VERSION "HNNBNNNYNNNNNNNNNNNNNNNNNNNNNNNNNNNNNNNNNN/4/%%%/4/'%**4NNN///"

NS_ :

BS_:

BU_: AEM BAP_Tester E_Sound FLA Gateway Gateway_PAG ISE MRR_HL MRR_HR NightVision RDK SAK SAK2 SCR STH_MLBevo TopView

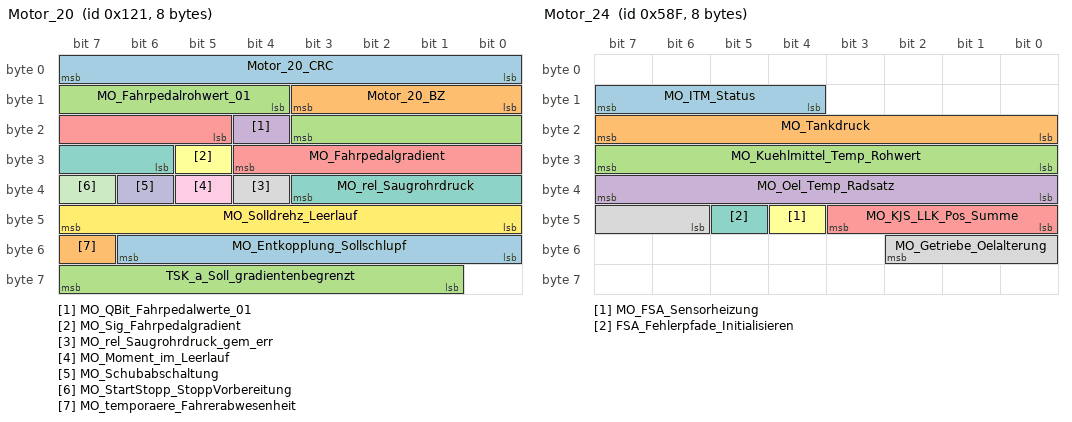
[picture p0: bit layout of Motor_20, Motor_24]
BO_ 289 Motor_20: 8 Gateway
 SG_ Motor_20_CRC : 0|8@1+ (1,0) [0|255] ""  Vector__XXX
 SG_ Motor_20_BZ : 8|4@1+ (1,0) [0|15] ""  Vector__XXX
 SG_ MO_Fahrpedalrohwert_01 : 12|8@1+ (0.4,0) [0.0|101.6] "Unit_PerCent"  E_Sound,ISE,SAK,SAK2
 SG_ MO_QBit_Fahrpedalwerte_01 : 20|1@1+ (1.0,0.0) [0.0|1] ""  Vector__XXX
 SG_ MO_Fahrpedalgradient : 21|8@1+ (25,0) [0|6350] "Unit_PerCentPerSecon"  Vector__XXX
 SG_ MO_Sig_Fahrpedalgradient : 29|1@1+ (1.0,0.0) [0.0|1] ""  Vector__XXX
 SG_ MO_rel_Saugrohrdruck : 30|6@1+ (18,0) [0|1116] "Unit_MilliBar"  Vector__XXX
 SG_ MO_rel_Saugrohrdruck_gem_err : 36|1@1+ (1.0,0.0) [0.0|1] ""  Vector__XXX
 SG_ MO_Moment_im_Leerlauf : 37|1@1+ (1.0,0.0) [0.0|1] ""  Vector__XXX
 SG_ MO_Schubabschaltung : 38|1@1+ (1.0,0.0) [0.0|1] ""  Vector__XXX
 SG_ MO_StartStopp_StoppVorbereitung : 39|1@1+ (1.0,0.0) [0.0|1] ""  Vector__XXX
 SG_ MO_Solldrehz_Leerlauf : 40|8@1+ (10,0) [0|2540] "Unit_MinutInver"  Vector__XXX
 SG_ MO_Entkopplung_Sollschlupf : 48|7@1+ (20,0) [0|2480] "Unit_MinutInver"  Vector__XXX
 SG_ MO_temporaere_Fahrerabwesenheit : 55|1@1+ (1.0,0.0) [0.0|1] ""  Vector__XXX
 SG_ TSK_a_Soll_gradientenbegrenzt : 57|7@1+ (0.1,-7.2) [-7.2|5.4] "Unit_MeterPerSeconSquar"  Vector__XXX

BO_ 1423 Motor_24: 8 Gateway
 SG_ MO_ITM_Status : 12|4@1+ (1.0,0.0) [0.0|15] ""  Vector__XXX
 SG_ MO_Tankdruck : 16|8@1+ (2,-250) [-250|256] "Unit_MilliBar"  STH_MLBevo
 SG_ MO_Kuehlmittel_Temp_Rohwert : 24|8@1+ (0.75,-48) [-48.00|141.75] "Unit_DegreCelsi"  Vector__XXX
 SG_ MO_Oel_Temp_Radsatz : 32|8@1+ (1,-60) [-60|193] "Unit_DegreCelsi"  Vector__XXX
 SG_ MO_KJS_LLK_Pos_Summe : 40|4@1+ (10,0) [0|100] "Unit_PerCent"  Vector__XXX
 SG_ MO_FSA_Sensorheizung : 44|1@1+ (1.0,0.0) [0.0|1] ""  Vector__XXX
 SG_ FSA_Fehlerpfade_Initialisieren : 45|1@1+ (1.0,0.0) [0.0|1] ""  Vector__XXX
 SG_ MO_Getriebe_Oelalterung : 46|5@1+ (5,0) [0|100] "Unit_PerCent"  Vector__XXX

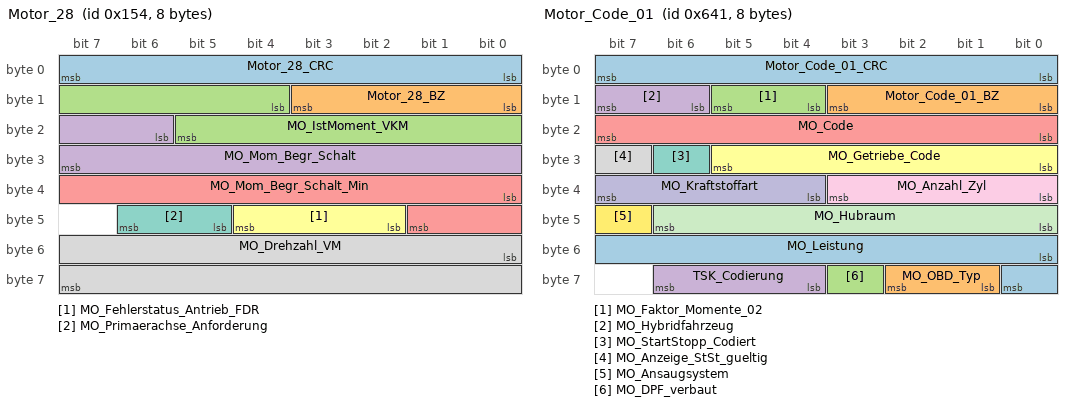
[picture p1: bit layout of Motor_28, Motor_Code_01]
BO_ 340 Motor_28: 8 Gateway
 SG_ Motor_28_CRC : 0|8@1+ (1,0) [0|255] ""  Vector__XXX
 SG_ Motor_28_BZ : 8|4@1+ (1,0) [0|15] ""  Vector__XXX
 SG_ MO_IstMoment_VKM : 12|10@1+ (1,-509) [-509|509] ""  Vector__XXX
 SG_ MO_Mom_Begr_Schalt : 22|10@1+ (1,-509) [-509|509] ""  Vector__XXX
 SG_ MO_Mom_Begr_Schalt_Min : 32|10@1+ (1,-509) [-509|509] ""  Vector__XXX
 SG_ MO_Fehlerstatus_Antrieb_FDR : 42|3@1+ (1.0,0.0) [0.0|7] ""  Vector__XXX
 SG_ MO_Primaerachse_Anforderung : 45|2@1+ (1.0,0.0) [0.0|3] ""  Vector__XXX
 SG_ MO_Drehzahl_VM : 48|16@1+ (0.25,0) [0.00|16383.00] "Unit_MinutInver"  AEM

BO_ 1601 Motor_Code_01: 8 Gateway
 SG_ Motor_Code_01_CRC : 0|8@1+ (1,0) [0|255] ""  Vector__XXX
 SG_ Motor_Code_01_BZ : 8|4@1+ (1,0) [0|15] ""  Vector__XXX
 SG_ MO_Faktor_Momente_02 : 12|2@1+ (1,0) [1|3] "Unit_NewtoMeter"  AEM
 SG_ MO_Hybridfahrzeug : 14|2@1+ (1.0,0.0) [0.0|3] ""  Vector__XXX
 SG_ MO_Code : 16|8@1+ (1,0) [0|255] ""  E_Sound,ISE,SAK,SAK2
 SG_ MO_Getriebe_Code : 24|6@1+ (1.0,0.0) [0.0|63] ""  Vector__XXX
 SG_ MO_StartStopp_Codiert : 30|1@1+ (1.0,0.0) [0.0|1] ""  Vector__XXX
 SG_ MO_Anzeige_StSt_gueltig : 31|1@1+ (1.0,0.0) [0.0|1] ""  Vector__XXX
 SG_ MO_Anzahl_Zyl : 32|4@1+ (1.0,0.0) [0.0|15] ""  Vector__XXX
 SG_ MO_Kraftstoffart : 36|4@1+ (1.0,0.0) [0.0|15] ""  STH_MLBevo
 SG_ MO_Hubraum : 40|7@1+ (0.1,0) [0.0|12.7] "Unit_Liter"  Vector__XXX
 SG_ MO_Ansaugsystem : 47|1@1+ (1.0,0.0) [0.0|1] ""  Vector__XXX
 SG_ MO_Leistung : 48|9@1+ (1,0) [0|511] "Unit_KiloWatt"  SAK,SAK2
 SG_ MO_OBD_Typ : 57|2@1+ (1.0,0.0) [0.0|3] ""  SCR
 SG_ MO_DPF_verbaut : 59|1@1+ (1.0,0.0) [0.0|1] ""  Vector__XXX
 SG_ TSK_Codierung : 60|3@1+ (1.0,0.0) [0.0|7] ""  Vector__XXX

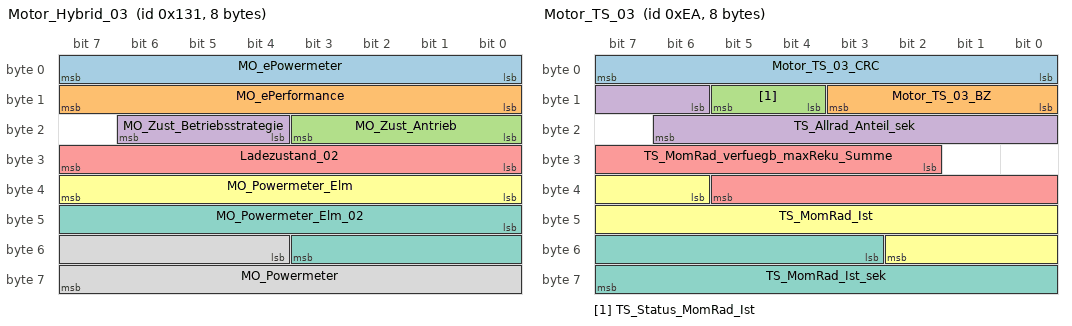
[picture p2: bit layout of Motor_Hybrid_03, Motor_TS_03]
BO_ 305 Motor_Hybrid_03: 8 Gateway
 SG_ MO_ePowermeter : 0|8@1+ (0.4,-0.4) [0.0|100.8] "Unit_PerCent"  Vector__XXX
 SG_ MO_ePerformance : 8|8@1+ (0.4,-0.4) [0.0|100.8] "Unit_PerCent"  Vector__XXX
 SG_ MO_Zust_Antrieb : 16|4@1+ (1.0,0.0) [0.0|15] ""  Vector__XXX
 SG_ MO_Zust_Betriebsstrategie : 20|3@1+ (1.0,0.0) [0.0|7] ""  Vector__XXX
 SG_ Ladezustand_02 : 24|8@1+ (0.5,0) [0.0|100.0] "Unit_PerCent"  Vector__XXX
 SG_ MO_Powermeter_Elm : 32|8@1+ (1,-128) [-100|100] "Unit_PerCent"  Vector__XXX
 SG_ MO_Powermeter_Elm_02 : 40|12@1+ (0.05,-102.4) [-100.00|100.00] "Unit_PerCent"  Vector__XXX
 SG_ MO_Powermeter : 52|12@1+ (1,0) [0|4092] ""  SAK,SAK2

BO_ 394 Motor_Hybrid_11: 8 Gateway
 SG_ MO_Ablaufstatus : 12|4@1+ (1.0,0.0) [0.0|15] ""  Vector__XXX
 SG_ MO_Ablaufstrg_Betriebszustand : 16|3@1+ (1.0,0.0) [0.0|7] ""  Vector__XXX
 SG_ MO_Ablaufstrg_Zustand_VKM_Ist : 19|1@1+ (1.0,0.0) [0.0|1] ""  Vector__XXX
 SG_ MO_Ablaufstrg_Kraftschluss_Ist : 20|1@1+ (1.0,0.0) [0.0|1] ""  Vector__XXX
 SG_ MO_Ablaufstrg_Zustand_K0_Ist : 21|1@1+ (1.0,0.0) [0.0|1] ""  Vector__XXX
 SG_ MO_Ablaufstrg_Kraftschluss2_Ist : 22|1@1+ (1.0,0.0) [0.0|1] ""  Vector__XXX
 SG_ MO_HYB_LowSpeedModus : 23|1@1+ (1.0,0.0) [0.0|1] ""  Vector__XXX
 SG_ MO_Ablaufstrg_Zustand_VKM_Ziel : 24|1@1+ (1.0,0.0) [0.0|1] ""  Vector__XXX
 SG_ MO_Ablaufstrg_Kraftschluss_Ziel : 25|1@1+ (1.0,0.0) [0.0|1] ""  Vector__XXX
 SG_ MO_Ablaufstrg_Zustand_K0_Ziel : 26|1@1+ (1.0,0.0) [0.0|1] ""  Vector__XXX
 SG_ MO_Ablaufstrg_Kraftschluss2_Ziel : 27|1@1+ (1.0,0.0) [0.0|1] ""  Vector__XXX
 SG_ MO_HYB_Stoppmodus : 28|1@1+ (1.0,0.0) [0.0|1] ""  Vector__XXX
 SG_ MO_Auth_Aufforderung_WFS : 29|1@1+ (1.0,0.0) [0.0|1] ""  Vector__XXX
 SG_ MO_Start_Dynamik : 30|3@1+ (1.0,0.0) [0.0|7] ""  Vector__XXX
 SG_ MO_Start_Art : 33|3@1+ (1.0,0.0) [0.0|7] ""  SCR
 SG_ MO_Abstellposition_02 : 36|8@1+ (2,0) [0|508] "Unit_DegreOfArc"  Vector__XXX
 SG_ MO_Mom_Freiheit_Sekundaerachse : 44|1@1+ (1.0,0.0) [0.0|1] ""  Vector__XXX
 SG_ MO_Nachlaufzeit_Kuehlerluefter : 45|6@1+ (15,0) [0|945] "Unit_Secon"  Vector__XXX
 SG_ MO_Tankklappensteuerung : 51|2@1+ (1.0,0.0) [0.0|3] ""  Vector__XXX
 SG_ MO_HYB_E_Faktor : 53|4@1+ (1.0,0.0) [0.0|15] ""  Vector__XXX
 SG_ MO_HYB_EMode_Info : 57|2@1+ (1.0,0.0) [0.0|3] ""  Vector__XXX
 SG_ MO_HYB_Adaption_aktiv : 59|1@1+ (1.0,0.0) [0.0|1] ""  Vector__XXX

BO_ 234 Motor_TS_03: 8 Gateway
 SG_ Motor_TS_03_CRC : 0|8@1+ (1,0) [0|255] ""  Vector__XXX
 SG_ Motor_TS_03_BZ : 8|4@1+ (1,0) [0|15] ""  Vector__XXX
 SG_ TS_Status_MomRad_Ist : 12|2@1+ (1.0,0.0) [0.0|3] ""  Vector__XXX
 SG_ TS_Allrad_Anteil_sek : 14|9@1+ (0.2,0) [0.0|100.0] "Unit_PerCent"  Vector__XXX
 SG_ TS_MomRad_verfuegb_maxReku_Summe : 26|12@1+ (3,-12279) [-12279|0] ""  Vector__XXX
 SG_ TS_MomRad_Ist : 38|13@1+ (3,-12279) [-12279|12279] "Unit_None"  Vector__XXX
 SG_ TS_MomRad_Ist_sek : 51|13@1+ (3,-12279) [-12279|12279] "Unit_None"  E_Sound,ISE

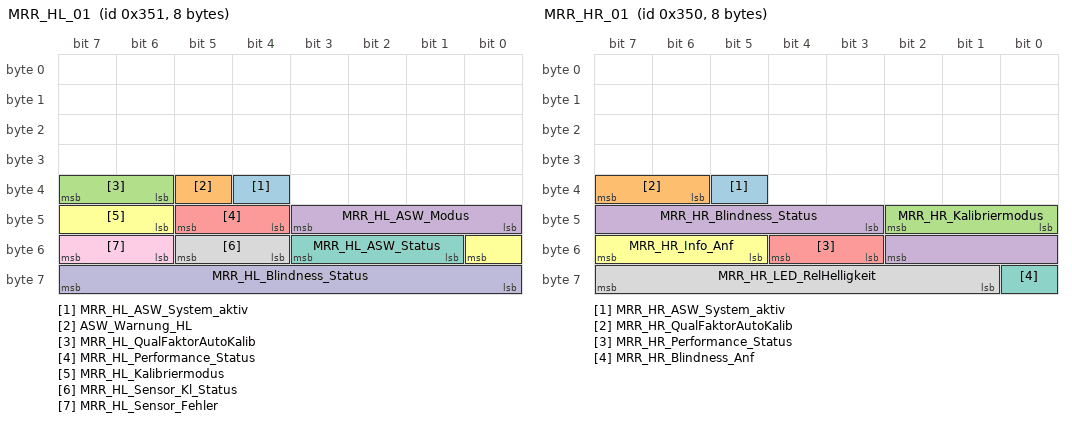
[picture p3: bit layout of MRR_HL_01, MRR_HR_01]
BO_ 849 MRR_HL_01: 8 MRR_HL
 SG_ MRR_HL_ASW_System_aktiv : 36|1@1+ (1.0,0.0) [0.0|1] ""  Gateway,Gateway_PAG,MRR_HR
 SG_ ASW_Warnung_HL : 37|1@1+ (1.0,0.0) [0.0|1] ""  Gateway,Gateway_PAG,MRR_HR
 SG_ MRR_HL_QualFaktorAutoKalib : 38|2@1+ (1.0,0.0) [0.0|3] ""  Gateway,Gateway_PAG,MRR_HR
 SG_ MRR_HL_ASW_Modus : 40|4@1+ (1.0,0.0) [0.0|15] ""  Gateway,Gateway_PAG,MRR_HR
 SG_ MRR_HL_Performance_Status : 44|2@1+ (1.0,0.0) [0.0|3] ""  Gateway,Gateway_PAG,MRR_HR
 SG_ MRR_HL_Kalibriermodus : 46|3@1+ (1.0,0.0) [0.0|7] ""  Gateway,Gateway_PAG,MRR_HR
 SG_ MRR_HL_ASW_Status : 49|3@1+ (1.0,0.0) [0.0|7] ""  Gateway,Gateway_PAG,MRR_HR
 SG_ MRR_HL_Sensor_Kl_Status : 52|2@1+ (1.0,0.0) [0.0|3] ""  Gateway,Gateway_PAG,MRR_HR
 SG_ MRR_HL_Sensor_Fehler : 54|2@1+ (1.0,0.0) [0.0|3] ""  Gateway,Gateway_PAG,MRR_HR
 SG_ MRR_HL_Blindness_Status : 56|8@1+ (1,0) [0|255] "Unit_None"  Gateway,Gateway_PAG,MRR_HR

BO_ 2463978596 MRR_HL_Info: 8 MRR_HL
 SG_ MRR_HL_Info1 : 0|32@1+ (1,0) [1|4294967295] "Unit_None"  MRR_HR

BO_ 848 MRR_HR_01: 8 MRR_HR
 SG_ MRR_HR_ASW_System_aktiv : 37|1@1+ (1.0,0.0) [0.0|1] ""  MRR_HL
 SG_ MRR_HR_QualFaktorAutoKalib : 38|2@1+ (1.0,0.0) [0.0|3] ""  MRR_HL
 SG_ MRR_HR_Kalibriermodus : 40|3@1+ (1.0,0.0) [0.0|7] ""  MRR_HL
 SG_ MRR_HR_Blindness_Status : 43|8@1+ (1,0) [0|255] "Unit_None"  MRR_HL
 SG_ MRR_HR_Performance_Status : 51|2@1+ (1.0,0.0) [0.0|3] ""  MRR_HL
 SG_ MRR_HR_Info_Anf : 53|3@1+ (1.0,0.0) [0.0|7] ""  MRR_HL
 SG_ MRR_HR_Blindness_Anf : 56|1@1+ (1.0,0.0) [0.0|1] ""  MRR_HL
 SG_ MRR_HR_LED_RelHelligkeit : 57|7@1+ (1,0) [0|127] "Unit_None"  MRR_HL

BO_ 1696 NightVision_01: 8 NightVision
 SG_ NV_aktiv : 12|1@1+ (1.0,0.0) [0.0|1] ""  Gateway,Gateway_PAG
 SG_ NV_Texte : 13|3@1+ (1.0,0.0) [0.0|7] ""  Gateway,Gateway_PAG
 SG_ NV_Gong : 16|2@1+ (1.0,0.0) [0.0|3] ""  Gateway,Gateway_PAG
 SG_ NV_Symbol : 18|1@1+ (1.0,0.0) [0.0|1] ""  Gateway,Gateway_PAG
 SG_ NV_Hinweise : 19|2@1+ (1.0,0.0) [0.0|3] ""  Gateway,Gateway_PAG
 SG_ NV_Piktogramm_aktiv : 21|1@1+ (1.0,0.0) [0.0|1] ""  Gateway,Gateway_PAG
 SG_ NV_Akustik_deaktiviert_Icon : 22|1@1+ (1.0,0.0) [0.0|1] ""  Gateway,Gateway_PAG
 SG_ NV_FGM_deaktiviert_Icon : 23|1@1+ (1.0,0.0) [0.0|1] ""  Gateway,Gateway_PAG
 SG_ NV_Markierungslicht_links : 24|1@1+ (1.0,0.0) [0.0|1] ""  Gateway,Gateway_PAG
 SG_ NV_Markierungslicht_rechts : 25|1@1+ (1.0,0.0) [0.0|1] ""  Gateway,Gateway_PAG
 SG_ NV_Symbol_Tierwarnung : 26|1@1+ (1.0,0.0) [0.0|1] ""  Gateway,Gateway_PAG
 SG_ NV_Anf_Prefill : 27|1@1+ (1.0,0.0) [0.0|1] ""  Gateway,Gateway_PAG
 SG_ NV_HBA_Parameter : 28|2@1+ (1.0,0.0) [0.0|3] ""  Gateway,Gateway_PAG
 SG_ NV_LED_Leiste : 30|2@1+ (1.0,0.0) [0.0|3] ""  Gateway,Gateway_PAG
 SG_ NV_PreSense_Status : 32|2@1+ (1.0,0.0) [0.0|3] ""  Gateway,Gateway_PAG
 SG_ NV_PreSense_Modus_System : 34|1@1+ (1.0,0.0) [0.0|1] ""  Gateway,Gateway_PAG
 SG_ NV_PreSense_Modus_Warnung : 35|3@1+ (1.0,0.0) [0.0|7] ""  Gateway,Gateway_PAG
 SG_ NV_FAS_Fkt_Status : 38|2@1+ (1.0,0.0) [0.0|3] ""  Gateway,Gateway_PAG
 SG_ NV_Akt_Status_MMI : 40|2@1+ (1.0,0.0) [0.0|3] ""  Gateway,Gateway_PAG
 SG_ NV_AnforderungBildaufschaltung : 42|1@1+ (1.0,0.0) [0.0|1] ""  Gateway,Gateway_PAG

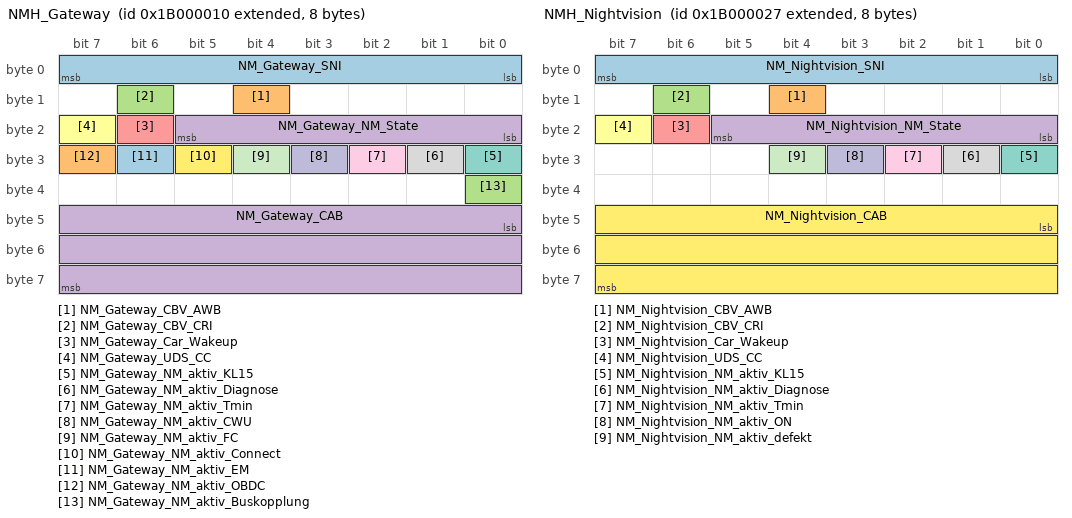
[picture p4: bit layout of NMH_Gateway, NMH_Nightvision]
BO_ 2600468496 NMH_Gateway: 8 Gateway
 SG_ NM_Gateway_SNI : 0|8@1+ (1.0,0.0) [0.0|255] ""  MRR_HL,MRR_HR,NightVision,RDK,SCR,STH_MLBevo,TopView
 SG_ NM_Gateway_CBV_AWB : 12|1@1+ (1.0,0.0) [0.0|1] ""  Vector__XXX
 SG_ NM_Gateway_CBV_CRI : 14|1@1+ (1.0,0.0) [0.0|1] ""  MRR_HL,MRR_HR,NightVision,RDK,SCR,STH_MLBevo,TopView
 SG_ NM_Gateway_NM_State : 16|6@1+ (1.0,0.0) [0.0|63] ""  Vector__XXX
 SG_ NM_Gateway_Car_Wakeup : 22|1@1+ (1.0,0.0) [0.0|1] ""  Vector__XXX
 SG_ NM_Gateway_UDS_CC : 23|1@1+ (1.0,0.0) [0.0|1] ""  Vector__XXX
 SG_ NM_Gateway_NM_aktiv_KL15 : 24|1@1+ (1.0,0.0) [0.0|1] ""  Vector__XXX
 SG_ NM_Gateway_NM_aktiv_Diagnose : 25|1@1+ (1.0,0.0) [0.0|1] ""  Vector__XXX
 SG_ NM_Gateway_NM_aktiv_Tmin : 26|1@1+ (1.0,0.0) [0.0|1] ""  Vector__XXX
 SG_ NM_Gateway_NM_aktiv_CWU : 27|1@1+ (1.0,0.0) [0.0|1] ""  Vector__XXX
 SG_ NM_Gateway_NM_aktiv_FC : 28|1@1+ (1.0,0.0) [0.0|1] ""  Vector__XXX
 SG_ NM_Gateway_NM_aktiv_Connect : 29|1@1+ (1.0,0.0) [0.0|1] ""  Vector__XXX
 SG_ NM_Gateway_NM_aktiv_EM : 30|1@1+ (1.0,0.0) [0.0|1] ""  Vector__XXX
 SG_ NM_Gateway_NM_aktiv_OBDC : 31|1@1+ (1.0,0.0) [0.0|1] ""  Vector__XXX
 SG_ NM_Gateway_NM_aktiv_Buskopplung : 32|1@1+ (1.0,0.0) [0.0|1] ""  Vector__XXX
 SG_ NM_Gateway_CAB : 40|24@1+ (1.0,0.0) [0.0|16777215] ""  MRR_HL,MRR_HR,NightVision,RDK,SCR,STH_MLBevo,TopView

BO_ 2600468519 NMH_Nightvision: 8 NightVision
 SG_ NM_Nightvision_SNI : 0|8@1+ (1.0,0.0) [0.0|255] ""  Gateway,Gateway_PAG,MRR_HL,MRR_HR,RDK,SCR,STH_MLBevo,TopView
 SG_ NM_Nightvision_CBV_AWB : 12|1@1+ (1.0,0.0) [0.0|1] ""  Gateway,Gateway_PAG
 SG_ NM_Nightvision_CBV_CRI : 14|1@1+ (1.0,0.0) [0.0|1] ""  Gateway,Gateway_PAG,MRR_HL,MRR_HR,RDK,SCR,STH_MLBevo,TopView
 SG_ NM_Nightvision_NM_State : 16|6@1+ (1.0,0.0) [0.0|63] ""  Vector__XXX
 SG_ NM_Nightvision_Car_Wakeup : 22|1@1+ (1.0,0.0) [0.0|1] ""  Gateway
 SG_ NM_Nightvision_UDS_CC : 23|1@1+ (1.0,0.0) [0.0|1] ""  Vector__XXX
 SG_ NM_Nightvision_NM_aktiv_KL15 : 24|1@1+ (1.0,0.0) [0.0|1] ""  Vector__XXX
 SG_ NM_Nightvision_NM_aktiv_Diagnose : 25|1@1+ (1.0,0.0) [0.0|1] ""  Vector__XXX
 SG_ NM_Nightvision_NM_aktiv_Tmin : 26|1@1+ (1.0,0.0) [0.0|1] ""  Vector__XXX
 SG_ NM_Nightvision_NM_aktiv_ON : 27|1@1+ (1.0,0.0) [0.0|1] ""  Vector__XXX
 SG_ NM_Nightvision_NM_aktiv_defekt : 28|1@1+ (1.0,0.0) [0.0|1] ""  Vector__XXX
 SG_ NM_Nightvision_CAB : 40|24@1+ (1.0,0.0) [0.0|16777215] ""  Gateway,Gateway_PAG,MRR_HL,MRR_HR,RDK,SCR,STH_MLBevo,TopView

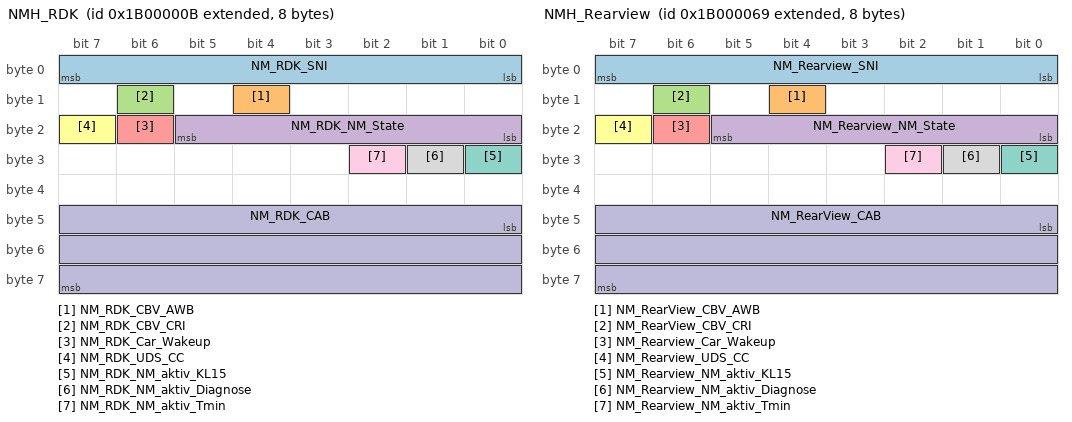
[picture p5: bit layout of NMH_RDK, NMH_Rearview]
BO_ 2600468491 NMH_RDK: 8 RDK
 SG_ NM_RDK_SNI : 0|8@1+ (1.0,0.0) [0.0|255] ""  Gateway,Gateway_PAG,MRR_HL,MRR_HR,NightVision,SCR,STH_MLBevo,TopView
 SG_ NM_RDK_CBV_AWB : 12|1@1+ (1.0,0.0) [0.0|1] ""  Gateway,Gateway_PAG
 SG_ NM_RDK_CBV_CRI : 14|1@1+ (1.0,0.0) [0.0|1] ""  Gateway,Gateway_PAG,MRR_HL,MRR_HR,NightVision,SCR,STH_MLBevo,TopView
 SG_ NM_RDK_NM_State : 16|6@1+ (1.0,0.0) [0.0|63] ""  Vector__XXX
 SG_ NM_RDK_Car_Wakeup : 22|1@1+ (1.0,0.0) [0.0|1] ""  Gateway,Gateway_PAG
 SG_ NM_RDK_UDS_CC : 23|1@1+ (1.0,0.0) [0.0|1] ""  Vector__XXX
 SG_ NM_RDK_NM_aktiv_KL15 : 24|1@1+ (1.0,0.0) [0.0|1] ""  Vector__XXX
 SG_ NM_RDK_NM_aktiv_Diagnose : 25|1@1+ (1.0,0.0) [0.0|1] ""  Vector__XXX
 SG_ NM_RDK_NM_aktiv_Tmin : 26|1@1+ (1.0,0.0) [0.0|1] ""  Vector__XXX
 SG_ NM_RDK_CAB : 40|24@1+ (1.0,0.0) [0.0|16777215] ""  Gateway,Gateway_PAG,MRR_HL,MRR_HR,NightVision,SCR,STH_MLBevo,TopView

BO_ 2600468585 NMH_Rearview: 8 TopView
 SG_ NM_Rearview_SNI : 0|8@1+ (1.0,0.0) [0.0|255] ""  Gateway,Gateway_PAG,MRR_HL,MRR_HR,NightVision,RDK,SCR,STH_MLBevo
 SG_ NM_RearView_CBV_AWB : 12|1@1+ (1.0,0.0) [0.0|1] ""  Gateway,Gateway_PAG
 SG_ NM_RearView_CBV_CRI : 14|1@1+ (1.0,0.0) [0.0|1] ""  Gateway,Gateway_PAG,MRR_HL,MRR_HR,NightVision,RDK,SCR,STH_MLBevo
 SG_ NM_Rearview_NM_State : 16|6@1+ (1.0,0.0) [0.0|63] ""  Vector__XXX
 SG_ NM_Rearview_Car_Wakeup : 22|1@1+ (1.0,0.0) [0.0|1] ""  Gateway
 SG_ NM_Rearview_UDS_CC : 23|1@1+ (1.0,0.0) [0.0|1] ""  Vector__XXX
 SG_ NM_Rearview_NM_aktiv_KL15 : 24|1@1+ (1.0,0.0) [0.0|1] ""  Vector__XXX
 SG_ NM_Rearview_NM_aktiv_Diagnose : 25|1@1+ (1.0,0.0) [0.0|1] ""  Vector__XXX
 SG_ NM_Rearview_NM_aktiv_Tmin : 26|1@1+ (1.0,0.0) [0.0|1] ""  Vector__XXX
 SG_ NM_RearView_CAB : 40|24@1+ (1.0,0.0) [0.0|16777215] ""  Gateway,Gateway_PAG,MRR_HL,MRR_HR,NightVision,RDK,SCR,STH_MLBevo

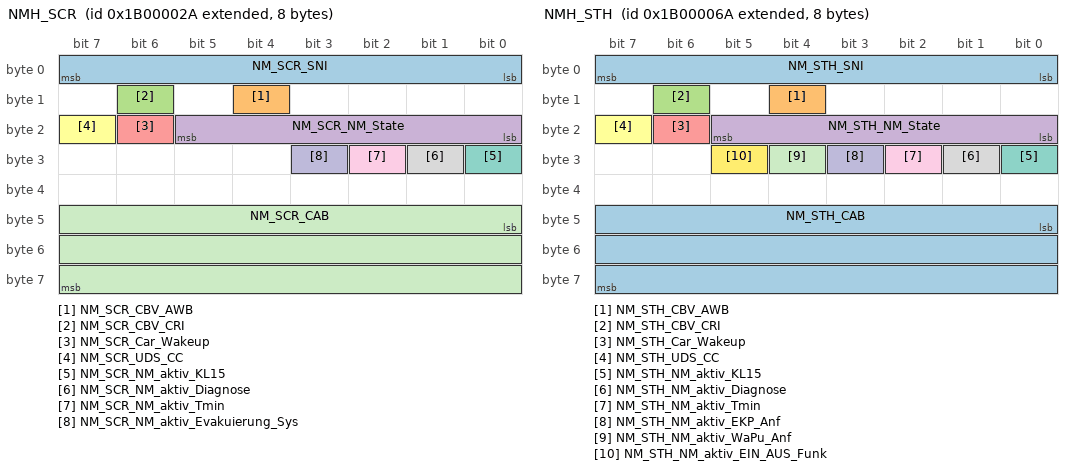
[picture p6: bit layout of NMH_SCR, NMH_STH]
BO_ 2600468522 NMH_SCR: 8 SCR
 SG_ NM_SCR_SNI : 0|8@1+ (1.0,0.0) [0.0|255] ""  Gateway,Gateway_PAG,MRR_HL,MRR_HR,NightVision,RDK,STH_MLBevo,TopView
 SG_ NM_SCR_CBV_AWB : 12|1@1+ (1.0,0.0) [0.0|1] ""  Gateway,Gateway_PAG
 SG_ NM_SCR_CBV_CRI : 14|1@1+ (1.0,0.0) [0.0|1] ""  Gateway,Gateway_PAG,MRR_HL,MRR_HR,NightVision,RDK,STH_MLBevo,TopView
 SG_ NM_SCR_NM_State : 16|6@1+ (1.0,0.0) [0.0|63] ""  Vector__XXX
 SG_ NM_SCR_Car_Wakeup : 22|1@1+ (1.0,0.0) [0.0|1] ""  Gateway,Gateway_PAG
 SG_ NM_SCR_UDS_CC : 23|1@1+ (1.0,0.0) [0.0|1] ""  Vector__XXX
 SG_ NM_SCR_NM_aktiv_KL15 : 24|1@1+ (1.0,0.0) [0.0|1] ""  Vector__XXX
 SG_ NM_SCR_NM_aktiv_Diagnose : 25|1@1+ (1.0,0.0) [0.0|1] ""  Vector__XXX
 SG_ NM_SCR_NM_aktiv_Tmin : 26|1@1+ (1.0,0.0) [0.0|1] ""  Vector__XXX
 SG_ NM_SCR_NM_aktiv_Evakuierung_Sys : 27|1@1+ (1.0,0.0) [0.0|1] ""  Vector__XXX
 SG_ NM_SCR_CAB : 40|24@1+ (1.0,0.0) [0.0|16777215] ""  Gateway,Gateway_PAG,MRR_HL,MRR_HR,NightVision,RDK,STH_MLBevo,TopView

BO_ 2600468586 NMH_STH: 8 STH_MLBevo
 SG_ NM_STH_SNI : 0|8@1+ (1.0,0.0) [0.0|255] ""  Gateway,Gateway_PAG,MRR_HL,MRR_HR,NightVision,RDK,SCR,TopView
 SG_ NM_STH_CBV_AWB : 12|1@1+ (1.0,0.0) [0.0|1] ""  Gateway,Gateway_PAG
 SG_ NM_STH_CBV_CRI : 14|1@1+ (1.0,0.0) [0.0|1] ""  Gateway,Gateway_PAG,MRR_HL,MRR_HR,NightVision,RDK,SCR,TopView
 SG_ NM_STH_NM_State : 16|6@1+ (1.0,0.0) [0.0|63] ""  Vector__XXX
 SG_ NM_STH_Car_Wakeup : 22|1@1+ (1.0,0.0) [0.0|1] ""  Gateway,Gateway_PAG
 SG_ NM_STH_UDS_CC : 23|1@1+ (1.0,0.0) [0.0|1] ""  Vector__XXX
 SG_ NM_STH_NM_aktiv_KL15 : 24|1@1+ (1.0,0.0) [0.0|1] ""  Vector__XXX
 SG_ NM_STH_NM_aktiv_Diagnose : 25|1@1+ (1.0,0.0) [0.0|1] ""  Vector__XXX
 SG_ NM_STH_NM_aktiv_Tmin : 26|1@1+ (1.0,0.0) [0.0|1] ""  Vector__XXX
 SG_ NM_STH_NM_aktiv_EKP_Anf : 27|1@1+ (1.0,0.0) [0.0|1] ""  Vector__XXX
 SG_ NM_STH_NM_aktiv_WaPu_Anf : 28|1@1+ (1.0,0.0) [0.0|1] ""  Vector__XXX
 SG_ NM_STH_NM_aktiv_EIN_AUS_Funk : 29|1@1+ (1.0,0.0) [0.0|1] ""  Vector__XXX
 SG_ NM_STH_CAB : 40|24@1+ (1.0,0.0) [0.0|16777215] ""  Gateway,Gateway_PAG,MRR_HL,MRR_HR,NightVision,RDK,SCR,TopView

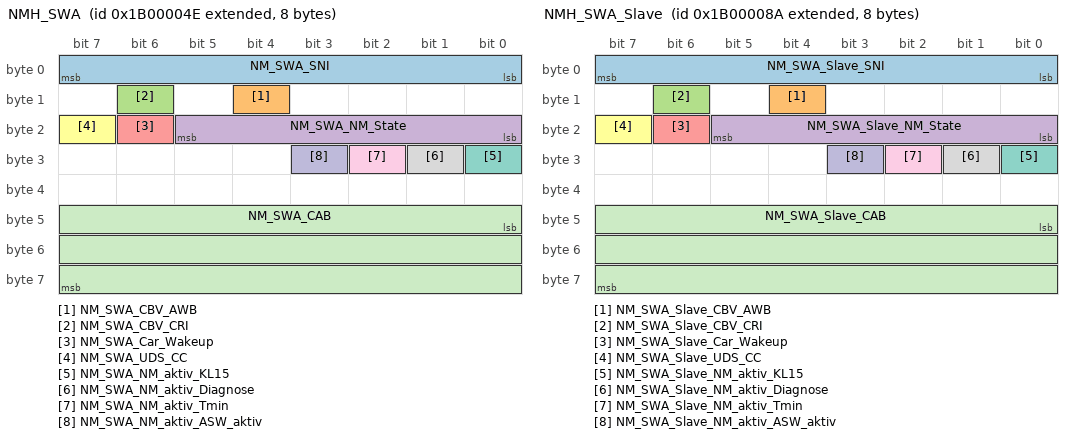
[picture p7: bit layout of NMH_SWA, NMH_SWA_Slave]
BO_ 2600468558 NMH_SWA: 8 MRR_HR
 SG_ NM_SWA_SNI : 0|8@1+ (1.0,0.0) [0.0|255] ""  Gateway,Gateway_PAG,MRR_HL,NightVision,RDK,SCR,STH_MLBevo,TopView
 SG_ NM_SWA_CBV_AWB : 12|1@1+ (1.0,0.0) [0.0|1] ""  Gateway,Gateway_PAG
 SG_ NM_SWA_CBV_CRI : 14|1@1+ (1.0,0.0) [0.0|1] ""  Gateway,Gateway_PAG,MRR_HL,NightVision,RDK,SCR,STH_MLBevo,TopView
 SG_ NM_SWA_NM_State : 16|6@1+ (1.0,0.0) [0.0|63] ""  Vector__XXX
 SG_ NM_SWA_Car_Wakeup : 22|1@1+ (1.0,0.0) [0.0|1] ""  Gateway,Gateway_PAG
 SG_ NM_SWA_UDS_CC : 23|1@1+ (1.0,0.0) [0.0|1] ""  Vector__XXX
 SG_ NM_SWA_NM_aktiv_KL15 : 24|1@1+ (1.0,0.0) [0.0|1] ""  Vector__XXX
 SG_ NM_SWA_NM_aktiv_Diagnose : 25|1@1+ (1.0,0.0) [0.0|1] ""  Vector__XXX
 SG_ NM_SWA_NM_aktiv_Tmin : 26|1@1+ (1.0,0.0) [0.0|1] ""  Vector__XXX
 SG_ NM_SWA_NM_aktiv_ASW_aktiv : 27|1@1+ (1.0,0.0) [0.0|1] ""  Vector__XXX
 SG_ NM_SWA_CAB : 40|24@1+ (1.0,0.0) [0.0|16777215] ""  Gateway,Gateway_PAG,MRR_HL,NightVision,RDK,SCR,STH_MLBevo,TopView

BO_ 2600468618 NMH_SWA_Slave: 8 MRR_HL
 SG_ NM_SWA_Slave_SNI : 0|8@1+ (1.0,0.0) [0.0|255] ""  Gateway,Gateway_PAG,MRR_HR,NightVision,RDK,SCR,STH_MLBevo,TopView
 SG_ NM_SWA_Slave_CBV_AWB : 12|1@1+ (1.0,0.0) [0.0|1] ""  Gateway,Gateway_PAG
 SG_ NM_SWA_Slave_CBV_CRI : 14|1@1+ (1.0,0.0) [0.0|1] ""  Gateway,Gateway_PAG,MRR_HR,NightVision,RDK,SCR,STH_MLBevo,TopView
 SG_ NM_SWA_Slave_NM_State : 16|6@1+ (1.0,0.0) [0.0|63] ""  Vector__XXX
 SG_ NM_SWA_Slave_Car_Wakeup : 22|1@1+ (1.0,0.0) [0.0|1] ""  Gateway
 SG_ NM_SWA_Slave_UDS_CC : 23|1@1+ (1.0,0.0) [0.0|1] ""  Vector__XXX
 SG_ NM_SWA_Slave_NM_aktiv_KL15 : 24|1@1+ (1.0,0.0) [0.0|1] ""  Vector__XXX
 SG_ NM_SWA_Slave_NM_aktiv_Diagnose : 25|1@1+ (1.0,0.0) [0.0|1] ""  Vector__XXX
 SG_ NM_SWA_Slave_NM_aktiv_Tmin : 26|1@1+ (1.0,0.0) [0.0|1] ""  Vector__XXX
 SG_ NM_SWA_Slave_NM_aktiv_ASW_aktiv : 27|1@1+ (1.0,0.0) [0.0|1] ""  Vector__XXX
 SG_ NM_SWA_Slave_CAB : 40|24@1+ (1.0,0.0) [0.0|16777215] ""  Gateway,Gateway_PAG,MRR_HR,NightVision,RDK,SCR,STH_MLBevo,TopView

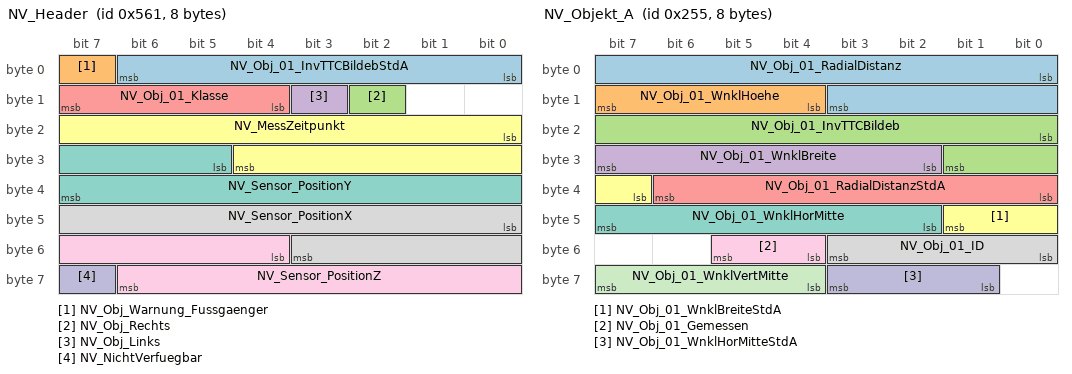
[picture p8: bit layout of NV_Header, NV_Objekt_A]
BO_ 1377 NV_Header: 8 NightVision
 SG_ NV_Obj_01_InvTTCBildebStdA : 0|7@1+ (0.0625,0) [0.0000|7.8750] "Unit_Hertz"  Gateway,Gateway_PAG
 SG_ NV_Obj_Warnung_Fussgaenger : 7|1@1+ (1.0,0.0) [0.0|1] ""  Gateway,Gateway_PAG
 SG_ NV_Obj_Rechts : 10|1@1+ (1.0,0.0) [0.0|1] ""  Gateway,Gateway_PAG
 SG_ NV_Obj_Links : 11|1@1+ (1.0,0.0) [0.0|1] ""  Gateway,Gateway_PAG
 SG_ NV_Obj_01_Klasse : 12|4@1+ (1.0,0.0) [0.0|15] ""  Gateway,Gateway_PAG
 SG_ NV_MessZeitpunkt : 16|13@1+ (0.001,0) [0.000|8.190] "Unit_Secon"  Gateway,Gateway_PAG
 SG_ NV_Sensor_PositionY : 29|11@1+ (0.001,-1) [-1.000|1.046] "Unit_Meter"  Gateway,Gateway_PAG
 SG_ NV_Sensor_PositionX : 40|12@1+ (0.001,1) [1.000|5.094] "Unit_Meter"  Gateway,Gateway_PAG
 SG_ NV_Sensor_PositionZ : 52|11@1+ (0.001,0) [0.000|2.046] "Unit_Meter"  Gateway,Gateway_PAG
 SG_ NV_NichtVerfuegbar : 63|1@1+ (1.0,0.0) [0.0|1] ""  Gateway,Gateway_PAG

BO_ 597 NV_Objekt_A: 8 NightVision
 SG_ NV_Obj_01_RadialDistanz : 0|12@1+ (0.0625,0) [0.0000|255.8750] "Unit_Meter"  Gateway,Gateway_PAG
 SG_ NV_Obj_01_WnklHoehe : 12|4@1+ (0.03125,0) [0.00000|0.43750] "Unit_Radia"  Gateway,Gateway_PAG
 SG_ NV_Obj_01_InvTTCBildeb : 16|10@1+ (0.015625,-8) [-8.000000|7.968750] "Unit_Hertz"  Gateway,Gateway_PAG
 SG_ NV_Obj_01_WnklBreite : 26|6@1+ (0.0078125,0) [0E-7|0.4843750] "Unit_Radia"  Gateway,Gateway_PAG
 SG_ NV_Obj_01_RadialDistanzStdA : 32|7@1+ (0.25,0) [0.00|31.50] "Unit_Meter"  Gateway,Gateway_PAG
 SG_ NV_Obj_01_WnklBreiteStdA : 39|3@1+ (0.015625,0) [0.000000|0.093750] "Unit_Radia"  Gateway,Gateway_PAG
 SG_ NV_Obj_01_WnklHorMitte : 42|6@1+ (0.0078125,-0.2421875) [-0.2421875|0.2421875] "Unit_Radia"  Gateway,Gateway_PAG
 SG_ NV_Obj_01_ID : 48|4@1+ (1.0,0.0) [0.0|15] ""  Gateway,Gateway_PAG
 SG_ NV_Obj_01_Gemessen : 52|2@1+ (1.0,0.0) [0.0|3] ""  Gateway,Gateway_PAG
 SG_ NV_Obj_01_WnklHorMitteStdA : 57|3@1+ (0.015625,0) [0.000000|0.093750] "Unit_Radia"  Gateway,Gateway_PAG
 SG_ NV_Obj_01_WnklVertMitte : 60|4@1+ (0.03125,-0.21875) [-0.21875|0.21875] "Unit_Radia"  Gateway,Gateway_PAG

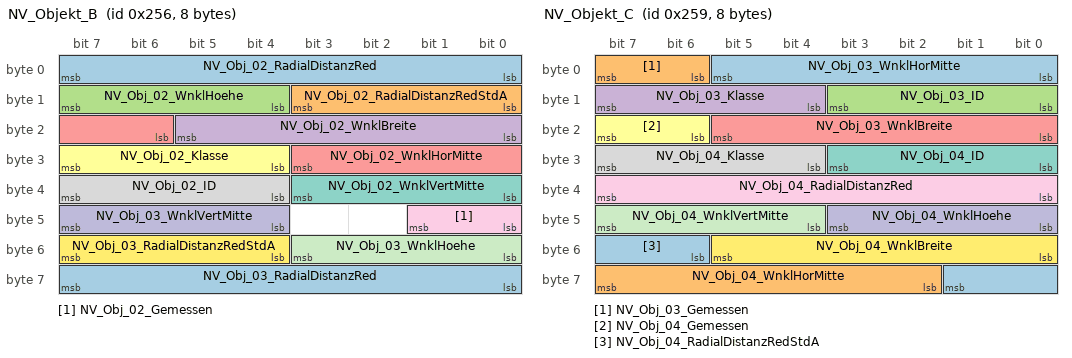
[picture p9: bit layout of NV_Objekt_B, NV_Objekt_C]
BO_ 598 NV_Objekt_B: 8 NightVision
 SG_ NV_Obj_02_RadialDistanzRed : 0|8@1+ (0.5,3) [3.0|130.0] "Unit_Meter"  Gateway,Gateway_PAG
 SG_ NV_Obj_02_RadialDistanzRedStdA : 8|4@1+ (1,0) [0|14] "Unit_Meter"  Gateway,Gateway_PAG
 SG_ NV_Obj_02_WnklHoehe : 12|4@1+ (0.03125,0) [0.00000|0.43750] "Unit_Radia"  Gateway,Gateway_PAG
 SG_ NV_Obj_02_WnklBreite : 16|6@1+ (0.0078125,0) [0E-7|0.4843750] "Unit_Radia"  Gateway,Gateway_PAG
 SG_ NV_Obj_02_WnklHorMitte : 22|6@1+ (0.0078125,-0.2421875) [-0.2421875|0.2421875] "Unit_Radia"  Gateway,Gateway_PAG
 SG_ NV_Obj_02_Klasse : 28|4@1+ (1.0,0.0) [0.0|15] ""  Gateway,Gateway_PAG
 SG_ NV_Obj_02_WnklVertMitte : 32|4@1+ (0.03125,-0.21875) [-0.21875|0.21875] "Unit_Radia"  Gateway,Gateway_PAG
 SG_ NV_Obj_02_ID : 36|4@1+ (1.0,0.0) [0.0|15] ""  Gateway,Gateway_PAG
 SG_ NV_Obj_02_Gemessen : 40|2@1+ (1.0,0.0) [0.0|3] ""  Gateway,Gateway_PAG
 SG_ NV_Obj_03_WnklVertMitte : 44|4@1+ (0.03125,-0.21875) [-0.21875|0.21875] "Unit_Radia"  Gateway,Gateway_PAG
 SG_ NV_Obj_03_WnklHoehe : 48|4@1+ (0.03125,0) [0.00000|0.43750] "Unit_Radia"  Gateway,Gateway_PAG
 SG_ NV_Obj_03_RadialDistanzRedStdA : 52|4@1+ (1,0) [0|14] "Unit_Meter"  Gateway,Gateway_PAG
 SG_ NV_Obj_03_RadialDistanzRed : 56|8@1+ (0.5,3) [3.0|130.0] "Unit_Meter"  Gateway,Gateway_PAG

BO_ 601 NV_Objekt_C: 8 NightVision
 SG_ NV_Obj_03_WnklHorMitte : 0|6@1+ (0.0078125,-0.2421875) [-0.2421875|0.2421875] "Unit_Radia"  Gateway,Gateway_PAG
 SG_ NV_Obj_03_Gemessen : 6|2@1+ (1.0,0.0) [0.0|3] ""  Gateway,Gateway_PAG
 SG_ NV_Obj_03_ID : 8|4@1+ (1.0,0.0) [0.0|15] ""  Gateway,Gateway_PAG
 SG_ NV_Obj_03_Klasse : 12|4@1+ (1.0,0.0) [0.0|15] ""  Gateway,Gateway_PAG
 SG_ NV_Obj_03_WnklBreite : 16|6@1+ (0.0078125,0) [0E-7|0.4843750] "Unit_Radia"  Gateway,Gateway_PAG
 SG_ NV_Obj_04_Gemessen : 22|2@1+ (1.0,0.0) [0.0|3] ""  Gateway,Gateway_PAG
 SG_ NV_Obj_04_ID : 24|4@1+ (1.0,0.0) [0.0|15] ""  Gateway,Gateway_PAG
 SG_ NV_Obj_04_Klasse : 28|4@1+ (1.0,0.0) [0.0|15] ""  Gateway,Gateway_PAG
 SG_ NV_Obj_04_RadialDistanzRed : 32|8@1+ (0.5,3) [3.0|130.0] "Unit_Meter"  Gateway,Gateway_PAG
 SG_ NV_Obj_04_WnklHoehe : 40|4@1+ (0.03125,0) [0.00000|0.43750] "Unit_Radia"  Gateway,Gateway_PAG
 SG_ NV_Obj_04_WnklVertMitte : 44|4@1+ (0.03125,-0.21875) [-0.21875|0.21875] "Unit_Radia"  Gateway,Gateway_PAG
 SG_ NV_Obj_04_WnklBreite : 48|6@1+ (0.0078125,0) [0E-7|0.4843750] "Unit_Radia"  Gateway,Gateway_PAG
 SG_ NV_Obj_04_RadialDistanzRedStdA : 54|4@1+ (1,0) [0|14] "Unit_Meter"  Gateway,Gateway_PAG
 SG_ NV_Obj_04_WnklHorMitte : 58|6@1+ (0.0078125,-0.2421875) [-0.2421875|0.2421875] "Unit_Radia"  Gateway,Gateway_PAG

BO_ 1635 NVEM_02: 8 Gateway
 SG_ BEM_02_Abschaltstufen : 0|3@1+ (1.0,0.0) [0.0|7] ""  MRR_HL,MRR_HR,STH_MLBevo
 SG_ BEM_STH_Zielzeit : 3|4@1+ (5,0) [0|60] "Unit_Minut"  Vector__XXX
 SG_ BEM_MMI_Vorwarnung : 7|1@1+ (1.0,0.0) [0.0|1] ""  Vector__XXX
 SG_ NVEM_Anf_SD_schalten : 15|1@1+ (1.0,0.0) [0.0|1] ""  Vector__XXX
 SG_ BEM_Generatordiagnose : 16|2@1+ (1.0,0.0) [0.0|3] ""  Vector__XXX
 SG_ BEM_Red_Innengeblaese : 18|2@1+ (1.0,0.0) [0.0|3] ""  Vector__XXX
 SG_ BEM_STH_Einschaltverbot : 20|1@1+ (1.0,0.0) [0.0|1] ""  STH_MLBevo
 SG_ BEM_HL_Regelung_Status : 21|3@1+ (1.0,0.0) [0.0|7] ""  STH_MLBevo
 SG_ BEM_Ladezustand : 24|4@1+ (10,0) [0|100] "Unit_PerCent"  Vector__XXX
 SG_ BEM_Batteriediagnose : 28|3@1+ (1.0,0.0) [0.0|7] ""  Vector__XXX
 SG_ MIB_Stromsparmodus : 31|1@1+ (1.0,0.0) [0.0|1] ""  Vector__XXX
 SG_ BEM_REK_aktiv : 37|1@1+ (1.0,0.0) [0.0|1] ""  Vector__XXX
 SG_ NVEM_Last_Anf : 38|2@1+ (1.0,0.0) [0.0|3] ""  Vector__XXX
 SG_ BEM_UBDM : 40|8@1+ (0.05,5) [5.05|17.70] "Unit_Volt"  Vector__XXX
 SG_ BEM_UGenSoll : 48|6@1+ (0.1,10.6) [10.6|16.0] "Unit_Volt"  Vector__XXX
 SG_ BEM_Anf_KL15_schalten : 54|2@1+ (1.0,0.0) [0.0|3] ""  MRR_HL,MRR_HR
 SG_ NVEM_Batterie_Service : 56|2@1+ (1.0,0.0) [0.0|3] ""  Vector__XXX
 SG_ NVEM_Freigabe_OnlineUpdate : 58|1@1+ (1.0,0.0) [0.0|1] ""  Vector__XXX
 SG_ NVEM_Freigabe_ORU4 : 59|2@1+ (1.0,0.0) [0.0|3] ""  Vector__XXX

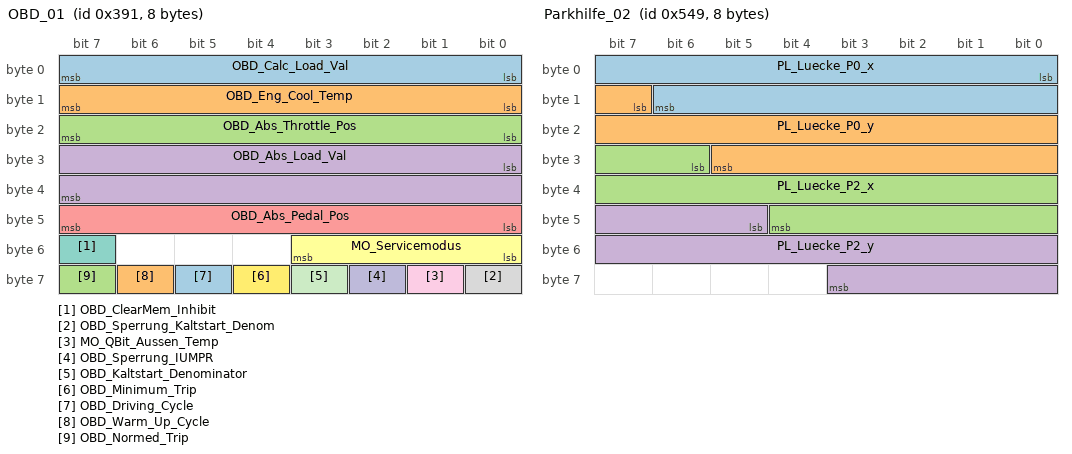
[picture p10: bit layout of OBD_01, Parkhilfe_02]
BO_ 913 OBD_01: 8 Gateway
 SG_ OBD_Calc_Load_Val : 0|8@1+ (0.39215686274509803,0) [0E-17|99.99999999999999765] "Unit_PerCent"  SCR
 SG_ OBD_Eng_Cool_Temp : 8|8@1+ (1,-40) [-40|215] "Unit_DegreCelsi"  SCR
 SG_ OBD_Abs_Throttle_Pos : 16|8@1+ (0.39215686274509803,0) [0E-17|99.99999999999999765] "Unit_PerCent"  SCR
 SG_ OBD_Abs_Load_Val : 24|16@1+ (0.39215686274509803,0) [0E-17|25699.99999999999939605] "Unit_PerCent"  SCR
 SG_ OBD_Abs_Pedal_Pos : 40|8@1+ (0.39215686274509803,0) [0E-17|99.99999999999999765] "Unit_PerCent"  SCR
 SG_ MO_Servicemodus : 48|4@1+ (1.0,0.0) [0.0|15] ""  Vector__XXX
 SG_ OBD_ClearMem_Inhibit : 55|1@1+ (1.0,0.0) [0.0|1] ""  Vector__XXX
 SG_ OBD_Sperrung_Kaltstart_Denom : 56|1@1+ (1.0,0.0) [0.0|1] ""  Vector__XXX
 SG_ MO_QBit_Aussen_Temp : 57|1@1+ (1.0,0.0) [0.0|1] ""  SCR
 SG_ OBD_Sperrung_IUMPR : 58|1@1+ (1.0,0.0) [0.0|1] ""  SCR
 SG_ OBD_Kaltstart_Denominator : 59|1@1+ (1.0,0.0) [0.0|1] ""  SCR
 SG_ OBD_Minimum_Trip : 60|1@1+ (1.0,0.0) [0.0|1] ""  SCR
 SG_ OBD_Driving_Cycle : 61|1@1+ (1.0,0.0) [0.0|1] ""  SCR
 SG_ OBD_Warm_Up_Cycle : 62|1@1+ (1.0,0.0) [0.0|1] ""  SCR
 SG_ OBD_Normed_Trip : 63|1@1+ (1.0,0.0) [0.0|1] ""  SCR

BO_ 2589283478 OBD_02: 8 Gateway
 SG_ OBD_Aussen_Temp_gef : 56|8@1+ (1,-40) [-40|213] "Unit_DegreCelsi"  SCR

BO_ 2549875246 OBDC_AEM_Req: 8 Gateway
 SG_ OBDC_AEM_Req_Data : 0|64@1+ (1.0,0.0) [0.0|18446744073709551615] ""  AEM

BO_ 2550006318 OBDC_AEM_Resp: 8 AEM
 SG_ OBDC_AEM_Resp_Data : 0|64@1+ (1.0,0.0) [0.0|18446744073709551615] ""  Gateway,Gateway_PAG

BO_ 2549875248 OBDC_FLA_Req: 8 Gateway
 SG_ OBDC_FLA_Req_Data : 0|64@1+ (1.0,0.0) [0.0|18446744073709551615] ""  FLA

BO_ 2550006320 OBDC_FLA_Resp: 8 FLA
 SG_ OBDC_FLA_Resp_Data : 0|64@1+ (1.0,0.0) [0.0|18446744073709551615] ""  Gateway,Gateway_PAG

BO_ 2549940736 OBDC_Funktionaler_Req_All: 8 Gateway
 SG_ OBDC_Funktionaler_Req_All_Data : 0|64@1+ (1.0,0.0) [0.0|18446744073709551615] ""  AEM,E_Sound,FLA,ISE,MRR_HL,MRR_HR,NightVision,RDK,SAK,SAK2,SCR,STH_MLBevo,TopView

BO_ 2549875239 OBDC_Nightvision_Req: 8 Gateway
 SG_ OBDC_Nightvision_Req_Data : 0|64@1+ (1.0,0.0) [0.0|18446744073709551615] ""  NightVision

BO_ 2550006311 OBDC_Nightvision_Resp: 8 NightVision
 SG_ OBDC_Nightvision_Resp_Data : 0|64@1+ (1.0,0.0) [0.0|18446744073709551615] ""  Gateway,Gateway_PAG

BO_ 2549875211 OBDC_RDK_Req: 8 Gateway
 SG_ OBDC_RDK_Req_Data : 0|64@1+ (1.0,0.0) [0.0|18446744073709551615] ""  RDK

BO_ 2550006283 OBDC_RDK_Resp: 8 RDK
 SG_ OBDC_RDK_Resp_Data : 0|64@1+ (1.0,0.0) [0.0|18446744073709551615] ""  Gateway,Gateway_PAG

BO_ 2549875305 OBDC_Rearview_Req: 8 Gateway
 SG_ OBDC_Rearview_Req_Data : 0|64@1+ (1.0,0.0) [0.0|18446744073709551615] ""  TopView

BO_ 2550006377 OBDC_Rearview_Resp: 8 TopView
 SG_ OBDC_Rearview_Resp_Data : 0|64@1+ (1.0,0.0) [0.0|18446744073709551615] ""  Gateway,Gateway_PAG

BO_ 2549875242 OBDC_SCR_Req: 8 Gateway
 SG_ OBDC_SCR_Req_Data : 0|64@1+ (1.0,0.0) [0.0|18446744073709551615] ""  SCR

BO_ 2550006314 OBDC_SCR_Resp: 8 SCR
 SG_ OBDC_SCR_Resp_Data : 0|64@1+ (1.0,0.0) [0.0|18446744073709551615] ""  Gateway,Gateway_PAG

BO_ 2549875300 OBDC_Soundaktor2_Req: 8 Gateway
 SG_ OBDC_Soundaktor2_Req_Data : 0|64@1+ (1.0,0.0) [0.0|18446744073709551615] ""  E_Sound,SAK2

BO_ 2550006372 OBDC_Soundaktor2_Resp: 8 E_Sound
 SG_ OBDC_Soundaktor2_Resp_Data : 0|64@1+ (1.0,0.0) [0.0|18446744073709551615] ""  Gateway,Gateway_PAG

BO_ 2549875228 OBDC_Soundaktor_Req: 8 Gateway
 SG_ OBDC_Soundaktor_Req_Data : 0|64@1+ (1.0,0.0) [0.0|18446744073709551615] ""  ISE,SAK

BO_ 2550006300 OBDC_Soundaktor_Resp: 8 ISE
 SG_ OBDC_Soundaktor_Resp_Data : 0|64@1+ (1.0,0.0) [0.0|18446744073709551615] ""  Gateway,Gateway_PAG

BO_ 2549875306 OBDC_STH_Req: 8 Gateway
 SG_ OBDC_STH_Req_Data : 0|64@1+ (1.0,0.0) [0.0|18446744073709551615] ""  STH_MLBevo

BO_ 2550006378 OBDC_STH_Resp: 8 STH_MLBevo
 SG_ OBDC_STH_Resp_Data : 0|64@1+ (1.0,0.0) [0.0|18446744073709551615] ""  Gateway,Gateway_PAG

BO_ 2549875338 OBDC_SWA_2_Req: 8 Gateway
 SG_ OBDC_SWA_2_Req_Data : 0|64@1+ (1.0,0.0) [0.0|18446744073709551615] ""  MRR_HL

BO_ 2550006410 OBDC_SWA_2_Resp: 8 MRR_HL
 SG_ OBDC_SWA_2_Resp_Data : 0|64@1+ (1.0,0.0) [0.0|18446744073709551615] ""  Gateway,Gateway_PAG

BO_ 2549875278 OBDC_SWA_Req: 8 Gateway
 SG_ OBDC_SWA_Req_Data : 0|64@1+ (1.0,0.0) [0.0|18446744073709551615] ""  MRR_HR

BO_ 2550006350 OBDC_SWA_Resp: 8 MRR_HR
 SG_ OBDC_SWA_Resp_Data : 0|64@1+ (1.0,0.0) [0.0|18446744073709551615] ""  Gateway,Gateway_PAG

BO_ 2589283656 ORU_01: 8 Gateway
 SG_ ORU_Warnung : 58|2@1+ (1.0,0.0) [0.0|3] ""  Vector__XXX
 SG_ ORU_Status : 61|3@1+ (1.0,0.0) [0.0|7] ""  Vector__XXX

BO_ 1175 Parkhilfe_01: 8 Gateway
 SG_ PH_Visualisierung : 0|3@1+ (1.0,0.0) [0.0|7] ""  TopView
 SG_ PDC_Tonausgabe_Front : 4|4@1+ (1.0,0.0) [0.0|15] ""  Vector__XXX
 SG_ PDC_Tonausgabe_Heck : 8|4@1+ (1.0,0.0) [0.0|15] ""  Vector__XXX
 SG_ PH_nachtr_Stopp_Anf : 12|1@1+ (1.0,0.0) [0.0|1] ""  Vector__XXX
 SG_ PH_Abschaltursache : 13|3@1+ (1.0,0.0) [0.0|7] ""  Vector__XXX
 SG_ PH_Opt_Anzeige_V_ein : 16|1@1+ (1.0,0.0) [0.0|1] ""  Vector__XXX
 SG_ PH_Opt_Anzeige_H_ein : 17|1@1+ (1.0,0.0) [0.0|1] ""  Vector__XXX
 SG_ PH_Opt_Anz_V_Hindernis : 18|1@1+ (1.0,0.0) [0.0|1] ""  Vector__XXX
 SG_ PH_Opt_Anz_H_Hindernis : 19|1@1+ (1.0,0.0) [0.0|1] ""  Vector__XXX
 SG_ PH_Tongeber_V_aktiv : 20|1@1+ (1.0,0.0) [0.0|1] ""  Vector__XXX
 SG_ PH_Tongeber_H_aktiv : 21|1@1+ (1.0,0.0) [0.0|1] ""  Vector__XXX
 SG_ PH_Tongeber_mute : 22|1@1+ (1.0,0.0) [0.0|1] ""  Vector__XXX
 SG_ PH_Anf_Audioabsenkung : 23|1@1+ (1.0,0.0) [0.0|1] ""  Vector__XXX
 SG_ PH_Tongeber_H_verfuegbar : 24|1@1+ (1.0,0.0) [0.0|1] ""  Vector__XXX
 SG_ PLA_Anf_Aufschaltung_RVC : 25|1@1+ (1.0,0.0) [0.0|1] ""  TopView
 SG_ PH_Taster : 28|2@1+ (1.0,0.0) [0.0|3] ""  TopView
 SG_ PH_Anf_Verdeck : 30|2@1+ (1.0,0.0) [0.0|3] ""  Vector__XXX
 SG_ PH_Frequenz_hinten : 32|4@1+ (1,0) [0|15] ""  Vector__XXX
 SG_ PH_Lautstaerke_hinten : 36|4@1+ (1,0) [0|15] ""  Vector__XXX
 SG_ PH_Frequenz_vorn : 40|4@1+ (1,0) [0|15] ""  Vector__XXX
 SG_ PH_Lautstaerke_vorn : 44|4@1+ (1,0) [0|15] ""  Vector__XXX
 SG_ PH_StartStopp_Info : 49|2@1+ (1.0,0.0) [0.0|3] ""  Vector__XXX
 SG_ PH_Stoermeldung : 52|4@1+ (1.0,0.0) [0.0|15] ""  Vector__XXX
 SG_ PH_defekt : 56|1@1+ (1.0,0.0) [0.0|1] ""  Vector__XXX
 SG_ PH_gestoert : 57|1@1+ (1.0,0.0) [0.0|1] ""  Vector__XXX
 SG_ PH_Systemzustand : 58|3@1+ (1.0,0.0) [0.0|7] ""  TopView
 SG_ PH_Display_Kundenwunsch : 61|2@1+ (1.0,0.0) [0.0|3] ""  Vector__XXX

BO_ 1353 Parkhilfe_02: 8 Gateway
 SG_ PL_Luecke_P0_x : 0|15@1+ (2,-32767) [-32767|32767] "Unit_Centimeter"  TopView
 SG_ PL_Luecke_P0_y : 15|15@1+ (2,-32767) [-32767|32767] "Unit_Centimeter"  TopView
 SG_ PL_Luecke_P2_x : 30|15@1+ (2,-32767) [-32767|32767] "Unit_Centimeter"  TopView
 SG_ PL_Luecke_P2_y : 45|15@1+ (2,-32767) [-32767|32767] "Unit_Centimeter"  TopView

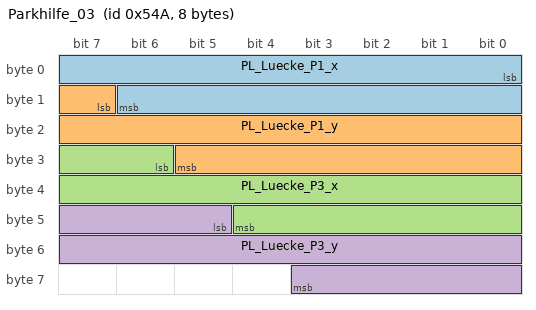
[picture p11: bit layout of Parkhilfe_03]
BO_ 1354 Parkhilfe_03: 8 Gateway
 SG_ PL_Luecke_P1_x : 0|15@1+ (2,-32767) [-32767|32767] "Unit_Centimeter"  TopView
 SG_ PL_Luecke_P1_y : 15|15@1+ (2,-32767) [-32767|32767] "Unit_Centimeter"  TopView
 SG_ PL_Luecke_P3_x : 30|15@1+ (2,-32767) [-32767|32767] "Unit_Centimeter"  TopView
 SG_ PL_Luecke_P3_y : 45|15@1+ (2,-32767) [-32767|32767] "Unit_Centimeter"  TopView

BO_TX_BU_ 289 :Gateway,Gateway_PAG;
BO_TX_BU_ 1423 :Gateway,Gateway_PAG;
BO_TX_BU_ 340 :Gateway,Gateway_PAG;
BO_TX_BU_ 1601 :Gateway,Gateway_PAG;
BO_TX_BU_ 305 :Gateway,Gateway_PAG;
BO_TX_BU_ 394 :Gateway,Gateway_PAG;
BO_TX_BU_ 234 :Gateway,Gateway_PAG;
BO_TX_BU_ 2600468496 :Gateway,Gateway_PAG;
BO_TX_BU_ 1635 :Gateway,Gateway_PAG;
BO_TX_BU_ 913 :Gateway,Gateway_PAG;
BO_TX_BU_ 2589283478 :Gateway,Gateway_PAG;
BO_TX_BU_ 2549875246 :Gateway,Gateway_PAG;
BO_TX_BU_ 2549875248 :Gateway,Gateway_PAG;
BO_TX_BU_ 2549940736 :Gateway,Gateway_PAG;
BO_TX_BU_ 2549875239 :Gateway,Gateway_PAG;
BO_TX_BU_ 2549875211 :Gateway,Gateway_PAG;
BO_TX_BU_ 2549875305 :Gateway,Gateway_PAG;
BO_TX_BU_ 2549875242 :Gateway,Gateway_PAG;
BO_TX_BU_ 2549875300 :Gateway,Gateway_PAG;
BO_TX_BU_ 2550006372 :E_Sound,SAK2;
BO_TX_BU_ 2549875228 :Gateway,Gateway_PAG;
BO_TX_BU_ 2550006300 :ISE,SAK;
BO_TX_BU_ 2549875306 :Gateway,Gateway_PAG;
BO_TX_BU_ 2549875338 :Gateway,Gateway_PAG;
BO_TX_BU_ 2549875278 :Gateway,Gateway_PAG;
BO_TX_BU_ 2589283656 :Gateway,Gateway_PAG;
BO_TX_BU_ 1175 :Gateway,Gateway_PAG;
BO_TX_BU_ 1353 :Gateway,Gateway_PAG;
BO_TX_BU_ 1354 :Gateway,Gateway_PAG;
CM_ BO_ 1423 "CAN-Botschaft";
CM_ BO_ 1601 "ab MQB mit CRC-8";
CM_ BO_ 1696 "MLBevo ohne KD-Bit";
CM_ BO_ 2600468519 "CAN_NM_PDU MLBevo";
CM_ BO_ 2600468522 "CAN_NM_PDU MLBevo";
CM_ BO_ 2600468558 "CAN_NM_PDU MLBevo";
CM_ BO_ 1635 "DLC=8 ab D4 gültig";
CM_ BO_ 2549940736 "VDC funktionaler Request auf CANHS";
CM_ BO_ 1175 "neue Struktur ab MQB ohne KD-Fehler";

CM_ SG_ 289 MO_Entkopplung_Sollschlupf "MSG fordert von GSG an, das Anfahrelement (Fahr-/Wandlerkupplung) zu entkoppeln; das GSG soll die gesendete Drehzahl als Schlupf einstellen und ggf. die Regler-Parameter umschalten, damit Rucke aus dem Antrieb nicht im Fahrzeug spürbar werden; nutzbar z.B";
CM_ SG_ 289 MO_Fahrpedalgradient "Das Motorsteuergerät besitzt 2 analoge Fahrpedalsignale. Das Signal des ersten Kanals wird alle 4ms abgetastet. Um Bitschwankungen des A/D-Wandler herauszufiltern wird das Signal entjittert. Anschließend wird der Gradient berechnet. Entsprechend der Zyklu";
CM_ SG_ 289 MO_Fahrpedalrohwert_01 "AUDI D4: Zykluszeit: 10ms (siehe Zykluszeit schnell/Cycletime Fast)

Stellung des Fahrpedales (Rohwert, ohne Überlagerung durch GRA-Eingriffe etc.)

Die Funktionen zur Berechung des Fahrpedalrohwerts laufen im 10ms Raster. Der Fahrpedalwert berechnet ";
CM_ SG_ 289 MO_Moment_im_Leerlauf "Fahrerwunschmoment ist minimal: keine Momentenanforderung durch Fahrpedal, ACC oder GRA+; (Das Signal ist unabhängig von Momentenerhöhungen durch Leerlaufregler oder MSR).

AUDI D4: Zykluszeit: 10ms (siehe Zykluszeit schnell/Cycletime Fast)

Achtung:";
CM_ SG_ 289 MO_QBit_Fahrpedalwerte_01 "AUDI D4: Zykluszeit: 10ms (siehe Zykluszeit schnell/Cycletime Fast)

QBit für beide Fahrpedalwerte des Motors (Fahrpedalrohsignal für ESP, EPB, ACC; Fahrpedalwert für Getriebe)

Achtung:
Reduktion der Zykluszeit Motor_03 auf 10ms geplant.
Projektabh";
CM_ SG_ 289 MO_rel_Saugrohrdruck "Der Wert gibt an, um wieviel mbar der Saugrohrdruck unterhalb des Umgebungsdrucks liegt. Überdruck im Saugrohr wird nicht ausgegeben.
0: Saugrohrdruck=Umgebungsdruck";
CM_ SG_ 289 MO_rel_Saugrohrdruck_gem_err "0: mind. eine Modellrechnung wird zur Berechnung des relativen Saugdrucks herangezogen
1: Relativer Saugrohrdruck wird ausschließlich über Messgrößen bestimmt";
CM_ SG_ 289 MO_Schubabschaltung "ESP plausibilisiert Unterdrucksensor nur bei aktiver Schubabschaltung

MLBevo:
Signal wird nur in MLBevo Projekten mit PDKII Getriebe bedient. In allen anderen MLBevo Projekten wird das Signal mit '0' bedient
PDKII berücksichtigt Verzugszeiten, die in";
CM_ SG_ 289 MO_Sig_Fahrpedalgradient "Kennzeichnet das Vorzeichen des Signal 'Fahrpedalgradient'. Die Ausgabe erfolgt nur parallel statisch mit gesendetem Signal: 'Steuerungsbit Fahrpedalgradient' ";
CM_ SG_ 289 MO_Solldrehz_Leerlauf "Leerlaufsolldrehzahl, die im Motor eingestellt ist (Bei Parallelhybrid im E-Fahr-Betrieb Leerlaufsolldrehzahl der E-Maschine). Der Motor paßt aufgrund der Anforderung von anderen Steuergeräten seine Leerlaufsolldrehzahl an, bspw. Kat-Heizen, Anforderung v";
CM_ SG_ 289 MO_StartStopp_StoppVorbereitung "Zeigt allen aktiven Start-/Stoppteilnehmern einen möglichen Motorstopp im Anhaltevorgang an (Empfänger notwendige Vorbereitungen treffen)
Es liegen keine Vetos vor.";
CM_ SG_ 289 MO_temporaere_Fahrerabwesenheit "Das Signal dient zur Signalisierung einer temporären Abwesenheit des Fahrers. In dieser Zeit ist es ihm möglich, sich durch gewisse ¿ im Verlassenskonzept definierte ¿ Fahreraktionen im aktuellen Fahrzyklus zurückzumelden.
Das Signal wird gesetzt, sobald";
CM_ SG_ 289 Motor_20_BZ "Botschaft asynchron geroutet. Zählerwert kann springen.";
CM_ SG_ 289 Motor_20_CRC "Für MLB:
'Berechnung siehe Lastenheft 'Kommunikationsabsicherung für FlexRay und CAN''

Ab MQB und MLBevo:
'Berechnung siehe Lastenheft 'End-to-End Kommunikationsabsicherung'

Endwerte siehe Begleitdokument 'S-PDU Kennungsfolgen'";
CM_ SG_ 289 TSK_a_Soll_gradientenbegrenzt "TSK Sollbeschleunigung für Fahrerassistenzsysteme mit aktiver Längsführung (GRA, ACC, IPA...). Der Wert stellt den ruckbegrenzten Sollwert der TSK-Regelung dar und ist Basis der TSK-Antriebs- und Bremsmomentenvorsteuerung.";

CM_ SG_ 1423 FSA_Fehlerpfade_Initialisieren "Aktivierung der Fehlerpfad-Initialisierung  beim FSP Löschen ueber Mode04";
CM_ SG_ 1423 MO_FSA_Sensorheizung "Aktivierung Sensorheizung FSA";
CM_ SG_ 1423 MO_Getriebe_Oelalterung "Prozentualer Alterungswert Getriebeöl";
CM_ SG_ 1423 MO_ITM_Status "Statusinformationen an TME-Steuergerät bzgl. Thermomanagement";
CM_ SG_ 1423 MO_KJS_LLK_Pos_Summe "Aerodynamisch wirksamer Gesamtöffnungswinkel aller Kühlerlüfter- und LLK-Jalousiesteller.

Pos_Frontendverschl_ungenau = 15 zeigt eine Fehlfunktion bzw. unbekannte Position einer oder mehrere Jalousiesteller an.";
CM_ SG_ 1423 MO_Kuehlmittel_Temp_Rohwert "Rohwert Kuehlmitteltemperatur
Das Signal wird derzeit von Diesel-Projekten nicht bedient.";
CM_ SG_ 1423 MO_Oel_Temp_Radsatz "Öltemperatur in PDK Radsatz ";
CM_ SG_ 1423 MO_Tankdruck "Tank Über-/Unterdruck wird für Ansteuerintensität der Treibstoffpumpe der Standheizung benötigt.";

CM_ SG_ 340 MO_Drehzahl_VM "Motordrehzahl des Verbrennungsmotors

für OBD freeze frame

Hinweis: 
Ehemaliger Fehlerwert 0xFFFF wird senderseitig nicht unterstützt. 
Diesen Wert aus Kompatibilitätsgründen nicht neu belegen!";
CM_ SG_ 340 MO_Fehlerstatus_Antrieb_FDR "Fehlerstatus Antrieb - FDR";
CM_ SG_ 340 MO_IstMoment_VKM "Ist-Moment des Verbrennungsmotors

einheitenloser Wert! MO_Faktor_Momente_02 in Motor_Code_01 berücksichtigen!";
CM_ SG_ 340 MO_Mom_Begr_Schalt "Einheitenloser Wert! Faktor in MO_Faktor_Momente (CAN V6.x) bzw. MO_Faktor_Momente_02 (CAN V7.x/8.x) in Motor_Code_01 beachten!

Bei aktueller Drehzahl kurzfristig (ca. 100..200 ms) für momentenerhöhende Getriebeeingriffe max. zur Verfügung stehendes Ge";
CM_ SG_ 340 MO_Mom_Begr_Schalt_Min "Bei aktueller Drehzahl im nächsten Task (im VKM Umsetzung zur nächsten möglichen Verbrennung) minmal stellbares Moment (Summe aus Verbrennungsmotor und E-Motor) aufgrund Momenten-Reduzierungs-Anforderung durch reduzierenden Getriebeeingriff.
Berücksichti";
CM_ SG_ 340 MO_Primaerachse_Anforderung "Das Signal dient der Steuerung der Primärachse. 

Anforderung zum Öffnen/Schließen der Getriebekupplungen und damit An-/Abkuppeln der Primärachse. 
Wird in MHEV-Projekten keine explizite Anforderung gesendet (Wert 0), ist die Freilaufsteuerung aus 'MO_";
CM_ SG_ 340 Motor_28_BZ "Botschaft asynchron geroutet. Zählerwert kann springen.";
CM_ SG_ 340 Motor_28_CRC "Für MLB:
'Berechnung siehe Lastenheft 'Kommunikationsabsicherung für FlexRay und CAN''

Ab MQB und MLBevo:
'Berechnung siehe Lastenheft 'End-to-End Kommunikationsabsicherung''

Endwerte siehe Begleitdokument 'S-PDU Kennungsfolgen'";

CM_ SG_ 1601 MO_Ansaugsystem "Art des Ansaugsystems des Verbrennungsmotors";
CM_ SG_ 1601 MO_Anzahl_Zyl "Zylinderzahl des Verbrennungsmotors";
CM_ SG_ 1601 MO_Anzeige_StSt_gueltig "Zeigt die Gültigkeit der neuen StSt-Anzeigesignale an, MO_Anzeige_StSt_Text und  MO_Anzeige_Symbol. Mo_Text_Motorstart 1..5 sind zu ignorieren.";
CM_ SG_ 1601 MO_Code "Motorcodierinformation Version 13 (Details siehe Anhang)";
CM_ SG_ 1601 MO_DPF_verbaut "Verbauinformation Diesel-Partikel-Filter
";
CM_ SG_ 1601 MO_Faktor_Momente_02 "Dieses Signal schaltet den Wertebereich aller Momente vom Motor, Getriebe, TSK, Bremse ... um! Die Momente besitzen somit einen variablen Wertebereich, weil sich durch den Faktor die Momente sowohl in Auflösung als auch Maximalwerten ändert.

0x0 nicht ";
CM_ SG_ 1601 MO_Getriebe_Code "Getriebecodierung des Motors";
CM_ SG_ 1601 MO_Hubraum "Hubraum des Verbrennungsmotors";
CM_ SG_ 1601 MO_Hybridfahrzeug "Anhand dieses Signals plausibilisiert die Lenkhilfe das Bit Fahrbereitschaft.

Im Projekt Cayenne PHEV (und ggf. auch VW526 PHEV) ist aus Gründen der Abwärtskompatibilität der Wert '2' zu senden.";
CM_ SG_ 1601 MO_Kraftstoffart "Primärkraftstoff zum Antrieb des Fahrzeugs";
CM_ SG_ 1601 MO_Leistung "Nennleistung des Verbrennungsmotors";
CM_ SG_ 1601 MO_OBD_Typ "Abgastyp OBD";
CM_ SG_ 1601 MO_StartStopp_Codiert "Funktion StartStopp im aktuellen Klemmenzyklus verbaut";
CM_ SG_ 1601 Motor_Code_01_CRC "Für MLB:
'Berechnung siehe Lastenheft 'Kommunikationsabsicherung für FlexRay und CAN''

Ab MQB und MLBevo:
'Berechnung siehe Lastenheft 'End-to-End Kommunikationsabsicherung''

Endwerte siehe Begleitdokument 'S-PDU Kennungsfolgen'";
CM_ SG_ 1601 TSK_Codierung "Information über den plausibilisierten Codierungszustand des Triebstrangskoordinators auf ACC oder GRA.";

CM_ SG_ 305 Ladezustand_02 "Aktueller relativer Ladezustand der HV-Batterie
";
CM_ SG_ 305 MO_ePerformance "Zeigt die elektrische Leistungreserve bei BEV und PHEV Projekten an.
Bei Init und Fehler soll keine Anzeige erfolgen. ";
CM_ SG_ 305 MO_ePowermeter "Anzeige ePowermeter (Fahrreserve elektrisch bis Start Verbrennungsmotor (Verbrenner startet bei 100%))";
CM_ SG_ 305 MO_Powermeter "Anzeigewerte im Kombi
0       = Unteres Ende Bremsen/grau;
340   = Unteres Ende CHARGE;
1020 = READY;
1870 = Oberes Ende EFFICIENCY;
3400 = 100%;
4080 = MAX;";
CM_ SG_ 305 MO_Powermeter_Elm "Die Prozentwerte ergeben sich aus dem momentanen Moment der E-Maschine bezogen auf das im aktuellen Arbeitspunkt maximal mögliche Moment der E-Maschine (generatorisch = negativ / motorisch = positiv )";
CM_ SG_ 305 MO_Powermeter_Elm_02 "relatives Moment / relative Leistung der elektrischen Maschine";
CM_ SG_ 305 MO_Zust_Antrieb "Signalisiert die Zuordnung der Antriebsverbräuche zu den Antriebsmaschinen für die Restreichweitenberechnung, nicht gleichbedeutend mit Motorlauf EM oder VM";
CM_ SG_ 305 MO_Zust_Betriebsstrategie "Signalisiert den aktuellen Zustand der Betriebsstrategie";

CM_ SG_ 394 MO_Ablaufstatus "aktueller Status bezüglich der Ausführung des Sollzustand

detaillierte Beschreibung der einzelnen Übergänge ist in der aktuellsten Version des Lastenhefts 'Funktionslastenheft Betriebsartenkoordination bei elektrifizierten Fahrzeugen_Vxx' zu entnehmen";
CM_ SG_ 394 MO_Ablaufstrg_Betriebszustand "Istzustand Betriebsbereitschaft

1 = Betriebsbereitschaft bedeutet: Alle Komponenten sind betriebsbereit. Fahrzeug kann kein Vortriebsmoment erzeugen.

2 = Fahrbetrieb bedeutet: Fahrzeug kann Vortriebsmoment erzeugen.";
CM_ SG_ 394 MO_Ablaufstrg_Kraftschluss2_Ist "Istzustand des Kraftschlusses der Sekundärachse in der Hybridablaufsteuerung (z.B. el. Hinterachse im B9 eQuattro).
Dieses Signal entspricht nicht einem physikalischen Zustand, sondern den Istzustand der Ablaufsteuerung.

Das Signal darf nur ausgwertet";
CM_ SG_ 394 MO_Ablaufstrg_Kraftschluss2_Ziel "Zielstatus des Kraftschlusses der Sekundärachse in der Hybridablaufsteuerung (z.B. el. Hinterachse im B9 eQuattro).
Mit dem Bit soll das Getriebe Kraftschluss herstellen oder den Kraftschluss unterbrechen.

Das Signal darf nur ausgwertet werden, wenn '";
CM_ SG_ 394 MO_Ablaufstrg_Kraftschluss_Ist "Istzustand des Kraftschlusses in der Hybridablaufsteuerung.
Dieses Signal entspricht nicht einem physikalischen Zustand, sondern den Istzustand der Ablaufsteuerung.

Das Signal darf nur ausgwertet werden, wenn 'MO_Ablaufstrg_Betriebszustand' eine Betri";
CM_ SG_ 394 MO_Ablaufstrg_Kraftschluss_Ziel "Zielstatus des Kraftschlusses in der Hybridablaufsteuerung.
Mit dem Bit soll das Getriebe Kraftschluss herstellen oder den Kraftschluss unterbrechen.

Das Signal darf nur ausgwertet werden, wenn 'MO_Ablaufstrg_Betriebszustand' eine Betriebsbereitschaft";
CM_ SG_ 394 MO_Ablaufstrg_Zustand_K0_Ist "Iststatus der K0 Kupplung in der Hybridablaufsteuerung.
Dieses Signal entspricht nicht einem physikalischen Zustand, sondern den Istzustand der Ablaufsteuerung.

Das Signal darf nur ausgwertet werden, wenn 'MO_Ablaufstrg_Betriebszustand' eine Betriebsb";
CM_ SG_ 394 MO_Ablaufstrg_Zustand_K0_Ziel "Zielstatus der K0 Kupplung in der Hybridablaufsteuerung
K0 Steuerung im Motorsteuergerät:
- Infobit an das Getriebe, dass K0 jetzt geschlossen wird
K0 Steuerung durch anderes Steuergerät:
- Bit um dem anderen SG mitzuteilen, dass dieses die K0 schlies";
CM_ SG_ 394 MO_Ablaufstrg_Zustand_VKM_Ist "Istzustand VKM
Dieses Signal entspricht nicht einem physikalischen Zustand, sondern den Istzustand der Ablaufsteuerung.

Das Signal darf nur ausgewertet werden, wenn 'MO_Ablaufstrg_Betriebszustand' eine Betriebsbereitschaft signalisiert.";
CM_ SG_ 394 MO_Ablaufstrg_Zustand_VKM_Ziel "Zielzustand VKM
Dieses Signal entspricht nicht einem physikalischen Zustand, sondern den Zielzustand der Ablaufsteuerung.

Das Signal darf nur ausgewertet werden, wenn 'MO_Ablaufstrg_Betriebszustand' eine Betriebsbereitschaft signalisiert.";
CM_ SG_ 394 MO_Abstellposition_02 "Winkelabstand (in °KW) des sog. Zielzylinders von seinem ZOT (bspw. nötig um Startmoment bei Schleppstart zu berechnen)

255 = Abstellposition kann nicht genau bestimmt werden (bspw. Rückdrehen des Motors)";
CM_ SG_ 394 MO_Auth_Aufforderung_WFS "WFS-Anforderung für Hybridumfänge";
CM_ SG_ 394 MO_HYB_Adaption_aktiv "Motor fordert Sondermaßnahmen vom Getriebe PDK2 (gültig nur für Hybridprojekte)
Das Signal wird im PDKII dazu verwendet, die Fahrkupplungen bei einem Momentenadaptionswunsch der K0-Trennkupplung nicht zu befüllen";
CM_ SG_ 394 MO_HYB_E_Faktor "Signed Nibble, verwendet vom GSG zur Interpolation zwischen VMKennfeld und dem Rekuperations-Grenzkennfeld (negative Werte des E-Faktors) bzw. dem Boost-Grenzkennfeld (positive Werte des E-Faktors).
0000 = VM-Kennfeld (keine Interpolation)
0001..0111 = ";
CM_ SG_ 394 MO_HYB_EMode_Info "Hybrid-Mode der Motorsteuerung zur Beeinflussung der Schaltkennfelder im Getriebe. Nicht-Hybridfahrzeuge senden den Initwert.";
CM_ SG_ 394 MO_HYB_LowSpeedModus "MSG legt fest:
0 = klassisches Ausrollen/Anfahren mit N_mot >= N_Leerlauf_VM
1 = elektr. Ausrollen/Anfahren mit geschl. Triebstrang mit N_mot < N_Leerlauf_VM";
CM_ SG_ 394 MO_HYB_Stoppmodus "Hybridsteuerung zeigt an, auf welche Weise gestoppt werden soll.";
CM_ SG_ 394 MO_Mom_Freiheit_Sekundaerachse "Signalisiert die Momentenfreiheit der Sekundärachse und ist damit Voraussetzung für das Abkoppeln.";
CM_ SG_ 394 MO_Nachlaufzeit_Kuehlerluefter "Nachlaufzeit Kühlerlüfter MSG für Verwendung im TME SG";
CM_ SG_ 394 MO_Start_Art "Beschreibt Art des Starts näher 

Schlupfstart kann entweder Momentenvorhalt oder Impulsstart sein oder eine Kombination aus beidem.";
CM_ SG_ 394 MO_Start_Dynamik "Zeigt die Start-Variante bzw. Start-Dynamik eines VKM-Starts an";
CM_ SG_ 394 MO_Tankklappensteuerung "Ansteuerungsanforderung der Tankklappe";

CM_ SG_ 234 Motor_TS_03_BZ "Fortlaufender Botschaftszähler";
CM_ SG_ 234 Motor_TS_03_CRC "Für MLB:
'Berechnung siehe Lastenheft 'Kommunikationsabsicherung für FlexRay und CAN''

Ab MQB und MLBevo:
'Berechnung siehe Lastenheft 'End-to-End Kommunikationsabsicherung''

Endwerte siehe Begleitdokument 'S-PDU Kennungsfolgen'";
CM_ SG_ 234 TS_Allrad_Anteil_sek "Vom Antrieb gewünschter prozentualer Anteil der sekundären Antriebsachse am Gesamtmoment";
CM_ SG_ 234 TS_MomRad_Ist "Gesamt-Istmoment der Antriebsmaschinen, umgerechnet auf Radebene, unter Berücksichtigung der Massenträgheiten der Antriebsmaschinen und des Getriebes, unter Berücksichtigung der Verluste der Antriebsmaschinen, der Nebenaggregate und des Getriebes (d.h. ke";
CM_ SG_ 234 TS_MomRad_Ist_sek "Gesamt-Istmoment der Antriebsmaschinen, umgerechnet auf Radebene, unter Berücksichtigung der Massenträgheiten der Antriebsmaschinen und des Getriebes, unter Berücksichtigung der Verluste der Antriebsmaschinen, der Nebenaggregate und des Getriebes.
Zeigt ";
CM_ SG_ 234 TS_MomRad_verfuegb_maxReku_Summe "Im aktuellen Betriebszustand kurzfristig (ca. 100..200 ms) verfügbares max. negatives Summenmoment; definiert auf Bezugsebene Rad.
Faktor in TS_Faktor_Radmomente beachten!";
CM_ SG_ 234 TS_Status_MomRad_Ist "Qualitätsstatus zu TS_MomRad_Ist und TS_MomRad_Ist_Sek
Qualifiziert bei antriebstechnisch getrennten Achsen sowohl das Moment der primären Achse als auch das Moment der sekundären Achse, und bei mechanischem Allradantrieb das Gesamtmoment für beide Achse";

CM_ SG_ 849 ASW_Warnung_HL "Warnung auf der linke Fahrzeugseite";
CM_ SG_ 849 MRR_HL_ASW_Modus "gibt die Verfügbarkeit der ASW Funktion an";
CM_ SG_ 849 MRR_HL_ASW_Status "Funktionstatus";
CM_ SG_ 849 MRR_HL_ASW_System_aktiv "Synchronisierung des Funktionszustands Ausstiegswarnung (ASW) zwischen den Steuergeräten MRR HL und MRR HR";
CM_ SG_ 849 MRR_HL_Blindness_Status "Evaluierung der MRR Blindness Heck-Sensoren";
CM_ SG_ 849 MRR_HL_Kalibriermodus "Aktueller Modus der Autokalibrierung";
CM_ SG_ 849 MRR_HL_Performance_Status "Übertragung der Fehlerzustände im Slave an den Master und umgekehrt";
CM_ SG_ 849 MRR_HL_QualFaktorAutoKalib "Geschätzte Qualität des Faktors der Autokalibrierung";
CM_ SG_ 849 MRR_HL_Sensor_Fehler "Das Signal wird für die Kalibrierung benötigt.";
CM_ SG_ 849 MRR_HL_Sensor_Kl_Status "Vom Sensor erkannter Klemmenstatus";

CM_ SG_ 2463978596 MRR_HL_Info1 "Kompatibilitätcheck";

CM_ SG_ 848 MRR_HR_ASW_System_aktiv "Synchronisierung des Funktionszustands Ausstiegswarnung (ASW) zwischen den Steuergeräten MRR HL und MRR HR";
CM_ SG_ 848 MRR_HR_Blindness_Anf "Triggert die Blindness-Erkennung im Slave.";
CM_ SG_ 848 MRR_HR_Blindness_Status "Evaluierung der MRR Blindness Heck-Sensoren";
CM_ SG_ 848 MRR_HR_Info_Anf "Kompatibilitaetcheck";
CM_ SG_ 848 MRR_HR_Kalibriermodus "Aktueller Modus der Autokalibrierung";
CM_ SG_ 848 MRR_HR_LED_RelHelligkeit "Helligkeit der LEDs";
CM_ SG_ 848 MRR_HR_Performance_Status "Übertragung der Fehlerzustände im Slave an den Master und umgekehrt";
CM_ SG_ 848 MRR_HR_QualFaktorAutoKalib "Geschätzte Qualität des Faktors der Autokalibrierung";

CM_ SG_ 1696 NV_Akt_Status_MMI "Zustand des Nightvison Systems im MMI: Warnalgo & NV-Reiter Ein/Aus

";
CM_ SG_ 1696 NV_aktiv "Nightvision aktiviert (liefert Bild)";
CM_ SG_ 1696 NV_Akustik_deaktiviert_Icon "Ansteuerungssignal für das  Akustik-deaktiviert-Icon";
CM_ SG_ 1696 NV_Anf_Prefill "Anforderung an ESP, dass die Prefill-Funktion aktiviert werden soll.";
CM_ SG_ 1696 NV_AnforderungBildaufschaltung "Automatische Bildaufschaltung im Warnfall";
CM_ SG_ 1696 NV_FAS_Fkt_Status "Signal für FAS Profile-Master";
CM_ SG_ 1696 NV_FGM_deaktiviert_Icon "Ansteuerungssignal für das  Fussgängermarkierung-deaktiviert-Icon";
CM_ SG_ 1696 NV_Gong "Das Signal löst einen Gong des NightVision-Systems im Kombidisplay aus";
CM_ SG_ 1696 NV_HBA_Parameter "Anforderung an ESP, welcher HBA-Parametersatz verwendet werden soll. Die Festlegung der Empfindlichkeitsschwellen der verschiedenen Parametersätze erfolgt mit der Applikation des Gesamtsystems ESP/ACC bzw. des HBA.
Nur Audi B8: Umsetzung der Anforderung ";
CM_ SG_ 1696 NV_Hinweise "Das Signal dient dazu Hinweistexte in das NightVision Bild im Kombiinstrument einzublenden.Die Anzeigedauer der Hinweistexte ist Signalgesteuert. D.h., sie werden angezeigt bis das CAN-Signal s_NV_Texte seinen Wert ändert.";
CM_ SG_ 1696 NV_LED_Leiste "Ansteuerung_LED_Warnleiste";
CM_ SG_ 1696 NV_Markierungslicht_links "Das Signal steuert die Aktivierung des Markierungslicht links bei Fußgängerwarnung";
CM_ SG_ 1696 NV_Markierungslicht_rechts "Das Signal steuert die Aktivierung des Markierungslicht rechts bei Fußgängerwarnung";
CM_ SG_ 1696 NV_Piktogramm_aktiv "Signal sagt, dass das Piktogramm im NightVision-Reiter geändert werden soll";
CM_ SG_ 1696 NV_PreSense_Modus_System "Signal zur Realisierung der BAP-Kommunikation für PreSense";
CM_ SG_ 1696 NV_PreSense_Modus_Warnung "Signal zur Realisierung der BAP-Kommunikation für PreSense";
CM_ SG_ 1696 NV_PreSense_Status "Signal zur Realisierung der BAP-Kommunikation für PreSense";
CM_ SG_ 1696 NV_Symbol "Wenn das NV-System einen Fußgänger findet, fordert es mit dem Signal das HUD auf, ein Symbol zu zeigen";
CM_ SG_ 1696 NV_Symbol_Tierwarnung "Signal zur Anforderung einer Symbolanzeige für Tierwarnung.";
CM_ SG_ 1696 NV_Texte "Angeforderte Textmeldung";

CM_ SG_ 2600468496 NM_Gateway_CAB "CAB = Clusteraktivbits";
CM_ SG_ 2600468496 NM_Gateway_Car_Wakeup "Car Wakeup (Subbusmaster wertet aus)

MQB: 
-Diagnose- oder Komponentenschutzmaster-Funktion weckt den schlafenden Subbus (z.B. MOST)";
CM_ SG_ 2600468496 NM_Gateway_CBV_AWB "Das Signal ist zu setzen, wenn das SG aktiv den Bus geweckt hat";
CM_ SG_ 2600468496 NM_Gateway_CBV_CRI "Das Signal ist dauerhaft gesetzt, wenn das NM-Layout dem neuen NM-Layout für Teilnetzbetrieb entspricht";
CM_ SG_ 2600468496 NM_Gateway_NM_aktiv_Buskopplung "Nachlauf aufgrund Kopplung zweier Busse. z.B. K-CAN und K2-CAN";
CM_ SG_ 2600468496 NM_Gateway_NM_aktiv_Connect "Nachlauf aufgrund Connect";
CM_ SG_ 2600468496 NM_Gateway_NM_aktiv_CWU "Nachlauf aufgrund CWU Anforderung";
CM_ SG_ 2600468496 NM_Gateway_NM_aktiv_Diagnose "Diagnose befindet sich nach VW80124 in einer NonDefaultDiagnostic-Session, z.B. ExtendedDiagnostic-Session";
CM_ SG_ 2600468496 NM_Gateway_NM_aktiv_EM "Nachlauf aufgrund Energiemanagement";
CM_ SG_ 2600468496 NM_Gateway_NM_aktiv_FC "Nachlauf aufgrund Funktionscluster Anforderung";
CM_ SG_ 2600468496 NM_Gateway_NM_aktiv_KL15 "Steuergerät hat KL15-EIN erkannt";
CM_ SG_ 2600468496 NM_Gateway_NM_aktiv_OBDC "Nachlauf aufgrund OBDC";
CM_ SG_ 2600468496 NM_Gateway_NM_aktiv_Tmin "Mindestaktivzeit ist noch nicht abgelaufen (bei jedem Weckereignis wird die Mindestaktivzeit neu gestartet)";
CM_ SG_ 2600468496 NM_Gateway_NM_State "1 = Zustand Repeat Message (<-- Bus-Sleep Mode)
2 = Zustand Repeat Message (<-- Prepare Bus-Sleep Mode)
4 = Zustand Normal Operation (<-- Repeat Message)
8 = Zustand Normal Operation (<-- Ready Sleep)
16 = Zustand Repeat Message (<-- Ready Sleep)
32 ";
CM_ SG_ 2600468496 NM_Gateway_SNI "Source Node-Identifier (SNI) identifiziert den Sender der NM-Botschaft (Knotenadresse) eindeutig im Fahrzeug";
CM_ SG_ 2600468496 NM_Gateway_UDS_CC "Funktionseinschränkung aufgrund aktivem UDS-Communication Control; siehe VW80124";

CM_ SG_ 2600468519 NM_Nightvision_CAB "CAB = Clusteraktivbits";
CM_ SG_ 2600468519 NM_Nightvision_Car_Wakeup "Car Wakeup (Gateway wertet aus)";
CM_ SG_ 2600468519 NM_Nightvision_CBV_AWB "Das Signal ist zu setzen, wenn das SG aktiv den Bus geweckt hat";
CM_ SG_ 2600468519 NM_Nightvision_CBV_CRI "Das Signal ist dauerhaft gesetzt, wenn das NM-Layout dem neuen NM-Layout für Teilnetzbetrieb entspricht";
CM_ SG_ 2600468519 NM_Nightvision_NM_aktiv_defekt "NV hat Fehler erkannt der zu einer Kombimeldung führt";
CM_ SG_ 2600468519 NM_Nightvision_NM_aktiv_Diagnose "Diagnose befindet sich nach VW80124 in einer NonDefaultDiagnostic-Session, z.B. ExtendedDiagnostic-Session";
CM_ SG_ 2600468519 NM_Nightvision_NM_aktiv_KL15 "Steuergerät hat KL15-EIN erkannt";
CM_ SG_ 2600468519 NM_Nightvision_NM_aktiv_ON "Nightvision ist aktiviert";
CM_ SG_ 2600468519 NM_Nightvision_NM_aktiv_Tmin "Mindestaktivzeit ist noch nicht abgelaufen (bei jedem Weckereignis wird die Mindestaktivzeit neu gestartet)";
CM_ SG_ 2600468519 NM_Nightvision_NM_State "1 = Zustand Repeat Message (<-- Bus-Sleep Mode)
2 = Zustand Repeat Message (<-- Prepare Bus-Sleep Mode)
4 = Zustand Normal Operation (<-- Repeat Message)
8 = Zustand Normal Operation (<-- Ready Sleep)
16 = Zustand Repeat Message (<-- Ready Sleep)
32 ";
CM_ SG_ 2600468519 NM_Nightvision_SNI "Source Node-Identifier (SNI) identifiziert den Sender der NM-Botschaft (Knotenadresse) eindeutig im Fahrzeug";
CM_ SG_ 2600468519 NM_Nightvision_UDS_CC "Funktionseinschränkung aufgrund aktivem UDS-Communication Control; siehe VW80124";

CM_ SG_ 2600468491 NM_RDK_CAB "CAB = Clusteraktivbits";
CM_ SG_ 2600468491 NM_RDK_Car_Wakeup "Car Wakeup (Gateway wertet aus)";
CM_ SG_ 2600468491 NM_RDK_CBV_AWB "Das Signal ist zu setzen, wenn das SG aktiv den Bus geweckt hat";
CM_ SG_ 2600468491 NM_RDK_CBV_CRI "Das Signal ist dauerhaft gesetzt, wenn das NM-Layout dem neuen NM-Layout für Teilnetzbetrieb entspricht";
CM_ SG_ 2600468491 NM_RDK_NM_aktiv_Diagnose "Diagnose befindet sich nach VW80124 in einer NonDefaultDiagnostic-Session, z.B. ExtendedDiagnostic-Session";
CM_ SG_ 2600468491 NM_RDK_NM_aktiv_KL15 "Steuergerät hat KL15-EIN erkannt";
CM_ SG_ 2600468491 NM_RDK_NM_aktiv_Tmin "Mindestaktivzeit ist noch nicht abgelaufen (bei jedem Weckereignis wird die Mindestaktivzeit neu gestartet)";
CM_ SG_ 2600468491 NM_RDK_NM_State "1 = Zustand Repeat Message (<-- Bus-Sleep Mode)
2 = Zustand Repeat Message (<-- Prepare Bus-Sleep Mode)
4 = Zustand Normal Operation (<-- Repeat Message)
8 = Zustand Normal Operation (<-- Ready Sleep)";
CM_ SG_ 2600468491 NM_RDK_SNI "Source Node-Identifier (SNI) identifiziert den Sender der NM-Botschaft (Knotenadresse) eindeutig im Fahrzeug";
CM_ SG_ 2600468491 NM_RDK_UDS_CC "Funktionseinschränkung aufgrund aktivem UDS-Communication Control; siehe VW80124";

CM_ SG_ 2600468585 NM_RearView_CAB "CAB = Clusteraktivbits";
CM_ SG_ 2600468585 NM_Rearview_Car_Wakeup "Car Wakeup (Gateway wertet aus)
";
CM_ SG_ 2600468585 NM_RearView_CBV_AWB "Das Signal ist zu setzen, wenn das SG aktiv den Bus geweckt hat";
CM_ SG_ 2600468585 NM_RearView_CBV_CRI "Das Signal ist dauerhaft gesetzt, wenn das NM-Layout dem neuen NM-Layout für Teilnetzbetrieb entspricht";
CM_ SG_ 2600468585 NM_Rearview_NM_aktiv_Diagnose "Diagnose befindet sich nach VW80124 in einer NonDefaultDiagnostic-Session, z.B. ExtendedDiagnostic-Session";
CM_ SG_ 2600468585 NM_Rearview_NM_aktiv_KL15 "Steuergerät hat KL15-EIN erkannt";
CM_ SG_ 2600468585 NM_Rearview_NM_aktiv_Tmin "Mindestaktivzeit ist noch nicht abgelaufen (bei jedem Weckereignis wird die Mindestaktivzeit neu gestartet)";
CM_ SG_ 2600468585 NM_Rearview_NM_State "1 = Zustand Repeat Message (<-- Bus-Sleep Mode)
2 = Zustand Repeat Message (<-- Prepare Bus-Sleep Mode)
4 = Zustand Normal Operation (<-- Repeat Message)
8 = Zustand Normal Operation (<-- Ready Sleep)";
CM_ SG_ 2600468585 NM_Rearview_SNI "Source Node-Identifier (SNI) identifiziert den Sender der NM-Botschaft (Knotenadresse) eindeutig im Fahrzeug";
CM_ SG_ 2600468585 NM_Rearview_UDS_CC "Funktionseinschränkung aufgrund aktivem UDS-Communication Control; siehe VW80124";

CM_ SG_ 2600468522 NM_SCR_CAB "CAB = Clusteraktivbits";
CM_ SG_ 2600468522 NM_SCR_Car_Wakeup "Car Wakeup (Gateway wertet aus)

MLBevo: Fehler bei Evakuierung des Systems";
CM_ SG_ 2600468522 NM_SCR_CBV_AWB "Das Signal ist zu setzen, wenn das SG aktiv den Bus geweckt hat";
CM_ SG_ 2600468522 NM_SCR_CBV_CRI "Das Signal ist dauerhaft gesetzt, wenn das NM-Layout dem neuen NM-Layout für Teilnetzbetrieb entspricht";
CM_ SG_ 2600468522 NM_SCR_NM_aktiv_Diagnose "Diagnose befindet sich nach VW80124 in einer NonDefaultDiagnostic-Session, z.B. ExtendedDiagnostic-Session";
CM_ SG_ 2600468522 NM_SCR_NM_aktiv_KL15 "Steuergerät hat KL15-EIN erkannt";
CM_ SG_ 2600468522 NM_SCR_NM_aktiv_Tmin "Mindestaktivzeit ist noch nicht abgelaufen (bei jedem Weckereignis wird die Mindestaktivzeit neu gestartet)";
CM_ SG_ 2600468522 NM_SCR_NM_State "1 = Zustand Repeat Message (<-- Bus-Sleep Mode)
2 = Zustand Repeat Message (<-- Prepare Bus-Sleep Mode)
4 = Zustand Normal Operation (<-- Repeat Message)
8 = Zustand Normal Operation (<-- Ready Sleep)
16 = Zustand Repeat Message (<-- Ready Sleep)
32 ";
CM_ SG_ 2600468522 NM_SCR_SNI "Source Node-Identifier (SNI) identifiziert den Sender der NM-Botschaft (Knotenadresse) eindeutig im Fahrzeug";
CM_ SG_ 2600468522 NM_SCR_UDS_CC "Funktionseinschränkung aufgrund aktivem UDS-Communication Control; siehe VW80124";

CM_ SG_ 2600468586 NM_STH_CAB "CAB = Clusteraktivbits";
CM_ SG_ 2600468586 NM_STH_Car_Wakeup "Car Wakeup (Gateway wertet aus)

MQB: 
-Standheizung wurde per Funk ein oder ausgeschaltet
-Schwalltopf muß nachgefüllt werden
-Gebläse muß ein- oder ausgeschaltet werden
-neue Programmierung der Funkfernbedienung empfangen
-Standheizung abschalten";
CM_ SG_ 2600468586 NM_STH_CBV_AWB "Das Signal ist zu setzen, wenn das SG aktiv den Bus geweckt hat";
CM_ SG_ 2600468586 NM_STH_CBV_CRI "Das Signal ist dauerhaft gesetzt, wenn das NM-Layout dem neuen NM-Layout für Teilnetzbetrieb entspricht";
CM_ SG_ 2600468586 NM_STH_NM_aktiv_Diagnose "Diagnose befindet sich nach VW80124 in einer NonDefaultDiagnostic-Session, z.B. ExtendedDiagnostic-Session";
CM_ SG_ 2600468586 NM_STH_NM_aktiv_EIN_AUS_Funk "Funkbefehl STH einschalten/ausschalten aktiv";
CM_ SG_ 2600468586 NM_STH_NM_aktiv_EKP_Anf "EKP-Anforderung (Schwalltopf füllen) setzen/zurücknehmen";
CM_ SG_ 2600468586 NM_STH_NM_aktiv_KL15 "Steuergerät hat KL15-EIN erkannt";
CM_ SG_ 2600468586 NM_STH_NM_aktiv_Tmin "Mindestaktivzeit ist noch nicht abgelaufen (bei jedem Weckereignis wird die Mindestaktivzeit neu gestartet)";
CM_ SG_ 2600468586 NM_STH_NM_aktiv_WaPu_Anf "Wasserpumpe-Anforderung  setzen/zurücknehmen";
CM_ SG_ 2600468586 NM_STH_NM_State "1 = Zustand Repeat Message (<-- Bus-Sleep Mode)
2 = Zustand Repeat Message (<-- Prepare Bus-Sleep Mode)
4 = Zustand Normal Operation (<-- Repeat Message)
8 = Zustand Normal Operation (<-- Ready Sleep)";
CM_ SG_ 2600468586 NM_STH_SNI "Source Node-Identifier (SNI) identifiziert den Sender der NM-Botschaft (Knotenadresse) eindeutig im Fahrzeug";
CM_ SG_ 2600468586 NM_STH_UDS_CC "Funktionseinschränkung aufgrund aktivem UDS-Communication Control; siehe VW80124";

CM_ SG_ 2600468558 NM_SWA_CAB "CAB = Clusteraktivbits";
CM_ SG_ 2600468558 NM_SWA_Car_Wakeup "Car Wakeup (Gateway wertet aus)

MQB:
ASW Kombimeldung";
CM_ SG_ 2600468558 NM_SWA_CBV_AWB "Das Signal ist zu setzen, wenn das SG aktiv den Bus geweckt hat";
CM_ SG_ 2600468558 NM_SWA_CBV_CRI "Das Signal ist dauerhaft gesetzt, wenn das NM-Layout dem neuen NM-Layout für Teilnetzbetrieb entspricht";
CM_ SG_ 2600468558 NM_SWA_NM_aktiv_ASW_aktiv "Austiegswarner aktiviert";
CM_ SG_ 2600468558 NM_SWA_NM_aktiv_Diagnose "Diagnose befindet sich nach VW80124 in einer NonDefaultDiagnostic-Session, z.B. ExtendedDiagnostic-Session";
CM_ SG_ 2600468558 NM_SWA_NM_aktiv_KL15 "Steuergerät hat KL15-EIN erkannt";
CM_ SG_ 2600468558 NM_SWA_NM_aktiv_Tmin "Mindestaktivzeit ist noch nicht abgelaufen (bei jedem Weckereignis wird die Mindestaktivzeit neu gestartet)";
CM_ SG_ 2600468558 NM_SWA_NM_State "1 = Zustand Repeat Message (<-- Bus-Sleep Mode)
2 = Zustand Repeat Message (<-- Prepare Bus-Sleep Mode)
4 = Zustand Normal Operation (<-- Repeat Message)
8 = Zustand Normal Operation (<-- Ready Sleep)
16 = Zustand Repeat Message (<-- Ready Sleep)
32 ";
CM_ SG_ 2600468558 NM_SWA_SNI "Source Node-Identifier (SNI) identifiziert den Sender der NM-Botschaft (Knotenadresse) eindeutig im Fahrzeug";
CM_ SG_ 2600468558 NM_SWA_UDS_CC "Funktionseinschränkung aufgrund aktivem UDS-Communication Control; siehe VW80124";

CM_ SG_ 2600468618 NM_SWA_Slave_CAB "CAB = Clusteraktivbits";
CM_ SG_ 2600468618 NM_SWA_Slave_Car_Wakeup "Car Wakeup (Gateway wertet aus)";
CM_ SG_ 2600468618 NM_SWA_Slave_CBV_AWB "Das Signal ist zu setzen, wenn das SG aktiv den Bus geweckt hat";
CM_ SG_ 2600468618 NM_SWA_Slave_CBV_CRI "Das Signal ist dauerhaft gesetzt, wenn das NM-Layout dem neuen NM-Layout für Teilnetzbetrieb entspricht";
CM_ SG_ 2600468618 NM_SWA_Slave_NM_aktiv_ASW_aktiv "Austiegswarner aktiviert";
CM_ SG_ 2600468618 NM_SWA_Slave_NM_aktiv_Diagnose "Diagnose befindet sich nach VW80124 in einer NonDefaultDiagnostic-Session, z.B. ExtendedDiagnostic-Session";
CM_ SG_ 2600468618 NM_SWA_Slave_NM_aktiv_KL15 "Steuergerät hat KL15-EIN erkannt";
CM_ SG_ 2600468618 NM_SWA_Slave_NM_aktiv_Tmin "Mindestaktivzeit ist noch nicht abgelaufen (bei jedem Weckereignis wird die Mindestaktivzeit neu gestartet)";
CM_ SG_ 2600468618 NM_SWA_Slave_NM_State "1 = Zustand Repeat Message (<-- Bus-Sleep Mode)
2 = Zustand Repeat Message (<-- Prepare Bus-Sleep Mode)
4 = Zustand Normal Operation (<-- Repeat Message)
8 = Zustand Normal Operation (<-- Ready Sleep)
16 = Zustand Repeat Message (<-- Ready Sleep)
32 ";
CM_ SG_ 2600468618 NM_SWA_Slave_SNI "Source Node-Identifier (SNI) identifiziert den Sender der NM-Botschaft (Knotenadresse) eindeutig im Fahrzeug";
CM_ SG_ 2600468618 NM_SWA_Slave_UDS_CC "Funktionseinschränkung aufgrund aktivem UDS-Communication Control; siehe VW80124";

CM_ SG_ 1377 NV_MessZeitpunkt "Messzeitpunkt der Objekte und der Ergebnisse anderer Wahrnehmungsmodule
Bei Nightvision: Aufnahmezeitpunkt des zugehörigen Bildes";
CM_ SG_ 1377 NV_NichtVerfuegbar "Verfuegbarkeit Nightvision";
CM_ SG_ 1377 NV_Obj_01_InvTTCBildebStdA "Standardabweichung zu NV_Obj_01_InvTTCBildeb";
CM_ SG_ 1377 NV_Obj_01_Klasse "Klasse des Objekts";
CM_ SG_ 1377 NV_Obj_Links "Objekt für Markierungslicht in Fahrtrichtung links";
CM_ SG_ 1377 NV_Obj_Rechts "Objekt für Markierungslicht in Fahrtrichtung rechts";
CM_ SG_ 1377 NV_Obj_Warnung_Fussgaenger "Warnung auf NV_Obj_01 im Fahrzeug signalisiert";
CM_ SG_ 1377 NV_Sensor_PositionX "Position der Kamera in USK-Koordinaten
x-Koordinate des Fokussierpunktes der Kamera-Optik";
CM_ SG_ 1377 NV_Sensor_PositionY "Position der Kamera in USK-Koordinaten
y-Koordinate des Fokussierpunktes der Kamera-Optik";
CM_ SG_ 1377 NV_Sensor_PositionZ "Position der Kamera in USK-Koordinaten
z-Koordinate des Fokussierpunktes der Kamera-Optik";

CM_ SG_ 597 NV_Obj_01_Gemessen "Status Objekt gemessen/getrackt

0 = Objekt nicht gemessen, nur per 3D Modell praediziert (auch BVS)
1 = Objekt wurde im aktuellen Zyklus gemessen
2 = Nur für Video: Objekt wurde nicht gemessen, sondern per Feature-Tracking wiedergefunden (Optischer F";
CM_ SG_ 597 NV_Obj_01_ID "ID des Objektes";
CM_ SG_ 597 NV_Obj_01_InvTTCBildeb "Kehrwert der Time-to-collision mit der Bildebene";
CM_ SG_ 597 NV_Obj_01_RadialDistanz "Radiale Distanz des Zielobjektes zum messenden Sensor
Koordinatensystem: verschobenes USK mit Ursprung im messenden Sensor";
CM_ SG_ 597 NV_Obj_01_RadialDistanzStdA "Standardabweichung zu NV_Obj_01_RadialDistanz";
CM_ SG_ 597 NV_Obj_01_WnklBreite "Horizontale Breite des Objektes

Wertebereich in Grad: 
0 bis 27,8
Auflösung in Grad: 0,45

Koordinatensystem: korrigiertes Kamerakoordinatensystem (kKKS): verschobenes USK mit Ursprung in der Kamera. Beachte NV_Sensor_Position_X,Y,Z ";
CM_ SG_ 597 NV_Obj_01_WnklBreiteStdA "Standardabweichung zur horizontalen Breite des Objektes

Wertebereich in Grad: 
0 bis 5
Auflösung in Grad: 0,9

Koordinatensystem: korrigiertes Kamerakoordinatensystem (kKKS): verschobenes USK mit Ursprung in der Kamera. Beachte NV_Sensor_Position_X";
CM_ SG_ 597 NV_Obj_01_WnklHoehe "Hoehe des Objektes

Wertebereich in Grad: 
0 bis 25
Auflösung in Grad: 1,79

Koordinatensystem: korrigiertes Kamerakoordinatensystem (kKKS): verschobenes USK mit Ursprung in der Kamera. Beachte NV_Sensor_Position_X,Y,Z ";
CM_ SG_ 597 NV_Obj_01_WnklHorMitte "Horizontaler Mittelpunkt des Objektes

Wertebereich in Grad: 
-13,9 bis 13,9
Auflösung in Grad: 0,45

Koordinatensystem: korrigiertes Kamerakoordinatensystem (kKKS): verschobenes USK mit Ursprung in der Kamera. Beachte NV_Sensor_Position_X,Y,Z ";
CM_ SG_ 597 NV_Obj_01_WnklHorMitteStdA "Standardabweichung zum horizontalen Mittelpunkt des Objektes

Wertebereich in Grad: 
0 bis 5
Auflösung in Grad: 0,9

Koordinatensystem: korrigiertes Kamerakoordinatensystem (kKKS): verschobenes USK mit Ursprung in der Kamera. Beachte NV_Sensor_Posit";
CM_ SG_ 597 NV_Obj_01_WnklVertMitte "Vertikaler Mittelpunkt des Objektes

Wertebereich in Grad: 
-12,5 bis 12,5
Auflösung in Grad: 1,79

Koordinatensystem: korrigiertes Kamerakoordinatensystem (kKKS): verschobenes USK mit Ursprung in der Kamera. Beachte NV_Sensor_Position_X,Y,Z  ";

CM_ SG_ 598 NV_Obj_02_Gemessen "Status Objekt gemessen/getrackt

0 = Objekt nicht gemessen, nur per 3D Modell praediziert (auch BVS)
1 = Objekt wurde im aktuellen Zyklus gemessen
2 = Nur für Video: Objekt wurde nicht gemessen, sondern per Feature-Tracking wiedergefunden (Optischer F";
CM_ SG_ 598 NV_Obj_02_ID "ID des Objektes";
CM_ SG_ 598 NV_Obj_02_Klasse "Klasse des Objekts";
CM_ SG_ 598 NV_Obj_02_RadialDistanzRed "Radiale Distanz des Zielobjektes 

Koordinatensystem: korrigiertes Kamerakoordinatensystem (kKKS): verschobenes USK mit Ursprung in der Kamera. Beachte NV_Sensor_Position_X,Y,Z";
CM_ SG_ 598 NV_Obj_02_RadialDistanzRedStdA "Standardabweichung zur radialen Distanz des Zielobjektes 

Koordinatensystem: korrigiertes Kamerakoordinatensystem (kKKS): verschobenes USK mit Ursprung in der Kamera. Beachte NV_Sensor_Position_X,Y,Z ";
CM_ SG_ 598 NV_Obj_02_WnklBreite "Horizontale Breite des Objektes

Wertebereich in Grad: 
0 bis 27,8
Auflösung in Grad: 0,45

Koordinatensystem: korrigiertes Kamerakoordinatensystem (kKKS): verschobenes USK mit Ursprung in der Kamera. Beachte NV_Sensor_Position_X,Y,Z ";
CM_ SG_ 598 NV_Obj_02_WnklHoehe "Hoehe des Objektes

Wertebereich in Grad: 
0 bis 25
Auflösung in Grad: 1,79

Koordinatensystem: korrigiertes Kamerakoordinatensystem (kKKS): verschobenes USK mit Ursprung in der Kamera. Beachte NV_Sensor_Position_X,Y,Z ";
CM_ SG_ 598 NV_Obj_02_WnklHorMitte "Horizontaler Mittelpunkt des Objektes

Wertebereich in Grad: 
-13,9 bis 13,9
Auflösung in Grad: 0,45

Koordinatensystem: korrigiertes Kamerakoordinatensystem (kKKS): verschobenes USK mit Ursprung in der Kamera. Beachte NV_Sensor_Position_X,Y,Z ";
CM_ SG_ 598 NV_Obj_02_WnklVertMitte "Vertikaler Mittelpunkt des Objektes

Wertebereich in Grad: 
-12,5 bis 12,5
Auflösung in Grad: 1,79

Koordinatensystem: korrigiertes Kamerakoordinatensystem (kKKS): verschobenes USK mit Ursprung in der Kamera. Beachte NV_Sensor_Position_X,Y,Z  ";
CM_ SG_ 598 NV_Obj_03_RadialDistanzRed "Radiale Distanz des Zielobjektes 

Koordinatensystem: korrigiertes Kamerakoordinatensystem (kKKS): verschobenes USK mit Ursprung in der Kamera. Beachte NV_Sensor_Position_X,Y,Z";
CM_ SG_ 598 NV_Obj_03_RadialDistanzRedStdA "Standardabweichung zur radialen Distanz des Zielobjektes 

Koordinatensystem: korrigiertes Kamerakoordinatensystem (kKKS): verschobenes USK mit Ursprung in der Kamera. Beachte NV_Sensor_Position_X,Y,Z ";
CM_ SG_ 598 NV_Obj_03_WnklHoehe "Hoehe des Objektes

Wertebereich in Grad: 
0 bis 25
Auflösung in Grad: 1,79

Koordinatensystem: korrigiertes Kamerakoordinatensystem (kKKS): verschobenes USK mit Ursprung in der Kamera. Beachte NV_Sensor_Position_X,Y,Z ";
CM_ SG_ 598 NV_Obj_03_WnklVertMitte "Vertikaler Mittelpunkt des Objektes

Wertebereich in Grad: 
-12,5 bis 12,5
Auflösung in Grad: 1,79

Koordinatensystem: korrigiertes Kamerakoordinatensystem (kKKS): verschobenes USK mit Ursprung in der Kamera. Beachte NV_Sensor_Position_X,Y,Z  ";

CM_ SG_ 601 NV_Obj_03_Gemessen "Status Objekt gemessen/getrackt

0 = Objekt nicht gemessen, nur per 3D Modell praediziert (auch BVS)
1 = Objekt wurde im aktuellen Zyklus gemessen
2 = Nur für Video: Objekt wurde nicht gemessen, sondern per Feature-Tracking wiedergefunden (Optischer F";
CM_ SG_ 601 NV_Obj_03_ID "ID des Objektes";
CM_ SG_ 601 NV_Obj_03_Klasse "Klasse des Objekts";
CM_ SG_ 601 NV_Obj_03_WnklBreite "Horizontale Breite des Objektes

Wertebereich in Grad: 
0 bis 27,8
Auflösung in Grad: 0,45

Koordinatensystem: korrigiertes Kamerakoordinatensystem (kKKS): verschobenes USK mit Ursprung in der Kamera. Beachte NV_Sensor_Position_X,Y,Z ";
CM_ SG_ 601 NV_Obj_03_WnklHorMitte "Horizontaler Mittelpunkt des Objektes

Wertebereich in Grad: 
-13,9 bis 13,9
Auflösung in Grad: 0,45

Koordinatensystem: korrigiertes Kamerakoordinatensystem (kKKS): verschobenes USK mit Ursprung in der Kamera. Beachte NV_Sensor_Position_X,Y,Z ";
CM_ SG_ 601 NV_Obj_04_Gemessen "Status Objekt gemessen/getrackt

0 = Objekt nicht gemessen, nur per 3D Modell praediziert (auch BVS)
1 = Objekt wurde im aktuellen Zyklus gemessen
2 = Nur für Video: Objekt wurde nicht gemessen, sondern per Feature-Tracking wiedergefunden (Optischer F";
CM_ SG_ 601 NV_Obj_04_ID "ID des Objektes";
CM_ SG_ 601 NV_Obj_04_Klasse "Klasse des Objekts";
CM_ SG_ 601 NV_Obj_04_RadialDistanzRed "Radiale Distanz des Zielobjektes 

Koordinatensystem: korrigiertes Kamerakoordinatensystem (kKKS): verschobenes USK mit Ursprung in der Kamera. Beachte NV_Sensor_Position_X,Y,Z";
CM_ SG_ 601 NV_Obj_04_RadialDistanzRedStdA "Standardabweichung zur radialen Distanz des Zielobjektes 

Koordinatensystem: korrigiertes Kamerakoordinatensystem (kKKS): verschobenes USK mit Ursprung in der Kamera. Beachte NV_Sensor_Position_X,Y,Z ";
CM_ SG_ 601 NV_Obj_04_WnklBreite "Horizontale Breite des Objektes

Wertebereich in Grad: 
0 bis 27,8
Auflösung in Grad: 0,45

Koordinatensystem: korrigiertes Kamerakoordinatensystem (kKKS): verschobenes USK mit Ursprung in der Kamera. Beachte NV_Sensor_Position_X,Y,Z ";
CM_ SG_ 601 NV_Obj_04_WnklHoehe "Hoehe des Objektes

Wertebereich in Grad: 
0 bis 25
Auflösung in Grad: 1,79

Koordinatensystem: korrigiertes Kamerakoordinatensystem (kKKS): verschobenes USK mit Ursprung in der Kamera. Beachte NV_Sensor_Position_X,Y,Z ";
CM_ SG_ 601 NV_Obj_04_WnklHorMitte "Horizontaler Mittelpunkt des Objektes

Wertebereich in Grad: 
-13,9 bis 13,9
Auflösung in Grad: 0,45

Koordinatensystem: korrigiertes Kamerakoordinatensystem (kKKS): verschobenes USK mit Ursprung in der Kamera. Beachte NV_Sensor_Position_X,Y,Z ";
CM_ SG_ 601 NV_Obj_04_WnklVertMitte "Vertikaler Mittelpunkt des Objektes

Wertebereich in Grad: 
-12,5 bis 12,5
Auflösung in Grad: 1,79

Koordinatensystem: korrigiertes Kamerakoordinatensystem (kKKS): verschobenes USK mit Ursprung in der Kamera. Beachte NV_Sensor_Position_X,Y,Z  ";

CM_ SG_ 1635 BEM_02_Abschaltstufen "Abschaltstufen des Ruhestrommanagements (Initialisierungswert aus EEprom)

Stufe 0 (keine Einschraenkungen)
Stufe 1 (Abschaltung Hochstromverbraucher)
Stufe 2 (Infotainmentabschaltung)
Stufe 3 (Wake-Up-Sperre)

Für den Transport- und Ruhestrommessm";
CM_ SG_ 1635 BEM_Anf_KL15_schalten "Abschaltempfehlung bzw. Verhinderung der automatischen Abschaltung Kl15 durch das BCM";
CM_ SG_ 1635 BEM_Batteriediagnose "Anzeige von Textwarnungen";
CM_ SG_ 1635 BEM_Generatordiagnose "Ansteuerung Generatorwarnleuchte im Kombi
";
CM_ SG_ 1635 BEM_HL_Regelung_Status "Status Regelung Heizleistung
";
CM_ SG_ 1635 BEM_Ladezustand "Ladezustand der Niedervoltbatterie
";
CM_ SG_ 1635 BEM_MMI_Vorwarnung "Anzeige Vorwarnung MMI-Abschaltung (Initialisierungswert aus EEprom)
";
CM_ SG_ 1635 BEM_Red_Innengeblaese "Reduzierung Innengebläse
";
CM_ SG_ 1635 BEM_REK_aktiv "Rekuperationsfreigabe vom Energiemanagement
0x0 = keine Rekuperationsfreigabe
0x1 = Rekuperationsfreigabe";
CM_ SG_ 1635 BEM_STH_Einschaltverbot "Einschränkung Standheizung/-lüftung durch BEM: Setzt der BEM das Bit, dann darf die Standheizung nicht mehr einschalten
(Die Standheizung muss aber nicht abschalten, sondern darf weiterbrennen)
(Initialisierungswert aus EEprom)
";
CM_ SG_ 1635 BEM_STH_Zielzeit "Maximal mögliche Zeit für den Standheizungsbetrieb, um die Startfähigkeit nicht zu gefährden";
CM_ SG_ 1635 BEM_UBDM "Batteriespannung, gemessen vom Batteriedatenmodul";
CM_ SG_ 1635 BEM_UGenSoll "Sollspannungsvorgabe an den Generator, beinhaltet temperaturoptimierte Batterieladung und Rekuperation";
CM_ SG_ 1635 MIB_Stromsparmodus "Signal beschreibt die Aktivierung für den Stromsparmodus beim MIB.
Bei AUS (= 0) gibt es keine weitere Anforderung an die MIB-Komponenten.
Bei EIN (= 1) werden alle MIB Komponenten in einen Stromsparmodus versetzt.";
CM_ SG_ 1635 NVEM_Anf_SD_schalten "Anforderung Nachlauf für den Steckdosenbetrieb
Initialisierungswert aus EEprom";
CM_ SG_ 1635 NVEM_Batterie_Service "Anforderung einer Batterie-Service - Anzeige / Anforderung an die Werkstatt über MOD";
CM_ SG_ 1635 NVEM_Freigabe_OnlineUpdate "Freigabe für Online-Update durch Energiemanagement";
CM_ SG_ 1635 NVEM_Freigabe_ORU4 "Bestätigung oder Ablehnung eines konkreten, angefragten Online Updates durch das Energiemanagements";
CM_ SG_ 1635 NVEM_Last_Anf "Das NVEM fordert für die Batteriediagnose einen Lastimpuls vom Fahrzeug an, der durch kontrollierte Verbraucherzuschaltungen (z. B. Aktivierung Heckscheibenheizung) generiert wird";

CM_ SG_ 913 MO_QBit_Aussen_Temp "QBit der Aussentemperatur. Gesetzt bei Ersatzwert, Init oder Fehler.";
CM_ SG_ 913 MO_Servicemodus "Ausgabe aktiver Service-Mode";
CM_ SG_ 913 OBD_Abs_Load_Val "Absolute Load Value

Übertragung von Meßgrößen an das Getriebesteuergerät für Freeze Frame Abspeicherung bei Getriebefehlern

PID $43 Absolute Load Value; 0 .. 25700%  mit 100/255 %/bit";
CM_ SG_ 913 OBD_Abs_Pedal_Pos "Absolute Pedal Position

Übertragung von Meßgrößen an das Getriebesteuergerät für Freeze Frame Abspeicherung bei Getriebefehlern

PID $49 Accelerator Pedal Position D; 0 .. 100% mit 100/255 %/bit";
CM_ SG_ 913 OBD_Abs_Throttle_Pos "Absolute Throttle Position

Übertragung von Meßgrößen an das Getriebesteuergerät für Freeze Frame Abspeicherung bei Getriebefehlern

PID $11 Absolute Throttle Position; 0 .. 100% mit 100/255 %/bit";
CM_ SG_ 913 OBD_Calc_Load_Val "Calculated Load Value

Übertragung von Meßgrößen an das Getriebesteuergerät für Freeze Frame Abspeicherung bei Getriebefehlern

PID $04 Calculated Load Value; 0 .. 100% mit 100/255 % per bit
";
CM_ SG_ 913 OBD_ClearMem_Inhibit "Das Fehlerspeicher löschen soll nur noch bei stehendem Fahrzeug über Service-04hex ausgeführt werden, dafür wird vom MIL-Master ein CAN Signal benötigt, das das Löschen unter bestimmten Randbedingungen nicht zulässig ist";
CM_ SG_ 913 OBD_Eng_Cool_Temp "Engine Coolant Temperature

Übertragung von Meßgrößen an das Getriebesteuergerät für Freeze Frame Abspeicherung bei Getriebefehlern

PID $05 Engine Coolant Temperature; -40 .. +215°C mit 1°C/bit und 40°C Offset";
CM_ SG_ 913 OBD_Kaltstart_Denominator "Bestimmte Diagnosen werden nur unter Kaltstartbedingungen durchgeführt, der entsprechende Denominator bei IUMPR-pflichtigen Systemen wird anhand dieses vom MSG gebildeten Signals inkrementiert. (Entspricht EVAP-Denominator)";
CM_ SG_ 913 OBD_Minimum_Trip "Grundlage OBD-Gesetz CCR 1968.2 (d)(4.3) Denominator Specifications
Bildung des General Denominator 'Normed Trip':
 600 sec. (kumulativ) Zeit nach Motorstart
 300 sec. (kumulativ) mit Fahrzeuggeschwindigkeit > 25 mph (40 km/h)
 30 sec. (kontinuierlich";
CM_ SG_ 913 OBD_Normed_Trip "Gesetzlich definierte 'Normed Condition' erfüllt, 'General Denominator' darf erhöht werden";
CM_ SG_ 913 OBD_Sperrung_IUMPR "Wenn der General Denominator auf Grund eines Fehlers in den Eingangsgrößen gesperrt wird, wird diese Information über Bussystem als OBD-Statusinformation OBD_Sperrung_IUMPR für andere OBD-Steuergeräte bereitgestellt. 

Das MSG (MIL-Master) setzt dieses ";
CM_ SG_ 913 OBD_Sperrung_Kaltstart_Denom "Information vom MIL Master, dass die Bildung des EVAP Denominators  im Motor nicht möglich ist und damit der noECM-Denominator gesperrt werden darf.";
CM_ SG_ 913 OBD_Warm_Up_Cycle "Mit dem Warm-Up-Cycle wird der zentrale Verlernzähler vom Gateway inkrementiert";

CM_ SG_ 2589283478 OBD_Aussen_Temp_gef "Gefilterte Aussentemperatur vom Motor für OBD Funktionen.";

CM_ SG_ 2549940736 OBDC_Funktionaler_Req_All_Data "VDC funktionaler Request auf CANHS";

CM_ SG_ 2589283656 ORU_Status "Broadcast des Status der Konzernfunktion Online Remote Update";
CM_ SG_ 2589283656 ORU_Warnung "Wenn durch Störungen der Funktion Online Remote Update nicht sichergestellt ist, dass vor Kunde keine Funktionseinschränkungen auftreten, muss der Benutzer des Fahrzeugs entsprechend gewarnt werden.";

CM_ SG_ 1175 PDC_Tonausgabe_Front "In Abhängigkeit der Systemaktivitäten werden unterschiedliche Tonwarnungen ausgegeben. 
Kombi spielt entsprechende WAV.-Datei über internen Audiomaster ab.

0 = kein Ton
1 = Intervallton 1
2 = Intervallton 2
3 = Intervallton 3
4 = Intervallton 4
5";
CM_ SG_ 1175 PDC_Tonausgabe_Heck "In Abhängigkeit der Systemaktivitäten werden unterschiedliche Tonwarnungen ausgegeben. 
Kombi spielt entsprechende WAV.-Datei über internen Audiomaster ab.

0 = kein Ton
1 = Intervallton 1
2 = Intervallton 2
3 = Intervallton 3
4 = Intervallton 4
5";
CM_ SG_ 1175 PH_Abschaltursache "Abschaltursache bleibt bis zur nächsten Aktivierung bzw. bis KL15 aus gesetzt
Im Fehlerfall (blinkende LED) wird '7' gesendet obwohl das System noch aktiv ist, bei 'geheiltem' Fehler wird sofort wieder der Zustand '0' gesendet";
CM_ SG_ 1175 PH_Anf_Audioabsenkung "Es gibt zwei unterschiedliche Nachlauftimer für dieses Bit:
1. normale Funktion
2. Demotonausgabe";
CM_ SG_ 1175 PH_Anf_Verdeck "Anforderung an ein Verdeck-System, die vom Fahrer angeforderte Öffnung/Schließung zu verhindern";
CM_ SG_ 1175 PH_defekt "Zeigt an das sich die Parkhilfe im Fehlerzustand befindet. Signal bleibt bis zur nächsten 'Gut-Aktivierung' gesetzt.
Spezialfall: Sensordefekt hinten bei Anhängerbetrieb. Anhänger wird abgesteckt Fehler wird gesetzt. Fehlerfall bleibt bis Behebung des De";
CM_ SG_ 1175 PH_Display_Kundenwunsch "Anzeige der bei Aktivierung verwendeten Parameter bzgl. Kundenwunsch Displayanziege. Änderungen werden erst bei erneuter Aktivierung aktualisiert.";
CM_ SG_ 1175 PH_Frequenz_hinten "Uebertragung der aktuell im APS Steuergeraet gespeicherten Werte fuer Tongeber Frequenz hinten
Anzeige der aktuell verwendeten Parameter (nicht zwingend die abgespeicherten - da Werte erst 2s nach der letzten Änderung gespeichert werden!)";
CM_ SG_ 1175 PH_Frequenz_vorn "Uebertragung der aktuell im APS Steuergeraet gespeicherten Werte fuer Tongeber Frequenz vorne
Anzeige der aktuell verwendeten Parameter (nicht zwingend die abgespeicherten - da Werte erst 2s nach der letzten Änderung gespeichert werden!)";
CM_ SG_ 1175 PH_gestoert "Eine Störung ist aufgetreten, der die Parkhilfe in einen 'gestört-Zustand' versetzt, z.B. massiver Fremdultraschall, Vereisung, Schnee.Derzeit nur für Störschall benutzt, da keinerlei andere Erkennung implementiert.";
CM_ SG_ 1175 PH_Lautstaerke_hinten "Uebertragung der aktuell im APS Steuergeraet gespeicherten Werte fuer Tongeber Lautstaerke hinten
Anzeige der aktuell verwendeten Parameter (nicht zwingend die abgespeicherten - da Werte erst 2s nach der letzten Änderung gespeichert werden!)";
CM_ SG_ 1175 PH_Lautstaerke_vorn "Uebertragung der aktuell im APS Steuergeraet gespeicherten Werte fuer Tongeber Lautstaerke vorn.
Anzeige der aktuell verwendeten Parameter (nicht zwingend die abgespeicherten - da Werte erst 2s nach der letzten Änderung gespeichert werden!)";
CM_ SG_ 1175 PH_nachtr_Stopp_Anf "Dieses Signal dient dem Motor als Trigger, dass ein nachträglicher Motorstopp eingeleitet werden kann, wenn es die Bedingungen des StSt Koordinators dies zulassen. ";
CM_ SG_ 1175 PH_Opt_Anz_H_Hindernis "mindestens 1 Segment wird für den hinteren Detekionsbereich dargestellt, also ein Hindernis ist im Detektionsbereich. Funktion nur bei gesicherter Rückmeldung vom ASG gegeben.";
CM_ SG_ 1175 PH_Opt_Anz_V_Hindernis "mindestens 1 Segment wird für den vorderen Detekionsbereich dargestellt, also ein Hindernis ist im Detektionsbereich. Funktion nur bei gesicherter Rückmeldung vom ASG gegeben.";
CM_ SG_ 1175 PH_Opt_Anzeige_H_ein "OPS hinten ist im Display aktiv bzw. Anzeigemodule hinten sind eingeschaltet. Funktion nur bei gesicherter Rückmeldung vom ASG gegeben.";
CM_ SG_ 1175 PH_Opt_Anzeige_V_ein "OPS vorne ist im Display aktiv bzw. Anzeigemodule vorne sind eingeschaltet. Funktion nur bei gesicherter Rückmeldung vom ASG gegeben.";
CM_ SG_ 1175 PH_StartStopp_Info "Stopp-Freigabe und Start-Anforderung an den Start-Stopp-Koordinator";
CM_ SG_ 1175 PH_Stoermeldung "Meldung einer Störung der PDC an das Kombi";
CM_ SG_ 1175 PH_Systemzustand "Aktivierungsursache wird für die Dauer der Aktivierung gemeldet.
Im Fehlerfall bei atkviem System wechselt das Signal auf '7'
(siehe auch 'Abschaltursache')";
CM_ SG_ 1175 PH_Taster "Taster Status (für RVC/TopView)";
CM_ SG_ 1175 PH_Tongeber_H_aktiv "Rohsignal für 'Tongeber hinten wird angesteuert', verlängerbar mit Nachlauftimer.
Bit wird nicht während des Stellgliedtests angesteuert.";
CM_ SG_ 1175 PH_Tongeber_H_verfuegbar "Tongeber ist für die Tonausgabe für externe Funktionen verfügbar. PDC ist aktiv und Tongeber ist nicht gestört.";
CM_ SG_ 1175 PH_Tongeber_mute "Die Akustikausgabe des Systems wird unterdrückt, z.B. Wählhebel in 'P', Parlbremse geschlossen (8-Kanal-System)";
CM_ SG_ 1175 PH_Tongeber_V_aktiv "Rohsignal für 'Tongeber vorne wird angesteuert', verlängerbar mit Nachlauftimer.
Bit wird nicht während des Stellgliedtests angesteuert.";
CM_ SG_ 1175 PH_Visualisierung "Signal zeigt den Partnersteuergeräten RearView/TopView/ARA/... den aktuellen Status der Visualisierung des OPS. Die Partnersteuergeräte können dadurch auch ihre Aufschaltung an dieses Signal koppeln.";
CM_ SG_ 1175 PLA_Anf_Aufschaltung_RVC "Anforderung der Aufschaltung RVC durch PLA";

CM_ SG_ 1353 PL_Luecke_P0_x "x-Koordinate des Punktes P0
";
CM_ SG_ 1353 PL_Luecke_P0_y "y-Koordinate des Punktes P0";
CM_ SG_ 1353 PL_Luecke_P2_x "x-Koordinate des Punktes P2";
CM_ SG_ 1353 PL_Luecke_P2_y "y-Koordinate des Punktes P2";

CM_ SG_ 1354 PL_Luecke_P1_x "x-Koordinate des Punktes P1";
CM_ SG_ 1354 PL_Luecke_P1_y "y-Koordinate des Punktes P1";
CM_ SG_ 1354 PL_Luecke_P3_x "x-Koordinate des Punktes P3";
CM_ SG_ 1354 PL_Luecke_P3_y "y-Koordinate des Punktes P3";
BA_DEF_REL_ BU_SG_REL_  "GenSigTimeoutTime" INT 0 65535;
BA_DEF_ BO_  "DiagRequest" ENUM "No", "Yes";
BA_DEF_ BO_  "DiagResponse" ENUM "No", "Yes";
BA_DEF_ BO_  "DiagState" ENUM "No", "Yes";
BA_DEF_ BO_  "GenMsgChkConstant" HEX 0 4095;
BA_DEF_ BO_  "GenMsgCycleTime" INT 0 65535;
BA_DEF_ BO_  "GenMsgCycleTimeFast" INT 0 65535;
BA_DEF_ BO_  "GenMsgDelayTime" INT 0 100000;
BA_DEF_ BO_  "GenMsgILSupport" ENUM "No", "Yes";
BA_DEF_ BO_  "GenMsgNrOfRepetition" INT 0 100;
BA_DEF_ BO_  "GenMsgPDUConstants" STRING;
BA_DEF_ BO_  "GenMsgSendType" ENUM "Cyclic", "not_used", "not_used", "not_used", "not_used", "not_used", "not_used", "IfActive", "NoMsgSendType";
BA_DEF_ BO_  "GenMsgStartDelayTime" INT 0 100000;
BA_DEF_ BO_  "NmMessage" ENUM "No", "Yes";
BA_DEF_ BO_  "NmhMessage" ENUM "No", "Yes";
BA_DEF_ BO_  "MsgType" ENUM "Application", "NM ", "NMH", "TP2.0", "ISO-TP ", "BAP", "EID", "KS";
BA_DEF_ BO_  "VAGTP20_API" HEX 0 255;
BA_DEF_ BO_  "VAGTP20_DynConnection" ENUM "No", "Yes";
BA_DEF_ BO_  "VAGTP20_DynSetup" ENUM "No", "Yes";
BA_DEF_ BO_  "VAGTP20_StatConnection" ENUM "No", "Yes";
BA_DEF_ SG_  "GenSigActiveRepetitions" INT -2147483648 2147483647;
BA_DEF_ SG_  "GenSigInactiveValue" INT -2147483648 2147483647;
BA_DEF_ SG_  "GenSigSendType" ENUM "Cyclic", "OnWrite", "OnWriteWithRepetition", "OnChange", "OnChangeWithRepetition", "IfActive", "IfActiveWithRepetition", "NoSigSendType", "OnChangeAndIfActive", "OnChangeAndIfActiveWithRepetition";
BA_DEF_ SG_  "GenSigStartValue" INT -2147483648 2147483647;
BA_DEF_ SG_  "NWM-WakeupAllowed" ENUM "No", "Yes";
BA_DEF_ SG_  "GenSigFuncType" ENUM "NoFunction", "MsgCounter", "CRC-8", "XOR", "XOR-2", "DatedBit", "SW-Kl15", "CHK", "Constant", "Protocol", "CRC-8-SAE_J1850";
BA_DEF_ SG_  "GenSigSwitchedByIgnition" ENUM "No", "Yes";
BA_DEF_ SG_  "Fehlerwert" HEX 0 2147483647;
BA_DEF_ SG_  "GenSigMissingSourceValue" HEX 0 2147483647;
BA_DEF_DEF_REL_  "GenSigTimeoutTime" 0;
BA_DEF_DEF_  "DiagRequest" "No";
BA_DEF_DEF_  "DiagResponse" "No";
BA_DEF_DEF_  "DiagState" "No";
BA_DEF_DEF_  "GenMsgChkConstant" 0;
BA_DEF_DEF_  "GenMsgCycleTime" 0;
BA_DEF_DEF_  "GenMsgCycleTimeFast" 0;
BA_DEF_DEF_  "GenMsgDelayTime" 0;
BA_DEF_DEF_  "GenMsgILSupport" "No";
BA_DEF_DEF_  "GenMsgNrOfRepetition" 0;
BA_DEF_DEF_  "GenMsgPDUConstants" "";
BA_DEF_DEF_  "GenMsgSendType" "NoMsgSendType";
BA_DEF_DEF_  "GenMsgStartDelayTime" 0;
BA_DEF_DEF_  "NmMessage" "No";
BA_DEF_DEF_  "NmhMessage" "No";
BA_DEF_DEF_  "MsgType" "Application";
BA_DEF_DEF_  "VAGTP20_API" 0;
BA_DEF_DEF_  "VAGTP20_DynConnection" "No";
BA_DEF_DEF_  "VAGTP20_DynSetup" "No";
BA_DEF_DEF_  "VAGTP20_StatConnection" "No";
BA_DEF_DEF_  "GenSigActiveRepetitions" 0;
BA_DEF_DEF_  "GenSigInactiveValue" 0;
BA_DEF_DEF_  "GenSigSendType" "NoSigSendType";
BA_DEF_DEF_  "GenSigStartValue" 0;
BA_DEF_DEF_  "NWM-WakeupAllowed" "No";
BA_DEF_DEF_  "GenSigFuncType" "NoFunction";
BA_DEF_DEF_  "GenSigSwitchedByIgnition" "Yes";
BA_DEF_DEF_  "Fehlerwert" 0;
BA_DEF_DEF_  "GenSigMissingSourceValue" 0;
BA_ "GenMsgCycleTime" BO_ 289 50;
BA_ "GenMsgILSupport" BO_ 289 1;
BA_ "GenMsgPDUConstants" BO_ 289 "0xe9,0x65,0xae,0x6b,0x7b,0x35,0xe5,0x5f,0x4e,0xc7,0x86,0xa2,0xbb,0xdd,0xeb,0xb4";
BA_ "GenMsgSendType" BO_ 289 0;
BA_ "GenMsgCycleTime" BO_ 1423 320;
BA_ "GenMsgILSupport" BO_ 1423 1;
BA_ "GenMsgSendType" BO_ 1423 0;
BA_ "GenMsgCycleTime" BO_ 340 200;
BA_ "GenMsgILSupport" BO_ 340 1;
BA_ "GenMsgPDUConstants" BO_ 340 "0x21,0x93,0x4a,0x04,0x5c,0x18,0xe0,0x69,0x14,0xce,0x26,0x8f,0x5e,0xb1,0xdf,0x53";
BA_ "GenMsgSendType" BO_ 340 0;
BA_ "GenMsgChkConstant" BO_ 1601 71;
BA_ "GenMsgCycleTime" BO_ 1601 960;
BA_ "GenMsgILSupport" BO_ 1601 1;
BA_ "GenMsgPDUConstants" BO_ 1601 "0x47,0x47,0x47,0x47,0x47,0x47,0x47,0x47,0x47,0x47,0x47,0x47,0x47,0x47,0x47,0x47";
BA_ "GenMsgSendType" BO_ 1601 0;
BA_ "GenMsgCycleTime" BO_ 305 20;
BA_ "GenMsgILSupport" BO_ 305 1;
BA_ "GenMsgSendType" BO_ 305 0;
BA_ "GenMsgCycleTime" BO_ 394 200;
BA_ "GenMsgDelayTime" BO_ 394 10;
BA_ "GenMsgILSupport" BO_ 394 1;
BA_ "GenMsgSendType" BO_ 394 0;
BA_ "GenMsgStartDelayTime" BO_ 394 20;
BA_ "GenMsgCycleTime" BO_ 234 10;
BA_ "GenMsgILSupport" BO_ 234 1;
BA_ "GenMsgPDUConstants" BO_ 234 "0x79,0xdb,0x11,0x86,0xb6,0x29,0x9c,0x0d,0xdc,0x1c,0x4a,0xbd,0xb8,0x2d,0xc1,0xab";
BA_ "GenMsgSendType" BO_ 234 0;
BA_ "GenMsgCycleTime" BO_ 849 320;
BA_ "GenMsgDelayTime" BO_ 849 80;
BA_ "GenMsgILSupport" BO_ 849 1;
BA_ "GenMsgSendType" BO_ 849 0;
BA_ "GenMsgCycleTime" BO_ 2463978596 2000;
BA_ "GenMsgDelayTime" BO_ 2463978596 50;
BA_ "GenMsgILSupport" BO_ 2463978596 1;
BA_ "GenMsgSendType" BO_ 2463978596 0;
BA_ "GenMsgCycleTime" BO_ 848 500;
BA_ "GenMsgDelayTime" BO_ 848 100;
BA_ "GenMsgILSupport" BO_ 848 1;
BA_ "GenMsgSendType" BO_ 848 0;
BA_ "GenMsgCycleTime" BO_ 1696 200;
BA_ "GenMsgDelayTime" BO_ 1696 20;
BA_ "GenMsgILSupport" BO_ 1696 1;
BA_ "GenMsgSendType" BO_ 1696 0;
BA_ "GenMsgCycleTime" BO_ 2600468496 200;
BA_ "GenMsgCycleTimeFast" BO_ 2600468496 10;
BA_ "GenMsgNrOfRepetition" BO_ 2600468496 3;
BA_ "GenMsgSendType" BO_ 2600468496 7;
BA_ "NmhMessage" BO_ 2600468496 1;
BA_ "MsgType" BO_ 2600468496 2;
BA_ "GenMsgCycleTime" BO_ 2600468519 200;
BA_ "GenMsgCycleTimeFast" BO_ 2600468519 10;
BA_ "GenMsgNrOfRepetition" BO_ 2600468519 3;
BA_ "GenMsgSendType" BO_ 2600468519 7;
BA_ "NmhMessage" BO_ 2600468519 1;
BA_ "MsgType" BO_ 2600468519 2;
BA_ "GenMsgCycleTime" BO_ 2600468491 200;
BA_ "GenMsgCycleTimeFast" BO_ 2600468491 10;
BA_ "GenMsgNrOfRepetition" BO_ 2600468491 3;
BA_ "GenMsgSendType" BO_ 2600468491 7;
BA_ "NmhMessage" BO_ 2600468491 1;
BA_ "MsgType" BO_ 2600468491 2;
BA_ "GenMsgCycleTime" BO_ 2600468585 200;
BA_ "GenMsgCycleTimeFast" BO_ 2600468585 10;
BA_ "GenMsgNrOfRepetition" BO_ 2600468585 3;
BA_ "GenMsgSendType" BO_ 2600468585 7;
BA_ "NmhMessage" BO_ 2600468585 1;
BA_ "MsgType" BO_ 2600468585 2;
BA_ "GenMsgCycleTime" BO_ 2600468522 200;
BA_ "GenMsgCycleTimeFast" BO_ 2600468522 10;
BA_ "GenMsgNrOfRepetition" BO_ 2600468522 3;
BA_ "GenMsgSendType" BO_ 2600468522 7;
BA_ "NmhMessage" BO_ 2600468522 1;
BA_ "MsgType" BO_ 2600468522 2;
BA_ "GenMsgCycleTime" BO_ 2600468586 200;
BA_ "GenMsgCycleTimeFast" BO_ 2600468586 10;
BA_ "GenMsgNrOfRepetition" BO_ 2600468586 3;
BA_ "GenMsgSendType" BO_ 2600468586 7;
BA_ "NmhMessage" BO_ 2600468586 1;
BA_ "MsgType" BO_ 2600468586 2;
BA_ "GenMsgCycleTime" BO_ 2600468558 200;
BA_ "GenMsgCycleTimeFast" BO_ 2600468558 10;
BA_ "GenMsgNrOfRepetition" BO_ 2600468558 3;
BA_ "GenMsgSendType" BO_ 2600468558 7;
BA_ "NmhMessage" BO_ 2600468558 1;
BA_ "MsgType" BO_ 2600468558 2;
BA_ "GenMsgCycleTime" BO_ 2600468618 200;
BA_ "GenMsgCycleTimeFast" BO_ 2600468618 10;
BA_ "GenMsgNrOfRepetition" BO_ 2600468618 3;
BA_ "GenMsgSendType" BO_ 2600468618 7;
BA_ "NmhMessage" BO_ 2600468618 1;
BA_ "MsgType" BO_ 2600468618 2;
BA_ "GenMsgCycleTime" BO_ 1377 40;
BA_ "GenMsgILSupport" BO_ 1377 1;
BA_ "GenMsgSendType" BO_ 1377 0;
BA_ "GenMsgCycleTime" BO_ 597 40;
BA_ "GenMsgILSupport" BO_ 597 1;
BA_ "GenMsgSendType" BO_ 597 0;
BA_ "GenMsgCycleTime" BO_ 598 40;
BA_ "GenMsgILSupport" BO_ 598 1;
BA_ "GenMsgSendType" BO_ 598 0;
BA_ "GenMsgCycleTime" BO_ 601 40;
BA_ "GenMsgILSupport" BO_ 601 1;
BA_ "GenMsgSendType" BO_ 601 0;
BA_ "GenMsgCycleTime" BO_ 1635 100;
BA_ "GenMsgILSupport" BO_ 1635 1;
BA_ "GenMsgSendType" BO_ 1635 0;
BA_ "GenMsgStartDelayTime" BO_ 1635 10;
BA_ "GenMsgCycleTime" BO_ 913 200;
BA_ "GenMsgILSupport" BO_ 913 1;
BA_ "GenMsgSendType" BO_ 913 0;
BA_ "GenMsgCycleTime" BO_ 2589283478 320;
BA_ "GenMsgILSupport" BO_ 2589283478 1;
BA_ "GenMsgSendType" BO_ 2589283478 0;
BA_ "MsgType" BO_ 2549875246 4;
BA_ "MsgType" BO_ 2550006318 4;
BA_ "MsgType" BO_ 2549875248 4;
BA_ "MsgType" BO_ 2550006320 4;
BA_ "DiagState" BO_ 2549940736 1;
BA_ "MsgType" BO_ 2549940736 4;
BA_ "MsgType" BO_ 2549875239 4;
BA_ "MsgType" BO_ 2550006311 4;
BA_ "MsgType" BO_ 2549875211 4;
BA_ "MsgType" BO_ 2550006283 4;
BA_ "MsgType" BO_ 2549875305 4;
BA_ "MsgType" BO_ 2550006377 4;
BA_ "MsgType" BO_ 2549875242 4;
BA_ "MsgType" BO_ 2550006314 4;
BA_ "MsgType" BO_ 2549875300 4;
BA_ "MsgType" BO_ 2550006372 4;
BA_ "MsgType" BO_ 2549875228 4;
BA_ "MsgType" BO_ 2550006300 4;
BA_ "MsgType" BO_ 2549875306 4;
BA_ "MsgType" BO_ 2550006378 4;
BA_ "MsgType" BO_ 2549875338 4;
BA_ "MsgType" BO_ 2550006410 4;
BA_ "MsgType" BO_ 2549875278 4;
BA_ "MsgType" BO_ 2550006350 4;
BA_ "GenMsgCycleTime" BO_ 2589283656 960;
BA_ "GenMsgDelayTime" BO_ 2589283656 160;
BA_ "GenMsgILSupport" BO_ 2589283656 1;
BA_ "GenMsgSendType" BO_ 2589283656 0;
BA_ "GenMsgCycleTime" BO_ 1175 100;
BA_ "GenMsgDelayTime" BO_ 1175 50;
BA_ "GenMsgILSupport" BO_ 1175 1;
BA_ "GenMsgSendType" BO_ 1175 0;
BA_ "GenMsgCycleTimeFast" BO_ 1353 100;
BA_ "GenMsgILSupport" BO_ 1353 1;
BA_ "GenMsgSendType" BO_ 1353 7;
BA_ "GenMsgCycleTimeFast" BO_ 1354 100;
BA_ "GenMsgILSupport" BO_ 1354 1;
BA_ "GenMsgSendType" BO_ 1354 7;
BA_ "GenSigSendType" SG_ 289 MO_Entkopplung_Sollschlupf 0;
BA_ "GenSigStartValue" SG_ 289 MO_Entkopplung_Sollschlupf 126;
BA_ "GenSigSwitchedByIgnition" SG_ 289 MO_Entkopplung_Sollschlupf 0;
BA_ "GenSigSendType" SG_ 289 MO_Fahrpedalgradient 0;
BA_ "GenSigSwitchedByIgnition" SG_ 289 MO_Fahrpedalgradient 0;
BA_ "Fehlerwert" SG_ 289 MO_Fahrpedalgradient 255;
BA_ "GenSigSendType" SG_ 289 MO_Fahrpedalrohwert_01 0;
BA_ "GenSigSwitchedByIgnition" SG_ 289 MO_Fahrpedalrohwert_01 0;
BA_ "Fehlerwert" SG_ 289 MO_Fahrpedalrohwert_01 255;
BA_ "GenSigSendType" SG_ 289 MO_Moment_im_Leerlauf 0;
BA_ "GenSigSwitchedByIgnition" SG_ 289 MO_Moment_im_Leerlauf 0;
BA_ "GenSigSendType" SG_ 289 MO_QBit_Fahrpedalwerte_01 0;
BA_ "GenSigStartValue" SG_ 289 MO_QBit_Fahrpedalwerte_01 1;
BA_ "GenSigSwitchedByIgnition" SG_ 289 MO_QBit_Fahrpedalwerte_01 0;
BA_ "GenSigSendType" SG_ 289 MO_rel_Saugrohrdruck 0;
BA_ "GenSigSwitchedByIgnition" SG_ 289 MO_rel_Saugrohrdruck 0;
BA_ "Fehlerwert" SG_ 289 MO_rel_Saugrohrdruck 63;
BA_ "GenSigSendType" SG_ 289 MO_rel_Saugrohrdruck_gem_err 0;
BA_ "GenSigSwitchedByIgnition" SG_ 289 MO_rel_Saugrohrdruck_gem_err 0;
BA_ "GenSigSendType" SG_ 289 MO_Schubabschaltung 0;
BA_ "GenSigSwitchedByIgnition" SG_ 289 MO_Schubabschaltung 0;
BA_ "GenSigSendType" SG_ 289 MO_Sig_Fahrpedalgradient 0;
BA_ "GenSigSwitchedByIgnition" SG_ 289 MO_Sig_Fahrpedalgradient 0;
BA_ "GenSigSendType" SG_ 289 MO_Solldrehz_Leerlauf 0;
BA_ "GenSigSwitchedByIgnition" SG_ 289 MO_Solldrehz_Leerlauf 0;
BA_ "GenSigSendType" SG_ 289 MO_StartStopp_StoppVorbereitung 0;
BA_ "GenSigSwitchedByIgnition" SG_ 289 MO_StartStopp_StoppVorbereitung 0;
BA_ "GenSigSendType" SG_ 289 MO_temporaere_Fahrerabwesenheit 0;
BA_ "GenSigSwitchedByIgnition" SG_ 289 MO_temporaere_Fahrerabwesenheit 0;
BA_ "GenSigSendType" SG_ 289 Motor_20_BZ 0;
BA_ "GenSigFuncType" SG_ 289 Motor_20_BZ 1;
BA_ "GenSigSwitchedByIgnition" SG_ 289 Motor_20_BZ 0;
BA_ "GenSigSendType" SG_ 289 Motor_20_CRC 0;
BA_ "GenSigFuncType" SG_ 289 Motor_20_CRC 2;
BA_ "GenSigSwitchedByIgnition" SG_ 289 Motor_20_CRC 0;
BA_ "GenSigSendType" SG_ 289 TSK_a_Soll_gradientenbegrenzt 0;
BA_ "GenSigStartValue" SG_ 289 TSK_a_Soll_gradientenbegrenzt 127;
BA_ "GenSigSwitchedByIgnition" SG_ 289 TSK_a_Soll_gradientenbegrenzt 0;
BA_ "GenSigSendType" SG_ 1423 FSA_Fehlerpfade_Initialisieren 0;
BA_ "GenSigSwitchedByIgnition" SG_ 1423 FSA_Fehlerpfade_Initialisieren 0;
BA_ "GenSigSendType" SG_ 1423 MO_FSA_Sensorheizung 0;
BA_ "GenSigSwitchedByIgnition" SG_ 1423 MO_FSA_Sensorheizung 0;
BA_ "GenSigSendType" SG_ 1423 MO_Getriebe_Oelalterung 0;
BA_ "GenSigSwitchedByIgnition" SG_ 1423 MO_Getriebe_Oelalterung 0;
BA_ "GenSigSendType" SG_ 1423 MO_ITM_Status 0;
BA_ "GenSigStartValue" SG_ 1423 MO_ITM_Status 14;
BA_ "GenSigSwitchedByIgnition" SG_ 1423 MO_ITM_Status 0;
BA_ "Fehlerwert" SG_ 1423 MO_ITM_Status 15;
BA_ "GenSigSendType" SG_ 1423 MO_KJS_LLK_Pos_Summe 0;
BA_ "GenSigStartValue" SG_ 1423 MO_KJS_LLK_Pos_Summe 14;
BA_ "GenSigSwitchedByIgnition" SG_ 1423 MO_KJS_LLK_Pos_Summe 0;
BA_ "GenSigSendType" SG_ 1423 MO_Kuehlmittel_Temp_Rohwert 0;
BA_ "GenSigStartValue" SG_ 1423 MO_Kuehlmittel_Temp_Rohwert 254;
BA_ "GenSigSwitchedByIgnition" SG_ 1423 MO_Kuehlmittel_Temp_Rohwert 0;
BA_ "Fehlerwert" SG_ 1423 MO_Kuehlmittel_Temp_Rohwert 255;
BA_ "GenSigSendType" SG_ 1423 MO_Oel_Temp_Radsatz 0;
BA_ "GenSigStartValue" SG_ 1423 MO_Oel_Temp_Radsatz 254;
BA_ "GenSigSwitchedByIgnition" SG_ 1423 MO_Oel_Temp_Radsatz 0;
BA_ "Fehlerwert" SG_ 1423 MO_Oel_Temp_Radsatz 255;
BA_ "GenSigSendType" SG_ 1423 MO_Tankdruck 0;
BA_ "GenSigStartValue" SG_ 1423 MO_Tankdruck 254;
BA_ "GenSigSwitchedByIgnition" SG_ 1423 MO_Tankdruck 0;
BA_ "Fehlerwert" SG_ 1423 MO_Tankdruck 255;
BA_ "GenSigSendType" SG_ 340 MO_Drehzahl_VM 0;
BA_ "GenSigSwitchedByIgnition" SG_ 340 MO_Drehzahl_VM 0;
BA_ "GenSigSendType" SG_ 340 MO_Fehlerstatus_Antrieb_FDR 0;
BA_ "GenSigSendType" SG_ 340 MO_IstMoment_VKM 0;
BA_ "GenSigStartValue" SG_ 340 MO_IstMoment_VKM 1022;
BA_ "GenSigSwitchedByIgnition" SG_ 340 MO_IstMoment_VKM 0;
BA_ "GenSigSendType" SG_ 340 MO_Mom_Begr_Schalt 0;
BA_ "GenSigStartValue" SG_ 340 MO_Mom_Begr_Schalt 1022;
BA_ "GenSigSwitchedByIgnition" SG_ 340 MO_Mom_Begr_Schalt 0;
BA_ "GenSigSendType" SG_ 340 MO_Mom_Begr_Schalt_Min 0;
BA_ "GenSigStartValue" SG_ 340 MO_Mom_Begr_Schalt_Min 1022;
BA_ "GenSigSwitchedByIgnition" SG_ 340 MO_Mom_Begr_Schalt_Min 0;
BA_ "GenSigSendType" SG_ 340 MO_Primaerachse_Anforderung 0;
BA_ "GenSigSwitchedByIgnition" SG_ 340 MO_Primaerachse_Anforderung 0;
BA_ "GenSigSendType" SG_ 340 Motor_28_BZ 0;
BA_ "GenSigFuncType" SG_ 340 Motor_28_BZ 1;
BA_ "GenSigSwitchedByIgnition" SG_ 340 Motor_28_BZ 0;
BA_ "GenSigSendType" SG_ 340 Motor_28_CRC 0;
BA_ "GenSigFuncType" SG_ 340 Motor_28_CRC 2;
BA_ "GenSigSwitchedByIgnition" SG_ 340 Motor_28_CRC 0;
BA_ "GenSigSendType" SG_ 1601 MO_Ansaugsystem 0;
BA_ "GenSigFuncType" SG_ 1601 MO_Ansaugsystem 8;
BA_ "GenSigSwitchedByIgnition" SG_ 1601 MO_Ansaugsystem 0;
BA_ "GenSigSendType" SG_ 1601 MO_Anzahl_Zyl 0;
BA_ "GenSigFuncType" SG_ 1601 MO_Anzahl_Zyl 8;
BA_ "GenSigSwitchedByIgnition" SG_ 1601 MO_Anzahl_Zyl 0;
BA_ "GenSigSendType" SG_ 1601 MO_Anzeige_StSt_gueltig 0;
BA_ "GenSigSwitchedByIgnition" SG_ 1601 MO_Anzeige_StSt_gueltig 0;
BA_ "GenSigSendType" SG_ 1601 MO_Code 0;
BA_ "GenSigSwitchedByIgnition" SG_ 1601 MO_Code 0;
BA_ "GenSigSendType" SG_ 1601 MO_DPF_verbaut 0;
BA_ "GenSigFuncType" SG_ 1601 MO_DPF_verbaut 8;
BA_ "GenSigSwitchedByIgnition" SG_ 1601 MO_DPF_verbaut 0;
BA_ "GenSigSendType" SG_ 1601 MO_Faktor_Momente_02 0;
BA_ "GenSigFuncType" SG_ 1601 MO_Faktor_Momente_02 8;
BA_ "GenSigSwitchedByIgnition" SG_ 1601 MO_Faktor_Momente_02 0;
BA_ "GenSigSendType" SG_ 1601 MO_Getriebe_Code 0;
BA_ "GenSigSwitchedByIgnition" SG_ 1601 MO_Getriebe_Code 0;
BA_ "GenSigSendType" SG_ 1601 MO_Hubraum 0;
BA_ "GenSigFuncType" SG_ 1601 MO_Hubraum 8;
BA_ "GenSigSwitchedByIgnition" SG_ 1601 MO_Hubraum 0;
BA_ "GenSigSendType" SG_ 1601 MO_Hybridfahrzeug 0;
BA_ "GenSigFuncType" SG_ 1601 MO_Hybridfahrzeug 8;
BA_ "GenSigSwitchedByIgnition" SG_ 1601 MO_Hybridfahrzeug 0;
BA_ "GenSigSendType" SG_ 1601 MO_Kraftstoffart 0;
BA_ "GenSigFuncType" SG_ 1601 MO_Kraftstoffart 8;
BA_ "GenSigSwitchedByIgnition" SG_ 1601 MO_Kraftstoffart 0;
BA_ "GenSigSendType" SG_ 1601 MO_Leistung 0;
BA_ "GenSigFuncType" SG_ 1601 MO_Leistung 8;
BA_ "GenSigSwitchedByIgnition" SG_ 1601 MO_Leistung 0;
BA_ "GenSigSendType" SG_ 1601 MO_OBD_Typ 0;
BA_ "GenSigFuncType" SG_ 1601 MO_OBD_Typ 8;
BA_ "GenSigSwitchedByIgnition" SG_ 1601 MO_OBD_Typ 0;
BA_ "GenSigSendType" SG_ 1601 MO_StartStopp_Codiert 0;
BA_ "GenSigFuncType" SG_ 1601 MO_StartStopp_Codiert 8;
BA_ "GenSigSwitchedByIgnition" SG_ 1601 MO_StartStopp_Codiert 0;
BA_ "GenSigSendType" SG_ 1601 Motor_Code_01_BZ 0;
BA_ "GenSigFuncType" SG_ 1601 Motor_Code_01_BZ 1;
BA_ "GenSigSwitchedByIgnition" SG_ 1601 Motor_Code_01_BZ 0;
BA_ "GenSigSendType" SG_ 1601 Motor_Code_01_CRC 0;
BA_ "GenSigFuncType" SG_ 1601 Motor_Code_01_CRC 2;
BA_ "GenSigSwitchedByIgnition" SG_ 1601 Motor_Code_01_CRC 0;
BA_ "GenSigSendType" SG_ 1601 TSK_Codierung 0;
BA_ "GenSigStartValue" SG_ 1601 TSK_Codierung 7;
BA_ "GenSigSwitchedByIgnition" SG_ 1601 TSK_Codierung 0;
BA_ "GenSigSendType" SG_ 305 Ladezustand_02 0;
BA_ "GenSigStartValue" SG_ 305 Ladezustand_02 254;
BA_ "GenSigSwitchedByIgnition" SG_ 305 Ladezustand_02 0;
BA_ "Fehlerwert" SG_ 305 Ladezustand_02 255;
BA_ "GenSigSendType" SG_ 305 MO_ePerformance 0;
BA_ "GenSigSwitchedByIgnition" SG_ 305 MO_ePerformance 0;
BA_ "Fehlerwert" SG_ 305 MO_ePerformance 255;
BA_ "GenSigSendType" SG_ 305 MO_ePowermeter 0;
BA_ "GenSigSwitchedByIgnition" SG_ 305 MO_ePowermeter 0;
BA_ "GenSigSendType" SG_ 305 MO_Powermeter 0;
BA_ "GenSigStartValue" SG_ 305 MO_Powermeter 4093;
BA_ "GenSigSwitchedByIgnition" SG_ 305 MO_Powermeter 0;
BA_ "GenSigSendType" SG_ 305 MO_Powermeter_Elm 0;
BA_ "GenSigStartValue" SG_ 305 MO_Powermeter_Elm 128;
BA_ "GenSigSwitchedByIgnition" SG_ 305 MO_Powermeter_Elm 0;
BA_ "GenSigSendType" SG_ 305 MO_Powermeter_Elm_02 0;
BA_ "GenSigStartValue" SG_ 305 MO_Powermeter_Elm_02 4094;
BA_ "GenSigSwitchedByIgnition" SG_ 305 MO_Powermeter_Elm_02 0;
BA_ "GenSigSendType" SG_ 305 MO_Zust_Antrieb 0;
BA_ "GenSigSwitchedByIgnition" SG_ 305 MO_Zust_Antrieb 0;
BA_ "GenSigSendType" SG_ 305 MO_Zust_Betriebsstrategie 0;
BA_ "GenSigSwitchedByIgnition" SG_ 305 MO_Zust_Betriebsstrategie 0;
BA_ "GenSigSendType" SG_ 394 MO_Ablaufstatus 0;
BA_ "GenSigSwitchedByIgnition" SG_ 394 MO_Ablaufstatus 0;
BA_ "Fehlerwert" SG_ 394 MO_Ablaufstatus 15;
BA_ "GenSigSendType" SG_ 394 MO_Ablaufstrg_Betriebszustand 0;
BA_ "GenSigSwitchedByIgnition" SG_ 394 MO_Ablaufstrg_Betriebszustand 0;
BA_ "Fehlerwert" SG_ 394 MO_Ablaufstrg_Betriebszustand 7;
BA_ "GenSigSendType" SG_ 394 MO_Ablaufstrg_Kraftschluss2_Ist 0;
BA_ "GenSigSwitchedByIgnition" SG_ 394 MO_Ablaufstrg_Kraftschluss2_Ist 0;
BA_ "GenSigSendType" SG_ 394 MO_Ablaufstrg_Kraftschluss2_Ziel 0;
BA_ "GenSigSwitchedByIgnition" SG_ 394 MO_Ablaufstrg_Kraftschluss2_Ziel 0;
BA_ "GenSigSendType" SG_ 394 MO_Ablaufstrg_Kraftschluss_Ist 0;
BA_ "GenSigSwitchedByIgnition" SG_ 394 MO_Ablaufstrg_Kraftschluss_Ist 0;
BA_ "GenSigSendType" SG_ 394 MO_Ablaufstrg_Kraftschluss_Ziel 0;
BA_ "GenSigSwitchedByIgnition" SG_ 394 MO_Ablaufstrg_Kraftschluss_Ziel 0;
BA_ "GenSigSendType" SG_ 394 MO_Ablaufstrg_Zustand_K0_Ist 0;
BA_ "GenSigSwitchedByIgnition" SG_ 394 MO_Ablaufstrg_Zustand_K0_Ist 0;
BA_ "GenSigSendType" SG_ 394 MO_Ablaufstrg_Zustand_K0_Ziel 0;
BA_ "GenSigSwitchedByIgnition" SG_ 394 MO_Ablaufstrg_Zustand_K0_Ziel 0;
BA_ "GenSigSendType" SG_ 394 MO_Ablaufstrg_Zustand_VKM_Ist 0;
BA_ "GenSigSwitchedByIgnition" SG_ 394 MO_Ablaufstrg_Zustand_VKM_Ist 0;
BA_ "GenSigSendType" SG_ 394 MO_Ablaufstrg_Zustand_VKM_Ziel 0;
BA_ "GenSigSwitchedByIgnition" SG_ 394 MO_Ablaufstrg_Zustand_VKM_Ziel 0;
BA_ "GenSigSendType" SG_ 394 MO_Abstellposition_02 0;
BA_ "GenSigStartValue" SG_ 394 MO_Abstellposition_02 255;
BA_ "GenSigSwitchedByIgnition" SG_ 394 MO_Abstellposition_02 0;
BA_ "GenSigSendType" SG_ 394 MO_Auth_Aufforderung_WFS 0;
BA_ "GenSigSwitchedByIgnition" SG_ 394 MO_Auth_Aufforderung_WFS 0;
BA_ "GenSigSendType" SG_ 394 MO_HYB_Adaption_aktiv 0;
BA_ "GenSigSendType" SG_ 394 MO_HYB_E_Faktor 0;
BA_ "GenSigSwitchedByIgnition" SG_ 394 MO_HYB_E_Faktor 0;
BA_ "GenSigSendType" SG_ 394 MO_HYB_EMode_Info 0;
BA_ "GenSigSwitchedByIgnition" SG_ 394 MO_HYB_EMode_Info 0;
BA_ "GenSigSendType" SG_ 394 MO_HYB_LowSpeedModus 0;
BA_ "GenSigSwitchedByIgnition" SG_ 394 MO_HYB_LowSpeedModus 0;
BA_ "GenSigSendType" SG_ 394 MO_HYB_Stoppmodus 0;
BA_ "GenSigSendType" SG_ 394 MO_Mom_Freiheit_Sekundaerachse 0;
BA_ "GenSigSwitchedByIgnition" SG_ 394 MO_Mom_Freiheit_Sekundaerachse 0;
BA_ "GenSigSendType" SG_ 394 MO_Nachlaufzeit_Kuehlerluefter 0;
BA_ "GenSigSwitchedByIgnition" SG_ 394 MO_Nachlaufzeit_Kuehlerluefter 0;
BA_ "GenSigSendType" SG_ 394 MO_Start_Art 3;
BA_ "GenSigSwitchedByIgnition" SG_ 394 MO_Start_Art 0;
BA_ "GenSigSendType" SG_ 394 MO_Start_Dynamik 0;
BA_ "GenSigSwitchedByIgnition" SG_ 394 MO_Start_Dynamik 0;
BA_ "GenSigSendType" SG_ 394 MO_Tankklappensteuerung 3;
BA_ "GenSigSwitchedByIgnition" SG_ 394 MO_Tankklappensteuerung 0;
BA_ "GenSigSendType" SG_ 234 Motor_TS_03_BZ 0;
BA_ "GenSigFuncType" SG_ 234 Motor_TS_03_BZ 1;
BA_ "GenSigSwitchedByIgnition" SG_ 234 Motor_TS_03_BZ 0;
BA_ "GenSigSendType" SG_ 234 Motor_TS_03_CRC 0;
BA_ "GenSigFuncType" SG_ 234 Motor_TS_03_CRC 2;
BA_ "GenSigSwitchedByIgnition" SG_ 234 Motor_TS_03_CRC 0;
BA_ "GenSigSendType" SG_ 234 TS_Allrad_Anteil_sek 0;
BA_ "GenSigStartValue" SG_ 234 TS_Allrad_Anteil_sek 510;
BA_ "GenSigSwitchedByIgnition" SG_ 234 TS_Allrad_Anteil_sek 0;
BA_ "Fehlerwert" SG_ 234 TS_Allrad_Anteil_sek 511;
BA_ "GenSigSendType" SG_ 234 TS_MomRad_Ist 0;
BA_ "GenSigStartValue" SG_ 234 TS_MomRad_Ist 8190;
BA_ "GenSigSwitchedByIgnition" SG_ 234 TS_MomRad_Ist 0;
BA_ "GenSigSendType" SG_ 234 TS_MomRad_Ist_sek 0;
BA_ "GenSigStartValue" SG_ 234 TS_MomRad_Ist_sek 8190;
BA_ "GenSigSwitchedByIgnition" SG_ 234 TS_MomRad_Ist_sek 0;
BA_ "Fehlerwert" SG_ 234 TS_MomRad_Ist_sek 8191;
BA_ "GenSigSendType" SG_ 234 TS_MomRad_verfuegb_maxReku_Summe 0;
BA_ "GenSigStartValue" SG_ 234 TS_MomRad_verfuegb_maxReku_Summe 4094;
BA_ "GenSigSwitchedByIgnition" SG_ 234 TS_MomRad_verfuegb_maxReku_Summe 0;
BA_ "Fehlerwert" SG_ 234 TS_MomRad_verfuegb_maxReku_Summe 4095;
BA_ "GenSigSendType" SG_ 234 TS_Status_MomRad_Ist 0;
BA_ "GenSigStartValue" SG_ 234 TS_Status_MomRad_Ist 2;
BA_ "GenSigSwitchedByIgnition" SG_ 234 TS_Status_MomRad_Ist 0;
BA_ "GenSigSendType" SG_ 849 ASW_Warnung_HL 3;
BA_ "GenSigSwitchedByIgnition" SG_ 849 ASW_Warnung_HL 0;
BA_ "GenSigSendType" SG_ 849 MRR_HL_ASW_Modus 3;
BA_ "GenSigStartValue" SG_ 849 MRR_HL_ASW_Modus 4;
BA_ "GenSigSwitchedByIgnition" SG_ 849 MRR_HL_ASW_Modus 0;
BA_ "GenSigSendType" SG_ 849 MRR_HL_ASW_Status 3;
BA_ "GenSigSwitchedByIgnition" SG_ 849 MRR_HL_ASW_Status 0;
BA_ "Fehlerwert" SG_ 849 MRR_HL_ASW_Status 2;
BA_ "GenSigSendType" SG_ 849 MRR_HL_ASW_System_aktiv 0;
BA_ "GenSigSwitchedByIgnition" SG_ 849 MRR_HL_ASW_System_aktiv 0;
BA_ "GenSigSendType" SG_ 849 MRR_HL_Blindness_Status 0;
BA_ "GenSigSendType" SG_ 849 MRR_HL_Kalibriermodus 3;
BA_ "GenSigSendType" SG_ 849 MRR_HL_Performance_Status 3;
BA_ "GenSigSendType" SG_ 849 MRR_HL_QualFaktorAutoKalib 3;
BA_ "GenSigSendType" SG_ 849 MRR_HL_Sensor_Fehler 3;
BA_ "GenSigSwitchedByIgnition" SG_ 849 MRR_HL_Sensor_Fehler 0;
BA_ "GenSigSendType" SG_ 849 MRR_HL_Sensor_Kl_Status 3;
BA_ "GenSigSwitchedByIgnition" SG_ 849 MRR_HL_Sensor_Kl_Status 0;
BA_ "GenSigSendType" SG_ 2463978596 MRR_HL_Info1 3;
BA_ "GenSigSwitchedByIgnition" SG_ 2463978596 MRR_HL_Info1 0;
BA_ "GenSigSendType" SG_ 848 MRR_HR_ASW_System_aktiv 0;
BA_ "GenSigSwitchedByIgnition" SG_ 848 MRR_HR_ASW_System_aktiv 0;
BA_ "GenSigSendType" SG_ 848 MRR_HR_Blindness_Anf 3;
BA_ "GenSigSwitchedByIgnition" SG_ 848 MRR_HR_Blindness_Anf 0;
BA_ "GenSigSendType" SG_ 848 MRR_HR_Blindness_Status 3;
BA_ "GenSigSendType" SG_ 848 MRR_HR_Info_Anf 3;
BA_ "GenSigSwitchedByIgnition" SG_ 848 MRR_HR_Info_Anf 0;
BA_ "GenSigSendType" SG_ 848 MRR_HR_Kalibriermodus 3;
BA_ "GenSigSendType" SG_ 848 MRR_HR_LED_RelHelligkeit 0;
BA_ "GenSigSwitchedByIgnition" SG_ 848 MRR_HR_LED_RelHelligkeit 0;
BA_ "GenSigSendType" SG_ 848 MRR_HR_Performance_Status 3;
BA_ "GenSigSendType" SG_ 848 MRR_HR_QualFaktorAutoKalib 3;
BA_ "GenSigSendType" SG_ 1696 NV_Akt_Status_MMI 3;
BA_ "GenSigStartValue" SG_ 1696 NV_Akt_Status_MMI 3;
BA_ "GenSigSendType" SG_ 1696 NV_aktiv 3;
BA_ "GenSigSendType" SG_ 1696 NV_Akustik_deaktiviert_Icon 3;
BA_ "GenSigSendType" SG_ 1696 NV_Anf_Prefill 3;
BA_ "GenSigSendType" SG_ 1696 NV_AnforderungBildaufschaltung 3;
BA_ "GenSigSendType" SG_ 1696 NV_FAS_Fkt_Status 0;
BA_ "Fehlerwert" SG_ 1696 NV_FAS_Fkt_Status 3;
BA_ "GenSigSendType" SG_ 1696 NV_FGM_deaktiviert_Icon 3;
BA_ "GenSigSendType" SG_ 1696 NV_Gong 3;
BA_ "GenSigSendType" SG_ 1696 NV_HBA_Parameter 3;
BA_ "GenSigSendType" SG_ 1696 NV_Hinweise 3;
BA_ "GenSigSendType" SG_ 1696 NV_LED_Leiste 3;
BA_ "GenSigSendType" SG_ 1696 NV_Markierungslicht_links 3;
BA_ "GenSigSendType" SG_ 1696 NV_Markierungslicht_rechts 3;
BA_ "GenSigSendType" SG_ 1696 NV_Piktogramm_aktiv 3;
BA_ "GenSigSendType" SG_ 1696 NV_PreSense_Modus_System 3;
BA_ "GenSigSendType" SG_ 1696 NV_PreSense_Modus_Warnung 3;
BA_ "GenSigSendType" SG_ 1696 NV_PreSense_Status 3;
BA_ "GenSigSendType" SG_ 1696 NV_Symbol 3;
BA_ "GenSigSendType" SG_ 1696 NV_Symbol_Tierwarnung 3;
BA_ "GenSigSendType" SG_ 1696 NV_Texte 3;
BA_ "GenSigActiveRepetitions" SG_ 2600468496 NM_Gateway_CAB 3;
BA_ "GenSigSendType" SG_ 2600468496 NM_Gateway_CAB 4;
BA_ "GenSigSwitchedByIgnition" SG_ 2600468496 NM_Gateway_CAB 0;
BA_ "GenSigSendType" SG_ 2600468496 NM_Gateway_Car_Wakeup 3;
BA_ "GenSigSwitchedByIgnition" SG_ 2600468496 NM_Gateway_Car_Wakeup 0;
BA_ "GenSigSwitchedByIgnition" SG_ 2600468496 NM_Gateway_CBV_AWB 0;
BA_ "GenSigFuncType" SG_ 2600468496 NM_Gateway_CBV_CRI 8;
BA_ "GenSigSwitchedByIgnition" SG_ 2600468496 NM_Gateway_CBV_CRI 0;
BA_ "GenSigSwitchedByIgnition" SG_ 2600468496 NM_Gateway_NM_aktiv_Buskopplung 0;
BA_ "GenSigSwitchedByIgnition" SG_ 2600468496 NM_Gateway_NM_aktiv_Connect 0;
BA_ "GenSigSwitchedByIgnition" SG_ 2600468496 NM_Gateway_NM_aktiv_CWU 0;
BA_ "GenSigSwitchedByIgnition" SG_ 2600468496 NM_Gateway_NM_aktiv_Diagnose 0;
BA_ "GenSigSwitchedByIgnition" SG_ 2600468496 NM_Gateway_NM_aktiv_EM 0;
BA_ "GenSigSwitchedByIgnition" SG_ 2600468496 NM_Gateway_NM_aktiv_FC 0;
BA_ "GenSigSwitchedByIgnition" SG_ 2600468496 NM_Gateway_NM_aktiv_KL15 0;
BA_ "GenSigSwitchedByIgnition" SG_ 2600468496 NM_Gateway_NM_aktiv_OBDC 0;
BA_ "GenSigSwitchedByIgnition" SG_ 2600468496 NM_Gateway_NM_aktiv_Tmin 0;
BA_ "GenSigSwitchedByIgnition" SG_ 2600468496 NM_Gateway_NM_State 0;
BA_ "GenSigStartValue" SG_ 2600468496 NM_Gateway_SNI 16;
BA_ "GenSigSwitchedByIgnition" SG_ 2600468496 NM_Gateway_SNI 0;
BA_ "GenSigSwitchedByIgnition" SG_ 2600468496 NM_Gateway_UDS_CC 0;
BA_ "GenSigActiveRepetitions" SG_ 2600468519 NM_Nightvision_CAB 3;
BA_ "GenSigSendType" SG_ 2600468519 NM_Nightvision_CAB 4;
BA_ "GenSigSendType" SG_ 2600468519 NM_Nightvision_Car_Wakeup 3;
BA_ "GenSigFuncType" SG_ 2600468519 NM_Nightvision_CBV_CRI 8;
BA_ "GenSigStartValue" SG_ 2600468519 NM_Nightvision_SNI 39;
BA_ "GenSigActiveRepetitions" SG_ 2600468491 NM_RDK_CAB 3;
BA_ "GenSigSendType" SG_ 2600468491 NM_RDK_CAB 4;
BA_ "GenSigSwitchedByIgnition" SG_ 2600468491 NM_RDK_CAB 0;
BA_ "GenSigSendType" SG_ 2600468491 NM_RDK_Car_Wakeup 3;
BA_ "GenSigSwitchedByIgnition" SG_ 2600468491 NM_RDK_Car_Wakeup 0;
BA_ "GenSigSwitchedByIgnition" SG_ 2600468491 NM_RDK_CBV_AWB 0;
BA_ "GenSigFuncType" SG_ 2600468491 NM_RDK_CBV_CRI 8;
BA_ "GenSigSwitchedByIgnition" SG_ 2600468491 NM_RDK_CBV_CRI 0;
BA_ "GenSigSwitchedByIgnition" SG_ 2600468491 NM_RDK_NM_aktiv_Diagnose 0;
BA_ "GenSigSwitchedByIgnition" SG_ 2600468491 NM_RDK_NM_aktiv_KL15 0;
BA_ "GenSigSwitchedByIgnition" SG_ 2600468491 NM_RDK_NM_aktiv_Tmin 0;
BA_ "GenSigSwitchedByIgnition" SG_ 2600468491 NM_RDK_NM_State 0;
BA_ "GenSigStartValue" SG_ 2600468491 NM_RDK_SNI 11;
BA_ "GenSigSwitchedByIgnition" SG_ 2600468491 NM_RDK_SNI 0;
BA_ "GenSigSwitchedByIgnition" SG_ 2600468491 NM_RDK_UDS_CC 0;
BA_ "GenSigActiveRepetitions" SG_ 2600468585 NM_RearView_CAB 3;
BA_ "GenSigSendType" SG_ 2600468585 NM_RearView_CAB 4;
BA_ "GenSigSwitchedByIgnition" SG_ 2600468585 NM_RearView_CAB 0;
BA_ "GenSigSendType" SG_ 2600468585 NM_Rearview_Car_Wakeup 3;
BA_ "GenSigSwitchedByIgnition" SG_ 2600468585 NM_Rearview_Car_Wakeup 0;
BA_ "GenSigSwitchedByIgnition" SG_ 2600468585 NM_RearView_CBV_AWB 0;
BA_ "GenSigFuncType" SG_ 2600468585 NM_RearView_CBV_CRI 8;
BA_ "GenSigSwitchedByIgnition" SG_ 2600468585 NM_RearView_CBV_CRI 0;
BA_ "GenSigSwitchedByIgnition" SG_ 2600468585 NM_Rearview_NM_aktiv_Diagnose 0;
BA_ "GenSigSwitchedByIgnition" SG_ 2600468585 NM_Rearview_NM_aktiv_KL15 0;
BA_ "GenSigSwitchedByIgnition" SG_ 2600468585 NM_Rearview_NM_aktiv_Tmin 0;
BA_ "GenSigSwitchedByIgnition" SG_ 2600468585 NM_Rearview_NM_State 0;
BA_ "GenSigStartValue" SG_ 2600468585 NM_Rearview_SNI 105;
BA_ "GenSigSwitchedByIgnition" SG_ 2600468585 NM_Rearview_SNI 0;
BA_ "GenSigSwitchedByIgnition" SG_ 2600468585 NM_Rearview_UDS_CC 0;
BA_ "GenSigActiveRepetitions" SG_ 2600468522 NM_SCR_CAB 3;
BA_ "GenSigSendType" SG_ 2600468522 NM_SCR_CAB 4;
BA_ "GenSigSwitchedByIgnition" SG_ 2600468522 NM_SCR_CAB 0;
BA_ "GenSigSendType" SG_ 2600468522 NM_SCR_Car_Wakeup 3;
BA_ "GenSigSwitchedByIgnition" SG_ 2600468522 NM_SCR_Car_Wakeup 0;
BA_ "GenSigSwitchedByIgnition" SG_ 2600468522 NM_SCR_CBV_AWB 0;
BA_ "GenSigFuncType" SG_ 2600468522 NM_SCR_CBV_CRI 8;
BA_ "GenSigSwitchedByIgnition" SG_ 2600468522 NM_SCR_CBV_CRI 0;
BA_ "GenSigSwitchedByIgnition" SG_ 2600468522 NM_SCR_NM_aktiv_Diagnose 0;
BA_ "GenSigSwitchedByIgnition" SG_ 2600468522 NM_SCR_NM_aktiv_Evakuierung_Sys 0;
BA_ "GenSigSwitchedByIgnition" SG_ 2600468522 NM_SCR_NM_aktiv_KL15 0;
BA_ "GenSigSwitchedByIgnition" SG_ 2600468522 NM_SCR_NM_aktiv_Tmin 0;
BA_ "GenSigSwitchedByIgnition" SG_ 2600468522 NM_SCR_NM_State 0;
BA_ "GenSigStartValue" SG_ 2600468522 NM_SCR_SNI 42;
BA_ "GenSigSwitchedByIgnition" SG_ 2600468522 NM_SCR_SNI 0;
BA_ "GenSigSwitchedByIgnition" SG_ 2600468522 NM_SCR_UDS_CC 0;
BA_ "GenSigActiveRepetitions" SG_ 2600468586 NM_STH_CAB 3;
BA_ "GenSigSendType" SG_ 2600468586 NM_STH_CAB 4;
BA_ "GenSigSwitchedByIgnition" SG_ 2600468586 NM_STH_CAB 0;
BA_ "GenSigSendType" SG_ 2600468586 NM_STH_Car_Wakeup 3;
BA_ "GenSigSwitchedByIgnition" SG_ 2600468586 NM_STH_Car_Wakeup 0;
BA_ "GenSigSwitchedByIgnition" SG_ 2600468586 NM_STH_CBV_AWB 0;
BA_ "GenSigFuncType" SG_ 2600468586 NM_STH_CBV_CRI 8;
BA_ "GenSigSwitchedByIgnition" SG_ 2600468586 NM_STH_CBV_CRI 0;
BA_ "GenSigSwitchedByIgnition" SG_ 2600468586 NM_STH_NM_aktiv_Diagnose 0;
BA_ "GenSigSwitchedByIgnition" SG_ 2600468586 NM_STH_NM_aktiv_EIN_AUS_Funk 0;
BA_ "GenSigSwitchedByIgnition" SG_ 2600468586 NM_STH_NM_aktiv_EKP_Anf 0;
BA_ "GenSigSwitchedByIgnition" SG_ 2600468586 NM_STH_NM_aktiv_KL15 0;
BA_ "GenSigSwitchedByIgnition" SG_ 2600468586 NM_STH_NM_aktiv_Tmin 0;
BA_ "GenSigSwitchedByIgnition" SG_ 2600468586 NM_STH_NM_aktiv_WaPu_Anf 0;
BA_ "GenSigSwitchedByIgnition" SG_ 2600468586 NM_STH_NM_State 0;
BA_ "GenSigStartValue" SG_ 2600468586 NM_STH_SNI 106;
BA_ "GenSigSwitchedByIgnition" SG_ 2600468586 NM_STH_SNI 0;
BA_ "GenSigSwitchedByIgnition" SG_ 2600468586 NM_STH_UDS_CC 0;
BA_ "GenSigActiveRepetitions" SG_ 2600468558 NM_SWA_CAB 3;
BA_ "GenSigSendType" SG_ 2600468558 NM_SWA_CAB 4;
BA_ "GenSigSwitchedByIgnition" SG_ 2600468558 NM_SWA_CAB 0;
BA_ "GenSigSendType" SG_ 2600468558 NM_SWA_Car_Wakeup 3;
BA_ "GenSigSwitchedByIgnition" SG_ 2600468558 NM_SWA_Car_Wakeup 0;
BA_ "GenSigSwitchedByIgnition" SG_ 2600468558 NM_SWA_CBV_AWB 0;
BA_ "GenSigFuncType" SG_ 2600468558 NM_SWA_CBV_CRI 8;
BA_ "GenSigSwitchedByIgnition" SG_ 2600468558 NM_SWA_CBV_CRI 0;
BA_ "GenSigSwitchedByIgnition" SG_ 2600468558 NM_SWA_NM_aktiv_ASW_aktiv 0;
BA_ "GenSigSwitchedByIgnition" SG_ 2600468558 NM_SWA_NM_aktiv_Diagnose 0;
BA_ "GenSigSwitchedByIgnition" SG_ 2600468558 NM_SWA_NM_aktiv_KL15 0;
BA_ "GenSigSwitchedByIgnition" SG_ 2600468558 NM_SWA_NM_aktiv_Tmin 0;
BA_ "GenSigSwitchedByIgnition" SG_ 2600468558 NM_SWA_NM_State 0;
BA_ "GenSigStartValue" SG_ 2600468558 NM_SWA_SNI 78;
BA_ "GenSigSwitchedByIgnition" SG_ 2600468558 NM_SWA_SNI 0;
BA_ "GenSigSwitchedByIgnition" SG_ 2600468558 NM_SWA_UDS_CC 0;
BA_ "GenSigActiveRepetitions" SG_ 2600468618 NM_SWA_Slave_CAB 3;
BA_ "GenSigSendType" SG_ 2600468618 NM_SWA_Slave_CAB 4;
BA_ "GenSigSwitchedByIgnition" SG_ 2600468618 NM_SWA_Slave_CAB 0;
BA_ "GenSigSendType" SG_ 2600468618 NM_SWA_Slave_Car_Wakeup 3;
BA_ "GenSigSwitchedByIgnition" SG_ 2600468618 NM_SWA_Slave_Car_Wakeup 0;
BA_ "GenSigSwitchedByIgnition" SG_ 2600468618 NM_SWA_Slave_CBV_AWB 0;
BA_ "GenSigFuncType" SG_ 2600468618 NM_SWA_Slave_CBV_CRI 8;
BA_ "GenSigSwitchedByIgnition" SG_ 2600468618 NM_SWA_Slave_CBV_CRI 0;
BA_ "GenSigSwitchedByIgnition" SG_ 2600468618 NM_SWA_Slave_NM_aktiv_ASW_aktiv 0;
BA_ "GenSigSwitchedByIgnition" SG_ 2600468618 NM_SWA_Slave_NM_aktiv_Diagnose 0;
BA_ "GenSigSwitchedByIgnition" SG_ 2600468618 NM_SWA_Slave_NM_aktiv_KL15 0;
BA_ "GenSigSwitchedByIgnition" SG_ 2600468618 NM_SWA_Slave_NM_aktiv_Tmin 0;
BA_ "GenSigSwitchedByIgnition" SG_ 2600468618 NM_SWA_Slave_NM_State 0;
BA_ "GenSigStartValue" SG_ 2600468618 NM_SWA_Slave_SNI 138;
BA_ "GenSigSwitchedByIgnition" SG_ 2600468618 NM_SWA_Slave_SNI 0;
BA_ "GenSigSwitchedByIgnition" SG_ 2600468618 NM_SWA_Slave_UDS_CC 0;
BA_ "GenSigSendType" SG_ 1377 NV_MessZeitpunkt 0;
BA_ "GenSigStartValue" SG_ 1377 NV_MessZeitpunkt 8191;
BA_ "GenSigSendType" SG_ 1377 NV_NichtVerfuegbar 0;
BA_ "GenSigStartValue" SG_ 1377 NV_NichtVerfuegbar 1;
BA_ "GenSigSendType" SG_ 1377 NV_Obj_01_InvTTCBildebStdA 0;
BA_ "GenSigStartValue" SG_ 1377 NV_Obj_01_InvTTCBildebStdA 127;
BA_ "GenSigSendType" SG_ 1377 NV_Obj_01_Klasse 0;
BA_ "GenSigStartValue" SG_ 1377 NV_Obj_01_Klasse 15;
BA_ "GenSigSendType" SG_ 1377 NV_Obj_Links 0;
BA_ "GenSigSendType" SG_ 1377 NV_Obj_Rechts 0;
BA_ "GenSigSendType" SG_ 1377 NV_Obj_Warnung_Fussgaenger 0;
BA_ "GenSigSendType" SG_ 1377 NV_Sensor_PositionX 0;
BA_ "GenSigStartValue" SG_ 1377 NV_Sensor_PositionX 4095;
BA_ "GenSigSendType" SG_ 1377 NV_Sensor_PositionY 0;
BA_ "GenSigStartValue" SG_ 1377 NV_Sensor_PositionY 2047;
BA_ "GenSigSendType" SG_ 1377 NV_Sensor_PositionZ 0;
BA_ "GenSigStartValue" SG_ 1377 NV_Sensor_PositionZ 2047;
BA_ "GenSigSendType" SG_ 597 NV_Obj_01_Gemessen 0;
BA_ "GenSigSendType" SG_ 597 NV_Obj_01_ID 0;
BA_ "GenSigStartValue" SG_ 597 NV_Obj_01_ID 15;
BA_ "GenSigSendType" SG_ 597 NV_Obj_01_InvTTCBildeb 0;
BA_ "GenSigStartValue" SG_ 597 NV_Obj_01_InvTTCBildeb 1023;
BA_ "GenSigSendType" SG_ 597 NV_Obj_01_RadialDistanz 0;
BA_ "GenSigStartValue" SG_ 597 NV_Obj_01_RadialDistanz 4095;
BA_ "GenSigSendType" SG_ 597 NV_Obj_01_RadialDistanzStdA 0;
BA_ "GenSigStartValue" SG_ 597 NV_Obj_01_RadialDistanzStdA 127;
BA_ "GenSigSendType" SG_ 597 NV_Obj_01_WnklBreite 0;
BA_ "GenSigStartValue" SG_ 597 NV_Obj_01_WnklBreite 63;
BA_ "GenSigSendType" SG_ 597 NV_Obj_01_WnklBreiteStdA 0;
BA_ "GenSigStartValue" SG_ 597 NV_Obj_01_WnklBreiteStdA 7;
BA_ "GenSigSendType" SG_ 597 NV_Obj_01_WnklHoehe 0;
BA_ "GenSigStartValue" SG_ 597 NV_Obj_01_WnklHoehe 15;
BA_ "GenSigSendType" SG_ 597 NV_Obj_01_WnklHorMitte 0;
BA_ "GenSigStartValue" SG_ 597 NV_Obj_01_WnklHorMitte 63;
BA_ "GenSigSendType" SG_ 597 NV_Obj_01_WnklHorMitteStdA 0;
BA_ "GenSigStartValue" SG_ 597 NV_Obj_01_WnklHorMitteStdA 7;
BA_ "GenSigSendType" SG_ 597 NV_Obj_01_WnklVertMitte 0;
BA_ "GenSigStartValue" SG_ 597 NV_Obj_01_WnklVertMitte 15;
BA_ "GenSigSendType" SG_ 598 NV_Obj_02_Gemessen 0;
BA_ "GenSigSendType" SG_ 598 NV_Obj_02_ID 0;
BA_ "GenSigStartValue" SG_ 598 NV_Obj_02_ID 15;
BA_ "GenSigSendType" SG_ 598 NV_Obj_02_Klasse 0;
BA_ "GenSigStartValue" SG_ 598 NV_Obj_02_Klasse 15;
BA_ "GenSigSendType" SG_ 598 NV_Obj_02_RadialDistanzRed 0;
BA_ "GenSigStartValue" SG_ 598 NV_Obj_02_RadialDistanzRed 255;
BA_ "GenSigSendType" SG_ 598 NV_Obj_02_RadialDistanzRedStdA 0;
BA_ "GenSigStartValue" SG_ 598 NV_Obj_02_RadialDistanzRedStdA 15;
BA_ "GenSigSendType" SG_ 598 NV_Obj_02_WnklBreite 0;
BA_ "GenSigStartValue" SG_ 598 NV_Obj_02_WnklBreite 63;
BA_ "GenSigSendType" SG_ 598 NV_Obj_02_WnklHoehe 0;
BA_ "GenSigStartValue" SG_ 598 NV_Obj_02_WnklHoehe 15;
BA_ "GenSigSendType" SG_ 598 NV_Obj_02_WnklHorMitte 0;
BA_ "GenSigStartValue" SG_ 598 NV_Obj_02_WnklHorMitte 63;
BA_ "GenSigSendType" SG_ 598 NV_Obj_02_WnklVertMitte 0;
BA_ "GenSigStartValue" SG_ 598 NV_Obj_02_WnklVertMitte 15;
BA_ "GenSigSendType" SG_ 598 NV_Obj_03_RadialDistanzRed 0;
BA_ "GenSigStartValue" SG_ 598 NV_Obj_03_RadialDistanzRed 255;
BA_ "GenSigSendType" SG_ 598 NV_Obj_03_RadialDistanzRedStdA 0;
BA_ "GenSigStartValue" SG_ 598 NV_Obj_03_RadialDistanzRedStdA 15;
BA_ "GenSigSendType" SG_ 598 NV_Obj_03_WnklHoehe 0;
BA_ "GenSigStartValue" SG_ 598 NV_Obj_03_WnklHoehe 15;
BA_ "GenSigSendType" SG_ 598 NV_Obj_03_WnklVertMitte 0;
BA_ "GenSigStartValue" SG_ 598 NV_Obj_03_WnklVertMitte 15;
BA_ "GenSigSendType" SG_ 601 NV_Obj_03_Gemessen 0;
BA_ "GenSigSendType" SG_ 601 NV_Obj_03_ID 0;
BA_ "GenSigStartValue" SG_ 601 NV_Obj_03_ID 15;
BA_ "GenSigSendType" SG_ 601 NV_Obj_03_Klasse 0;
BA_ "GenSigStartValue" SG_ 601 NV_Obj_03_Klasse 15;
BA_ "GenSigSendType" SG_ 601 NV_Obj_03_WnklBreite 0;
BA_ "GenSigStartValue" SG_ 601 NV_Obj_03_WnklBreite 63;
BA_ "GenSigSendType" SG_ 601 NV_Obj_03_WnklHorMitte 0;
BA_ "GenSigStartValue" SG_ 601 NV_Obj_03_WnklHorMitte 63;
BA_ "GenSigSendType" SG_ 601 NV_Obj_04_Gemessen 0;
BA_ "GenSigSendType" SG_ 601 NV_Obj_04_ID 0;
BA_ "GenSigStartValue" SG_ 601 NV_Obj_04_ID 15;
BA_ "GenSigSendType" SG_ 601 NV_Obj_04_Klasse 0;
BA_ "GenSigStartValue" SG_ 601 NV_Obj_04_Klasse 15;
BA_ "GenSigSendType" SG_ 601 NV_Obj_04_RadialDistanzRed 0;
BA_ "GenSigStartValue" SG_ 601 NV_Obj_04_RadialDistanzRed 255;
BA_ "GenSigSendType" SG_ 601 NV_Obj_04_RadialDistanzRedStdA 0;
BA_ "GenSigStartValue" SG_ 601 NV_Obj_04_RadialDistanzRedStdA 15;
BA_ "GenSigSendType" SG_ 601 NV_Obj_04_WnklBreite 0;
BA_ "GenSigStartValue" SG_ 601 NV_Obj_04_WnklBreite 63;
BA_ "GenSigSendType" SG_ 601 NV_Obj_04_WnklHoehe 0;
BA_ "GenSigStartValue" SG_ 601 NV_Obj_04_WnklHoehe 15;
BA_ "GenSigSendType" SG_ 601 NV_Obj_04_WnklHorMitte 0;
BA_ "GenSigStartValue" SG_ 601 NV_Obj_04_WnklHorMitte 63;
BA_ "GenSigSendType" SG_ 601 NV_Obj_04_WnklVertMitte 0;
BA_ "GenSigStartValue" SG_ 601 NV_Obj_04_WnklVertMitte 15;
BA_ "GenSigSendType" SG_ 1635 BEM_02_Abschaltstufen 0;
BA_ "GenSigSwitchedByIgnition" SG_ 1635 BEM_02_Abschaltstufen 0;
BA_ "GenSigSendType" SG_ 1635 BEM_Anf_KL15_schalten 0;
BA_ "GenSigSwitchedByIgnition" SG_ 1635 BEM_Anf_KL15_schalten 0;
BA_ "GenSigSendType" SG_ 1635 BEM_Batteriediagnose 0;
BA_ "GenSigSwitchedByIgnition" SG_ 1635 BEM_Batteriediagnose 0;
BA_ "Fehlerwert" SG_ 1635 BEM_Batteriediagnose 7;
BA_ "GenSigSendType" SG_ 1635 BEM_Generatordiagnose 0;
BA_ "GenSigSwitchedByIgnition" SG_ 1635 BEM_Generatordiagnose 0;
BA_ "GenSigSendType" SG_ 1635 BEM_HL_Regelung_Status 0;
BA_ "GenSigSwitchedByIgnition" SG_ 1635 BEM_HL_Regelung_Status 0;
BA_ "GenSigSendType" SG_ 1635 BEM_Ladezustand 0;
BA_ "GenSigStartValue" SG_ 1635 BEM_Ladezustand 14;
BA_ "GenSigSwitchedByIgnition" SG_ 1635 BEM_Ladezustand 0;
BA_ "Fehlerwert" SG_ 1635 BEM_Ladezustand 15;
BA_ "GenSigSendType" SG_ 1635 BEM_MMI_Vorwarnung 0;
BA_ "GenSigSwitchedByIgnition" SG_ 1635 BEM_MMI_Vorwarnung 0;
BA_ "GenSigSendType" SG_ 1635 BEM_Red_Innengeblaese 0;
BA_ "GenSigSwitchedByIgnition" SG_ 1635 BEM_Red_Innengeblaese 0;
BA_ "GenSigSendType" SG_ 1635 BEM_REK_aktiv 0;
BA_ "GenSigSwitchedByIgnition" SG_ 1635 BEM_REK_aktiv 0;
BA_ "GenSigSendType" SG_ 1635 BEM_STH_Einschaltverbot 0;
BA_ "GenSigSwitchedByIgnition" SG_ 1635 BEM_STH_Einschaltverbot 0;
BA_ "GenSigSendType" SG_ 1635 BEM_STH_Zielzeit 0;
BA_ "GenSigStartValue" SG_ 1635 BEM_STH_Zielzeit 14;
BA_ "GenSigSwitchedByIgnition" SG_ 1635 BEM_STH_Zielzeit 0;
BA_ "Fehlerwert" SG_ 1635 BEM_STH_Zielzeit 15;
BA_ "GenSigSendType" SG_ 1635 BEM_UBDM 0;
BA_ "GenSigSwitchedByIgnition" SG_ 1635 BEM_UBDM 0;
BA_ "Fehlerwert" SG_ 1635 BEM_UBDM 255;
BA_ "GenSigSendType" SG_ 1635 BEM_UGenSoll 0;
BA_ "GenSigSwitchedByIgnition" SG_ 1635 BEM_UGenSoll 0;
BA_ "GenSigSendType" SG_ 1635 MIB_Stromsparmodus 0;
BA_ "GenSigSwitchedByIgnition" SG_ 1635 MIB_Stromsparmodus 0;
BA_ "GenSigSendType" SG_ 1635 NVEM_Anf_SD_schalten 0;
BA_ "GenSigSwitchedByIgnition" SG_ 1635 NVEM_Anf_SD_schalten 0;
BA_ "GenSigSendType" SG_ 1635 NVEM_Batterie_Service 0;
BA_ "GenSigSwitchedByIgnition" SG_ 1635 NVEM_Batterie_Service 0;
BA_ "GenSigSendType" SG_ 1635 NVEM_Freigabe_OnlineUpdate 0;
BA_ "GenSigSwitchedByIgnition" SG_ 1635 NVEM_Freigabe_OnlineUpdate 0;
BA_ "GenSigSendType" SG_ 1635 NVEM_Freigabe_ORU4 0;
BA_ "GenSigSwitchedByIgnition" SG_ 1635 NVEM_Freigabe_ORU4 0;
BA_ "GenSigSendType" SG_ 1635 NVEM_Last_Anf 0;
BA_ "GenSigSwitchedByIgnition" SG_ 1635 NVEM_Last_Anf 0;
BA_ "GenSigSendType" SG_ 913 MO_QBit_Aussen_Temp 0;
BA_ "GenSigStartValue" SG_ 913 MO_QBit_Aussen_Temp 1;
BA_ "GenSigSwitchedByIgnition" SG_ 913 MO_QBit_Aussen_Temp 0;
BA_ "GenSigSendType" SG_ 913 MO_Servicemodus 0;
BA_ "GenSigSwitchedByIgnition" SG_ 913 MO_Servicemodus 0;
BA_ "GenSigSendType" SG_ 913 OBD_Abs_Load_Val 0;
BA_ "GenSigStartValue" SG_ 913 OBD_Abs_Load_Val 65535;
BA_ "GenSigSwitchedByIgnition" SG_ 913 OBD_Abs_Load_Val 0;
BA_ "GenSigSendType" SG_ 913 OBD_Abs_Pedal_Pos 0;
BA_ "GenSigStartValue" SG_ 913 OBD_Abs_Pedal_Pos 255;
BA_ "GenSigSwitchedByIgnition" SG_ 913 OBD_Abs_Pedal_Pos 0;
BA_ "GenSigSendType" SG_ 913 OBD_Abs_Throttle_Pos 0;
BA_ "GenSigStartValue" SG_ 913 OBD_Abs_Throttle_Pos 255;
BA_ "GenSigSwitchedByIgnition" SG_ 913 OBD_Abs_Throttle_Pos 0;
BA_ "GenSigSendType" SG_ 913 OBD_Calc_Load_Val 0;
BA_ "GenSigStartValue" SG_ 913 OBD_Calc_Load_Val 255;
BA_ "GenSigSwitchedByIgnition" SG_ 913 OBD_Calc_Load_Val 0;
BA_ "GenSigSendType" SG_ 913 OBD_ClearMem_Inhibit 0;
BA_ "GenSigSwitchedByIgnition" SG_ 913 OBD_ClearMem_Inhibit 0;
BA_ "GenSigSendType" SG_ 913 OBD_Driving_Cycle 0;
BA_ "GenSigSwitchedByIgnition" SG_ 913 OBD_Driving_Cycle 0;
BA_ "GenSigSendType" SG_ 913 OBD_Eng_Cool_Temp 0;
BA_ "GenSigStartValue" SG_ 913 OBD_Eng_Cool_Temp 255;
BA_ "GenSigSwitchedByIgnition" SG_ 913 OBD_Eng_Cool_Temp 0;
BA_ "GenSigSendType" SG_ 913 OBD_Kaltstart_Denominator 0;
BA_ "GenSigSwitchedByIgnition" SG_ 913 OBD_Kaltstart_Denominator 0;
BA_ "GenSigSendType" SG_ 913 OBD_Minimum_Trip 0;
BA_ "GenSigSwitchedByIgnition" SG_ 913 OBD_Minimum_Trip 0;
BA_ "GenSigSendType" SG_ 913 OBD_Normed_Trip 0;
BA_ "GenSigSwitchedByIgnition" SG_ 913 OBD_Normed_Trip 0;
BA_ "GenSigSendType" SG_ 913 OBD_Sperrung_IUMPR 0;
BA_ "GenSigSwitchedByIgnition" SG_ 913 OBD_Sperrung_IUMPR 0;
BA_ "GenSigSendType" SG_ 913 OBD_Sperrung_Kaltstart_Denom 0;
BA_ "GenSigSwitchedByIgnition" SG_ 913 OBD_Sperrung_Kaltstart_Denom 0;
BA_ "GenSigSendType" SG_ 913 OBD_Warm_Up_Cycle 0;
BA_ "GenSigSwitchedByIgnition" SG_ 913 OBD_Warm_Up_Cycle 0;
BA_ "GenSigSendType" SG_ 2589283478 OBD_Aussen_Temp_gef 0;
BA_ "GenSigStartValue" SG_ 2589283478 OBD_Aussen_Temp_gef 254;
BA_ "GenSigSwitchedByIgnition" SG_ 2589283478 OBD_Aussen_Temp_gef 0;
BA_ "Fehlerwert" SG_ 2589283478 OBD_Aussen_Temp_gef 255;
BA_ "GenSigSendType" SG_ 2549875246 OBDC_AEM_Req_Data 3;
BA_ "GenSigSwitchedByIgnition" SG_ 2549875246 OBDC_AEM_Req_Data 0;
BA_ "GenSigSendType" SG_ 2550006318 OBDC_AEM_Resp_Data 3;
BA_ "GenSigSendType" SG_ 2549875248 OBDC_FLA_Req_Data 3;
BA_ "GenSigSwitchedByIgnition" SG_ 2549875248 OBDC_FLA_Req_Data 0;
BA_ "GenSigSendType" SG_ 2550006320 OBDC_FLA_Resp_Data 3;
BA_ "GenSigSendType" SG_ 2549940736 OBDC_Funktionaler_Req_All_Data 3;
BA_ "GenSigFuncType" SG_ 2549940736 OBDC_Funktionaler_Req_All_Data 9;
BA_ "GenSigSwitchedByIgnition" SG_ 2549940736 OBDC_Funktionaler_Req_All_Data 0;
BA_ "GenSigSendType" SG_ 2549875239 OBDC_Nightvision_Req_Data 3;
BA_ "GenSigSwitchedByIgnition" SG_ 2549875239 OBDC_Nightvision_Req_Data 0;
BA_ "GenSigSendType" SG_ 2550006311 OBDC_Nightvision_Resp_Data 3;
BA_ "GenSigSendType" SG_ 2549875211 OBDC_RDK_Req_Data 3;
BA_ "GenSigSwitchedByIgnition" SG_ 2549875211 OBDC_RDK_Req_Data 0;
BA_ "GenSigSendType" SG_ 2550006283 OBDC_RDK_Resp_Data 3;
BA_ "GenSigSwitchedByIgnition" SG_ 2550006283 OBDC_RDK_Resp_Data 0;
BA_ "GenSigSendType" SG_ 2549875305 OBDC_Rearview_Req_Data 3;
BA_ "GenSigSwitchedByIgnition" SG_ 2549875305 OBDC_Rearview_Req_Data 0;
BA_ "GenSigSendType" SG_ 2550006377 OBDC_Rearview_Resp_Data 3;
BA_ "GenSigSwitchedByIgnition" SG_ 2550006377 OBDC_Rearview_Resp_Data 0;
BA_ "GenSigSendType" SG_ 2549875242 OBDC_SCR_Req_Data 3;
BA_ "GenSigSwitchedByIgnition" SG_ 2549875242 OBDC_SCR_Req_Data 0;
BA_ "GenSigSendType" SG_ 2550006314 OBDC_SCR_Resp_Data 3;
BA_ "GenSigSwitchedByIgnition" SG_ 2550006314 OBDC_SCR_Resp_Data 0;
BA_ "GenSigSendType" SG_ 2549875300 OBDC_Soundaktor2_Req_Data 3;
BA_ "GenSigSwitchedByIgnition" SG_ 2549875300 OBDC_Soundaktor2_Req_Data 0;
BA_ "GenSigSendType" SG_ 2550006372 OBDC_Soundaktor2_Resp_Data 3;
BA_ "GenSigSendType" SG_ 2549875228 OBDC_Soundaktor_Req_Data 3;
BA_ "GenSigSwitchedByIgnition" SG_ 2549875228 OBDC_Soundaktor_Req_Data 0;
BA_ "GenSigSendType" SG_ 2550006300 OBDC_Soundaktor_Resp_Data 3;
BA_ "GenSigSendType" SG_ 2549875306 OBDC_STH_Req_Data 3;
BA_ "GenSigSwitchedByIgnition" SG_ 2549875306 OBDC_STH_Req_Data 0;
BA_ "GenSigSendType" SG_ 2550006378 OBDC_STH_Resp_Data 3;
BA_ "GenSigSwitchedByIgnition" SG_ 2550006378 OBDC_STH_Resp_Data 0;
BA_ "GenSigSendType" SG_ 2549875338 OBDC_SWA_2_Req_Data 3;
BA_ "GenSigSwitchedByIgnition" SG_ 2549875338 OBDC_SWA_2_Req_Data 0;
BA_ "GenSigSendType" SG_ 2550006410 OBDC_SWA_2_Resp_Data 3;
BA_ "GenSigSwitchedByIgnition" SG_ 2550006410 OBDC_SWA_2_Resp_Data 0;
BA_ "GenSigSendType" SG_ 2549875278 OBDC_SWA_Req_Data 3;
BA_ "GenSigSwitchedByIgnition" SG_ 2549875278 OBDC_SWA_Req_Data 0;
BA_ "GenSigSendType" SG_ 2550006350 OBDC_SWA_Resp_Data 3;
BA_ "GenSigSwitchedByIgnition" SG_ 2550006350 OBDC_SWA_Resp_Data 0;
BA_ "GenSigSendType" SG_ 2589283656 ORU_Status 3;
BA_ "GenSigSwitchedByIgnition" SG_ 2589283656 ORU_Status 0;
BA_ "GenSigSendType" SG_ 2589283656 ORU_Warnung 3;
BA_ "GenSigSwitchedByIgnition" SG_ 2589283656 ORU_Warnung 0;
BA_ "GenSigSendType" SG_ 1175 PDC_Tonausgabe_Front 3;
BA_ "GenSigSendType" SG_ 1175 PDC_Tonausgabe_Heck 3;
BA_ "GenSigSendType" SG_ 1175 PH_Abschaltursache 3;
BA_ "GenSigSendType" SG_ 1175 PH_Anf_Audioabsenkung 3;
BA_ "GenSigSendType" SG_ 1175 PH_Anf_Verdeck 3;
BA_ "GenSigSendType" SG_ 1175 PH_defekt 3;
BA_ "GenSigSendType" SG_ 1175 PH_Display_Kundenwunsch 3;
BA_ "GenSigSendType" SG_ 1175 PH_Frequenz_hinten 3;
BA_ "GenSigSendType" SG_ 1175 PH_Frequenz_vorn 3;
BA_ "GenSigSendType" SG_ 1175 PH_gestoert 3;
BA_ "GenSigSendType" SG_ 1175 PH_Lautstaerke_hinten 3;
BA_ "GenSigSendType" SG_ 1175 PH_Lautstaerke_vorn 3;
BA_ "GenSigSendType" SG_ 1175 PH_nachtr_Stopp_Anf 3;
BA_ "GenSigSendType" SG_ 1175 PH_Opt_Anz_H_Hindernis 3;
BA_ "GenSigSendType" SG_ 1175 PH_Opt_Anz_V_Hindernis 3;
BA_ "GenSigSendType" SG_ 1175 PH_Opt_Anzeige_H_ein 3;
BA_ "GenSigSendType" SG_ 1175 PH_Opt_Anzeige_V_ein 3;
BA_ "GenSigSendType" SG_ 1175 PH_StartStopp_Info 3;
BA_ "GenSigSendType" SG_ 1175 PH_Stoermeldung 3;
BA_ "GenSigSendType" SG_ 1175 PH_Systemzustand 3;
BA_ "GenSigSendType" SG_ 1175 PH_Taster 3;
BA_ "Fehlerwert" SG_ 1175 PH_Taster 3;
BA_ "GenSigSendType" SG_ 1175 PH_Tongeber_H_aktiv 3;
BA_ "GenSigSendType" SG_ 1175 PH_Tongeber_H_verfuegbar 3;
BA_ "GenSigSendType" SG_ 1175 PH_Tongeber_mute 3;
BA_ "GenSigSendType" SG_ 1175 PH_Tongeber_V_aktiv 3;
BA_ "GenSigSendType" SG_ 1175 PH_Visualisierung 3;
BA_ "GenSigStartValue" SG_ 1175 PH_Visualisierung 6;
BA_ "Fehlerwert" SG_ 1175 PH_Visualisierung 7;
BA_ "GenSigSendType" SG_ 1175 PLA_Anf_Aufschaltung_RVC 3;
BA_ "GenSigSwitchedByIgnition" SG_ 1353 PL_Luecke_P0_x 0;
BA_ "GenSigSwitchedByIgnition" SG_ 1353 PL_Luecke_P0_y 0;
BA_ "GenSigSwitchedByIgnition" SG_ 1353 PL_Luecke_P2_x 0;
BA_ "GenSigSwitchedByIgnition" SG_ 1353 PL_Luecke_P2_y 0;
BA_ "GenSigSwitchedByIgnition" SG_ 1354 PL_Luecke_P1_x 0;
BA_ "GenSigSwitchedByIgnition" SG_ 1354 PL_Luecke_P1_y 0;
BA_ "GenSigSwitchedByIgnition" SG_ 1354 PL_Luecke_P3_x 0;
BA_ "GenSigSwitchedByIgnition" SG_ 1354 PL_Luecke_P3_y 0;
BA_REL_ "GenSigTimeoutTime" BU_SG_REL_ AEM SG_ 340 MO_Drehzahl_VM 2000;
BA_REL_ "GenSigTimeoutTime" BU_SG_REL_ AEM SG_ 1601 MO_Faktor_Momente_02 5000;
BA_REL_ "GenSigTimeoutTime" BU_SG_REL_ E_Sound SG_ 289 MO_Fahrpedalrohwert_01 500;
BA_REL_ "GenSigTimeoutTime" BU_SG_REL_ E_Sound SG_ 1601 MO_Code 5000;
BA_REL_ "GenSigTimeoutTime" BU_SG_REL_ E_Sound SG_ 234 TS_MomRad_Ist_sek 500;
BA_REL_ "GenSigTimeoutTime" BU_SG_REL_ Gateway SG_ 2600468519 NM_Nightvision_SNI 2000;
BA_REL_ "GenSigTimeoutTime" BU_SG_REL_ Gateway SG_ 2600468519 NM_Nightvision_CBV_AWB 2000;
BA_REL_ "GenSigTimeoutTime" BU_SG_REL_ Gateway SG_ 2600468519 NM_Nightvision_CBV_CRI 2000;
BA_REL_ "GenSigTimeoutTime" BU_SG_REL_ Gateway SG_ 2600468519 NM_Nightvision_Car_Wakeup 2000;
BA_REL_ "GenSigTimeoutTime" BU_SG_REL_ Gateway SG_ 2600468519 NM_Nightvision_CAB 2000;
BA_REL_ "GenSigTimeoutTime" BU_SG_REL_ Gateway SG_ 2600468491 NM_RDK_SNI 2000;
BA_REL_ "GenSigTimeoutTime" BU_SG_REL_ Gateway SG_ 2600468491 NM_RDK_CBV_AWB 2000;
BA_REL_ "GenSigTimeoutTime" BU_SG_REL_ Gateway SG_ 2600468491 NM_RDK_CBV_CRI 2000;
BA_REL_ "GenSigTimeoutTime" BU_SG_REL_ Gateway SG_ 2600468491 NM_RDK_Car_Wakeup 2000;
BA_REL_ "GenSigTimeoutTime" BU_SG_REL_ Gateway SG_ 2600468491 NM_RDK_CAB 2000;
BA_REL_ "GenSigTimeoutTime" BU_SG_REL_ Gateway SG_ 2600468585 NM_Rearview_SNI 2000;
BA_REL_ "GenSigTimeoutTime" BU_SG_REL_ Gateway SG_ 2600468585 NM_RearView_CBV_AWB 2000;
BA_REL_ "GenSigTimeoutTime" BU_SG_REL_ Gateway SG_ 2600468585 NM_RearView_CBV_CRI 2000;
BA_REL_ "GenSigTimeoutTime" BU_SG_REL_ Gateway SG_ 2600468585 NM_Rearview_Car_Wakeup 2000;
BA_REL_ "GenSigTimeoutTime" BU_SG_REL_ Gateway SG_ 2600468585 NM_RearView_CAB 2000;
BA_REL_ "GenSigTimeoutTime" BU_SG_REL_ Gateway SG_ 2600468522 NM_SCR_SNI 2000;
BA_REL_ "GenSigTimeoutTime" BU_SG_REL_ Gateway SG_ 2600468522 NM_SCR_CBV_AWB 2000;
BA_REL_ "GenSigTimeoutTime" BU_SG_REL_ Gateway SG_ 2600468522 NM_SCR_CBV_CRI 2000;
BA_REL_ "GenSigTimeoutTime" BU_SG_REL_ Gateway SG_ 2600468522 NM_SCR_Car_Wakeup 2000;
BA_REL_ "GenSigTimeoutTime" BU_SG_REL_ Gateway SG_ 2600468522 NM_SCR_CAB 2000;
BA_REL_ "GenSigTimeoutTime" BU_SG_REL_ Gateway SG_ 2600468586 NM_STH_SNI 2000;
BA_REL_ "GenSigTimeoutTime" BU_SG_REL_ Gateway SG_ 2600468586 NM_STH_CBV_AWB 2000;
BA_REL_ "GenSigTimeoutTime" BU_SG_REL_ Gateway SG_ 2600468586 NM_STH_CBV_CRI 2000;
BA_REL_ "GenSigTimeoutTime" BU_SG_REL_ Gateway SG_ 2600468586 NM_STH_Car_Wakeup 2000;
BA_REL_ "GenSigTimeoutTime" BU_SG_REL_ Gateway SG_ 2600468586 NM_STH_CAB 2000;
BA_REL_ "GenSigTimeoutTime" BU_SG_REL_ Gateway SG_ 2600468558 NM_SWA_SNI 2000;
BA_REL_ "GenSigTimeoutTime" BU_SG_REL_ Gateway SG_ 2600468558 NM_SWA_CBV_AWB 2000;
BA_REL_ "GenSigTimeoutTime" BU_SG_REL_ Gateway SG_ 2600468558 NM_SWA_CBV_CRI 2000;
BA_REL_ "GenSigTimeoutTime" BU_SG_REL_ Gateway SG_ 2600468558 NM_SWA_Car_Wakeup 2000;
BA_REL_ "GenSigTimeoutTime" BU_SG_REL_ Gateway SG_ 2600468558 NM_SWA_CAB 2000;
BA_REL_ "GenSigTimeoutTime" BU_SG_REL_ Gateway SG_ 2600468618 NM_SWA_Slave_SNI 2000;
BA_REL_ "GenSigTimeoutTime" BU_SG_REL_ Gateway SG_ 2600468618 NM_SWA_Slave_CBV_AWB 2000;
BA_REL_ "GenSigTimeoutTime" BU_SG_REL_ Gateway SG_ 2600468618 NM_SWA_Slave_CBV_CRI 2000;
BA_REL_ "GenSigTimeoutTime" BU_SG_REL_ Gateway SG_ 2600468618 NM_SWA_Slave_Car_Wakeup 2000;
BA_REL_ "GenSigTimeoutTime" BU_SG_REL_ Gateway SG_ 2600468618 NM_SWA_Slave_CAB 2000;
BA_REL_ "GenSigTimeoutTime" BU_SG_REL_ Gateway_PAG SG_ 2600468519 NM_Nightvision_SNI 2000;
BA_REL_ "GenSigTimeoutTime" BU_SG_REL_ Gateway_PAG SG_ 2600468519 NM_Nightvision_CBV_AWB 2000;
BA_REL_ "GenSigTimeoutTime" BU_SG_REL_ Gateway_PAG SG_ 2600468519 NM_Nightvision_CBV_CRI 2000;
BA_REL_ "GenSigTimeoutTime" BU_SG_REL_ Gateway_PAG SG_ 2600468519 NM_Nightvision_CAB 2000;
BA_REL_ "GenSigTimeoutTime" BU_SG_REL_ Gateway_PAG SG_ 2600468491 NM_RDK_SNI 2000;
BA_REL_ "GenSigTimeoutTime" BU_SG_REL_ Gateway_PAG SG_ 2600468491 NM_RDK_CBV_AWB 2000;
BA_REL_ "GenSigTimeoutTime" BU_SG_REL_ Gateway_PAG SG_ 2600468491 NM_RDK_CBV_CRI 2000;
BA_REL_ "GenSigTimeoutTime" BU_SG_REL_ Gateway_PAG SG_ 2600468491 NM_RDK_Car_Wakeup 2000;
BA_REL_ "GenSigTimeoutTime" BU_SG_REL_ Gateway_PAG SG_ 2600468491 NM_RDK_CAB 2000;
BA_REL_ "GenSigTimeoutTime" BU_SG_REL_ Gateway_PAG SG_ 2600468585 NM_Rearview_SNI 2000;
BA_REL_ "GenSigTimeoutTime" BU_SG_REL_ Gateway_PAG SG_ 2600468585 NM_RearView_CBV_AWB 2000;
BA_REL_ "GenSigTimeoutTime" BU_SG_REL_ Gateway_PAG SG_ 2600468585 NM_RearView_CBV_CRI 2000;
BA_REL_ "GenSigTimeoutTime" BU_SG_REL_ Gateway_PAG SG_ 2600468585 NM_RearView_CAB 2000;
BA_REL_ "GenSigTimeoutTime" BU_SG_REL_ Gateway_PAG SG_ 2600468522 NM_SCR_SNI 2000;
BA_REL_ "GenSigTimeoutTime" BU_SG_REL_ Gateway_PAG SG_ 2600468522 NM_SCR_CBV_AWB 2000;
BA_REL_ "GenSigTimeoutTime" BU_SG_REL_ Gateway_PAG SG_ 2600468522 NM_SCR_CBV_CRI 2000;
BA_REL_ "GenSigTimeoutTime" BU_SG_REL_ Gateway_PAG SG_ 2600468522 NM_SCR_Car_Wakeup 2000;
BA_REL_ "GenSigTimeoutTime" BU_SG_REL_ Gateway_PAG SG_ 2600468522 NM_SCR_CAB 2000;
BA_REL_ "GenSigTimeoutTime" BU_SG_REL_ Gateway_PAG SG_ 2600468586 NM_STH_SNI 2000;
BA_REL_ "GenSigTimeoutTime" BU_SG_REL_ Gateway_PAG SG_ 2600468586 NM_STH_CBV_AWB 2000;
BA_REL_ "GenSigTimeoutTime" BU_SG_REL_ Gateway_PAG SG_ 2600468586 NM_STH_CBV_CRI 2000;
BA_REL_ "GenSigTimeoutTime" BU_SG_REL_ Gateway_PAG SG_ 2600468586 NM_STH_Car_Wakeup 2000;
BA_REL_ "GenSigTimeoutTime" BU_SG_REL_ Gateway_PAG SG_ 2600468586 NM_STH_CAB 2000;
BA_REL_ "GenSigTimeoutTime" BU_SG_REL_ Gateway_PAG SG_ 2600468558 NM_SWA_SNI 2000;
BA_REL_ "GenSigTimeoutTime" BU_SG_REL_ Gateway_PAG SG_ 2600468558 NM_SWA_CBV_AWB 2000;
BA_REL_ "GenSigTimeoutTime" BU_SG_REL_ Gateway_PAG SG_ 2600468558 NM_SWA_CBV_CRI 2000;
BA_REL_ "GenSigTimeoutTime" BU_SG_REL_ Gateway_PAG SG_ 2600468558 NM_SWA_Car_Wakeup 2000;
BA_REL_ "GenSigTimeoutTime" BU_SG_REL_ Gateway_PAG SG_ 2600468558 NM_SWA_CAB 2000;
BA_REL_ "GenSigTimeoutTime" BU_SG_REL_ Gateway_PAG SG_ 2600468618 NM_SWA_Slave_SNI 2000;
BA_REL_ "GenSigTimeoutTime" BU_SG_REL_ Gateway_PAG SG_ 2600468618 NM_SWA_Slave_CBV_AWB 2000;
BA_REL_ "GenSigTimeoutTime" BU_SG_REL_ Gateway_PAG SG_ 2600468618 NM_SWA_Slave_CBV_CRI 2000;
BA_REL_ "GenSigTimeoutTime" BU_SG_REL_ Gateway_PAG SG_ 2600468618 NM_SWA_Slave_CAB 2000;
BA_REL_ "GenSigTimeoutTime" BU_SG_REL_ ISE SG_ 289 MO_Fahrpedalrohwert_01 500;
BA_REL_ "GenSigTimeoutTime" BU_SG_REL_ ISE SG_ 1601 MO_Code 5000;
BA_REL_ "GenSigTimeoutTime" BU_SG_REL_ ISE SG_ 234 TS_MomRad_Ist_sek 500;
BA_REL_ "GenSigTimeoutTime" BU_SG_REL_ NightVision SG_ 2600468496 NM_Gateway_SNI 2000;
BA_REL_ "GenSigTimeoutTime" BU_SG_REL_ NightVision SG_ 2600468496 NM_Gateway_CBV_CRI 2000;
BA_REL_ "GenSigTimeoutTime" BU_SG_REL_ NightVision SG_ 2600468496 NM_Gateway_CAB 2000;
BA_REL_ "GenSigTimeoutTime" BU_SG_REL_ NightVision SG_ 2600468491 NM_RDK_SNI 2000;
BA_REL_ "GenSigTimeoutTime" BU_SG_REL_ NightVision SG_ 2600468491 NM_RDK_CBV_CRI 2000;
BA_REL_ "GenSigTimeoutTime" BU_SG_REL_ NightVision SG_ 2600468491 NM_RDK_CAB 2000;
BA_REL_ "GenSigTimeoutTime" BU_SG_REL_ NightVision SG_ 2600468585 NM_Rearview_SNI 2000;
BA_REL_ "GenSigTimeoutTime" BU_SG_REL_ NightVision SG_ 2600468585 NM_RearView_CBV_CRI 2000;
BA_REL_ "GenSigTimeoutTime" BU_SG_REL_ NightVision SG_ 2600468585 NM_RearView_CAB 2000;
BA_REL_ "GenSigTimeoutTime" BU_SG_REL_ NightVision SG_ 2600468522 NM_SCR_SNI 2000;
BA_REL_ "GenSigTimeoutTime" BU_SG_REL_ NightVision SG_ 2600468522 NM_SCR_CBV_CRI 2000;
BA_REL_ "GenSigTimeoutTime" BU_SG_REL_ NightVision SG_ 2600468522 NM_SCR_CAB 2000;
BA_REL_ "GenSigTimeoutTime" BU_SG_REL_ NightVision SG_ 2600468586 NM_STH_SNI 2000;
BA_REL_ "GenSigTimeoutTime" BU_SG_REL_ NightVision SG_ 2600468586 NM_STH_CBV_CRI 2000;
BA_REL_ "GenSigTimeoutTime" BU_SG_REL_ NightVision SG_ 2600468586 NM_STH_CAB 2000;
BA_REL_ "GenSigTimeoutTime" BU_SG_REL_ NightVision SG_ 2600468558 NM_SWA_SNI 2000;
BA_REL_ "GenSigTimeoutTime" BU_SG_REL_ NightVision SG_ 2600468558 NM_SWA_CBV_CRI 2000;
BA_REL_ "GenSigTimeoutTime" BU_SG_REL_ NightVision SG_ 2600468558 NM_SWA_CAB 2000;
BA_REL_ "GenSigTimeoutTime" BU_SG_REL_ NightVision SG_ 2600468618 NM_SWA_Slave_SNI 2000;
BA_REL_ "GenSigTimeoutTime" BU_SG_REL_ NightVision SG_ 2600468618 NM_SWA_Slave_CBV_CRI 2000;
BA_REL_ "GenSigTimeoutTime" BU_SG_REL_ NightVision SG_ 2600468618 NM_SWA_Slave_CAB 2000;
BA_REL_ "GenSigTimeoutTime" BU_SG_REL_ RDK SG_ 2600468496 NM_Gateway_SNI 2000;
BA_REL_ "GenSigTimeoutTime" BU_SG_REL_ RDK SG_ 2600468496 NM_Gateway_CBV_CRI 2000;
BA_REL_ "GenSigTimeoutTime" BU_SG_REL_ RDK SG_ 2600468496 NM_Gateway_CAB 2000;
BA_REL_ "GenSigTimeoutTime" BU_SG_REL_ RDK SG_ 2600468519 NM_Nightvision_SNI 2000;
BA_REL_ "GenSigTimeoutTime" BU_SG_REL_ RDK SG_ 2600468519 NM_Nightvision_CBV_CRI 2000;
BA_REL_ "GenSigTimeoutTime" BU_SG_REL_ RDK SG_ 2600468519 NM_Nightvision_CAB 2000;
BA_REL_ "GenSigTimeoutTime" BU_SG_REL_ RDK SG_ 2600468585 NM_Rearview_SNI 2000;
BA_REL_ "GenSigTimeoutTime" BU_SG_REL_ RDK SG_ 2600468585 NM_RearView_CBV_CRI 2000;
BA_REL_ "GenSigTimeoutTime" BU_SG_REL_ RDK SG_ 2600468585 NM_RearView_CAB 2000;
BA_REL_ "GenSigTimeoutTime" BU_SG_REL_ RDK SG_ 2600468522 NM_SCR_SNI 2000;
BA_REL_ "GenSigTimeoutTime" BU_SG_REL_ RDK SG_ 2600468522 NM_SCR_CBV_CRI 2000;
BA_REL_ "GenSigTimeoutTime" BU_SG_REL_ RDK SG_ 2600468522 NM_SCR_CAB 2000;
BA_REL_ "GenSigTimeoutTime" BU_SG_REL_ RDK SG_ 2600468586 NM_STH_SNI 2000;
BA_REL_ "GenSigTimeoutTime" BU_SG_REL_ RDK SG_ 2600468586 NM_STH_CBV_CRI 2000;
BA_REL_ "GenSigTimeoutTime" BU_SG_REL_ RDK SG_ 2600468586 NM_STH_CAB 2000;
BA_REL_ "GenSigTimeoutTime" BU_SG_REL_ RDK SG_ 2600468558 NM_SWA_SNI 2000;
BA_REL_ "GenSigTimeoutTime" BU_SG_REL_ RDK SG_ 2600468558 NM_SWA_CBV_CRI 2000;
BA_REL_ "GenSigTimeoutTime" BU_SG_REL_ RDK SG_ 2600468558 NM_SWA_CAB 2000;
BA_REL_ "GenSigTimeoutTime" BU_SG_REL_ RDK SG_ 2600468618 NM_SWA_Slave_SNI 2000;
BA_REL_ "GenSigTimeoutTime" BU_SG_REL_ RDK SG_ 2600468618 NM_SWA_Slave_CBV_CRI 2000;
BA_REL_ "GenSigTimeoutTime" BU_SG_REL_ RDK SG_ 2600468618 NM_SWA_Slave_CAB 2000;
BA_REL_ "GenSigTimeoutTime" BU_SG_REL_ SAK SG_ 289 MO_Fahrpedalrohwert_01 500;
BA_REL_ "GenSigTimeoutTime" BU_SG_REL_ SAK SG_ 1601 MO_Code 5000;
BA_REL_ "GenSigTimeoutTime" BU_SG_REL_ SAK SG_ 1601 MO_Leistung 5000;
BA_REL_ "GenSigTimeoutTime" BU_SG_REL_ SAK SG_ 305 MO_Powermeter 500;
BA_REL_ "GenSigTimeoutTime" BU_SG_REL_ SAK2 SG_ 289 MO_Fahrpedalrohwert_01 500;
BA_REL_ "GenSigTimeoutTime" BU_SG_REL_ SAK2 SG_ 1601 MO_Code 5000;
BA_REL_ "GenSigTimeoutTime" BU_SG_REL_ SAK2 SG_ 1601 MO_Leistung 5000;
BA_REL_ "GenSigTimeoutTime" BU_SG_REL_ SAK2 SG_ 305 MO_Powermeter 500;
BA_REL_ "GenSigTimeoutTime" BU_SG_REL_ SCR SG_ 1601 MO_OBD_Typ 5000;
BA_REL_ "GenSigTimeoutTime" BU_SG_REL_ SCR SG_ 394 MO_Start_Art 2000;
BA_REL_ "GenSigTimeoutTime" BU_SG_REL_ SCR SG_ 2600468496 NM_Gateway_SNI 2000;
BA_REL_ "GenSigTimeoutTime" BU_SG_REL_ SCR SG_ 2600468496 NM_Gateway_CBV_CRI 2000;
BA_REL_ "GenSigTimeoutTime" BU_SG_REL_ SCR SG_ 2600468496 NM_Gateway_CAB 2000;
BA_REL_ "GenSigTimeoutTime" BU_SG_REL_ SCR SG_ 2600468519 NM_Nightvision_SNI 2000;
BA_REL_ "GenSigTimeoutTime" BU_SG_REL_ SCR SG_ 2600468519 NM_Nightvision_CBV_CRI 2000;
BA_REL_ "GenSigTimeoutTime" BU_SG_REL_ SCR SG_ 2600468519 NM_Nightvision_CAB 2000;
BA_REL_ "GenSigTimeoutTime" BU_SG_REL_ SCR SG_ 2600468491 NM_RDK_SNI 2000;
BA_REL_ "GenSigTimeoutTime" BU_SG_REL_ SCR SG_ 2600468491 NM_RDK_CBV_CRI 2000;
BA_REL_ "GenSigTimeoutTime" BU_SG_REL_ SCR SG_ 2600468491 NM_RDK_CAB 2000;
BA_REL_ "GenSigTimeoutTime" BU_SG_REL_ SCR SG_ 2600468585 NM_Rearview_SNI 2000;
BA_REL_ "GenSigTimeoutTime" BU_SG_REL_ SCR SG_ 2600468585 NM_RearView_CBV_CRI 2000;
BA_REL_ "GenSigTimeoutTime" BU_SG_REL_ SCR SG_ 2600468585 NM_RearView_CAB 2000;
BA_REL_ "GenSigTimeoutTime" BU_SG_REL_ SCR SG_ 2600468586 NM_STH_SNI 2000;
BA_REL_ "GenSigTimeoutTime" BU_SG_REL_ SCR SG_ 2600468586 NM_STH_CBV_CRI 2000;
BA_REL_ "GenSigTimeoutTime" BU_SG_REL_ SCR SG_ 2600468586 NM_STH_CAB 2000;
BA_REL_ "GenSigTimeoutTime" BU_SG_REL_ SCR SG_ 2600468558 NM_SWA_SNI 2000;
BA_REL_ "GenSigTimeoutTime" BU_SG_REL_ SCR SG_ 2600468558 NM_SWA_CBV_CRI 2000;
BA_REL_ "GenSigTimeoutTime" BU_SG_REL_ SCR SG_ 2600468558 NM_SWA_CAB 2000;
BA_REL_ "GenSigTimeoutTime" BU_SG_REL_ SCR SG_ 2600468618 NM_SWA_Slave_SNI 2000;
BA_REL_ "GenSigTimeoutTime" BU_SG_REL_ SCR SG_ 2600468618 NM_SWA_Slave_CBV_CRI 2000;
BA_REL_ "GenSigTimeoutTime" BU_SG_REL_ SCR SG_ 2600468618 NM_SWA_Slave_CAB 2000;
BA_REL_ "GenSigTimeoutTime" BU_SG_REL_ SCR SG_ 913 OBD_Calc_Load_Val 2000;
BA_REL_ "GenSigTimeoutTime" BU_SG_REL_ SCR SG_ 913 OBD_Eng_Cool_Temp 2000;
BA_REL_ "GenSigTimeoutTime" BU_SG_REL_ SCR SG_ 913 OBD_Abs_Throttle_Pos 2000;
BA_REL_ "GenSigTimeoutTime" BU_SG_REL_ SCR SG_ 913 OBD_Abs_Load_Val 2000;
BA_REL_ "GenSigTimeoutTime" BU_SG_REL_ SCR SG_ 913 OBD_Abs_Pedal_Pos 2000;
BA_REL_ "GenSigTimeoutTime" BU_SG_REL_ SCR SG_ 913 MO_QBit_Aussen_Temp 2000;
BA_REL_ "GenSigTimeoutTime" BU_SG_REL_ SCR SG_ 913 OBD_Sperrung_IUMPR 2000;
BA_REL_ "GenSigTimeoutTime" BU_SG_REL_ SCR SG_ 913 OBD_Kaltstart_Denominator 2000;
BA_REL_ "GenSigTimeoutTime" BU_SG_REL_ SCR SG_ 913 OBD_Minimum_Trip 2000;
BA_REL_ "GenSigTimeoutTime" BU_SG_REL_ SCR SG_ 913 OBD_Driving_Cycle 2000;
BA_REL_ "GenSigTimeoutTime" BU_SG_REL_ SCR SG_ 913 OBD_Warm_Up_Cycle 2000;
BA_REL_ "GenSigTimeoutTime" BU_SG_REL_ SCR SG_ 913 OBD_Normed_Trip 2000;
BA_REL_ "GenSigTimeoutTime" BU_SG_REL_ SCR SG_ 2589283478 OBD_Aussen_Temp_gef 3200;
BA_REL_ "GenSigTimeoutTime" BU_SG_REL_ STH_MLBevo SG_ 1635 BEM_02_Abschaltstufen 1000;
BA_REL_ "GenSigTimeoutTime" BU_SG_REL_ STH_MLBevo SG_ 1635 BEM_STH_Einschaltverbot 1000;
BA_REL_ "GenSigTimeoutTime" BU_SG_REL_ STH_MLBevo SG_ 1635 BEM_HL_Regelung_Status 1000;
BA_REL_ "GenSigTimeoutTime" BU_SG_REL_ STH_MLBevo SG_ 1423 MO_Tankdruck 3200;
BA_REL_ "GenSigTimeoutTime" BU_SG_REL_ STH_MLBevo SG_ 1601 MO_Kraftstoffart 5000;
BA_REL_ "GenSigTimeoutTime" BU_SG_REL_ STH_MLBevo SG_ 2600468496 NM_Gateway_SNI 2000;
BA_REL_ "GenSigTimeoutTime" BU_SG_REL_ STH_MLBevo SG_ 2600468496 NM_Gateway_CBV_CRI 2000;
BA_REL_ "GenSigTimeoutTime" BU_SG_REL_ STH_MLBevo SG_ 2600468496 NM_Gateway_CAB 2000;
BA_REL_ "GenSigTimeoutTime" BU_SG_REL_ STH_MLBevo SG_ 2600468519 NM_Nightvision_SNI 2000;
BA_REL_ "GenSigTimeoutTime" BU_SG_REL_ STH_MLBevo SG_ 2600468519 NM_Nightvision_CBV_CRI 2000;
BA_REL_ "GenSigTimeoutTime" BU_SG_REL_ STH_MLBevo SG_ 2600468519 NM_Nightvision_CAB 2000;
BA_REL_ "GenSigTimeoutTime" BU_SG_REL_ STH_MLBevo SG_ 2600468491 NM_RDK_SNI 2000;
BA_REL_ "GenSigTimeoutTime" BU_SG_REL_ STH_MLBevo SG_ 2600468491 NM_RDK_CBV_CRI 2000;
BA_REL_ "GenSigTimeoutTime" BU_SG_REL_ STH_MLBevo SG_ 2600468491 NM_RDK_CAB 2000;
BA_REL_ "GenSigTimeoutTime" BU_SG_REL_ STH_MLBevo SG_ 2600468585 NM_Rearview_SNI 2000;
BA_REL_ "GenSigTimeoutTime" BU_SG_REL_ STH_MLBevo SG_ 2600468585 NM_RearView_CBV_CRI 2000;
BA_REL_ "GenSigTimeoutTime" BU_SG_REL_ STH_MLBevo SG_ 2600468585 NM_RearView_CAB 2000;
BA_REL_ "GenSigTimeoutTime" BU_SG_REL_ STH_MLBevo SG_ 2600468522 NM_SCR_SNI 2000;
BA_REL_ "GenSigTimeoutTime" BU_SG_REL_ STH_MLBevo SG_ 2600468522 NM_SCR_CBV_CRI 2000;
BA_REL_ "GenSigTimeoutTime" BU_SG_REL_ STH_MLBevo SG_ 2600468522 NM_SCR_CAB 2000;
BA_REL_ "GenSigTimeoutTime" BU_SG_REL_ STH_MLBevo SG_ 2600468558 NM_SWA_SNI 2000;
BA_REL_ "GenSigTimeoutTime" BU_SG_REL_ STH_MLBevo SG_ 2600468558 NM_SWA_CBV_CRI 2000;
BA_REL_ "GenSigTimeoutTime" BU_SG_REL_ STH_MLBevo SG_ 2600468558 NM_SWA_CAB 2000;
BA_REL_ "GenSigTimeoutTime" BU_SG_REL_ STH_MLBevo SG_ 2600468618 NM_SWA_Slave_SNI 2000;
BA_REL_ "GenSigTimeoutTime" BU_SG_REL_ STH_MLBevo SG_ 2600468618 NM_SWA_Slave_CBV_CRI 2000;
BA_REL_ "GenSigTimeoutTime" BU_SG_REL_ STH_MLBevo SG_ 2600468618 NM_SWA_Slave_CAB 2000;
BA_REL_ "GenSigTimeoutTime" BU_SG_REL_ TopView SG_ 2600468496 NM_Gateway_SNI 2000;
BA_REL_ "GenSigTimeoutTime" BU_SG_REL_ TopView SG_ 2600468496 NM_Gateway_CBV_CRI 2000;
BA_REL_ "GenSigTimeoutTime" BU_SG_REL_ TopView SG_ 2600468496 NM_Gateway_CAB 2000;
BA_REL_ "GenSigTimeoutTime" BU_SG_REL_ TopView SG_ 2600468519 NM_Nightvision_SNI 2000;
BA_REL_ "GenSigTimeoutTime" BU_SG_REL_ TopView SG_ 2600468519 NM_Nightvision_CBV_CRI 2000;
BA_REL_ "GenSigTimeoutTime" BU_SG_REL_ TopView SG_ 2600468519 NM_Nightvision_CAB 2000;
BA_REL_ "GenSigTimeoutTime" BU_SG_REL_ TopView SG_ 2600468491 NM_RDK_SNI 2000;
BA_REL_ "GenSigTimeoutTime" BU_SG_REL_ TopView SG_ 2600468491 NM_RDK_CBV_CRI 2000;
BA_REL_ "GenSigTimeoutTime" BU_SG_REL_ TopView SG_ 2600468491 NM_RDK_CAB 2000;
BA_REL_ "GenSigTimeoutTime" BU_SG_REL_ TopView SG_ 2600468522 NM_SCR_SNI 2000;
BA_REL_ "GenSigTimeoutTime" BU_SG_REL_ TopView SG_ 2600468522 NM_SCR_CBV_CRI 2000;
BA_REL_ "GenSigTimeoutTime" BU_SG_REL_ TopView SG_ 2600468522 NM_SCR_CAB 2000;
BA_REL_ "GenSigTimeoutTime" BU_SG_REL_ TopView SG_ 2600468586 NM_STH_SNI 2000;
BA_REL_ "GenSigTimeoutTime" BU_SG_REL_ TopView SG_ 2600468586 NM_STH_CBV_CRI 2000;
BA_REL_ "GenSigTimeoutTime" BU_SG_REL_ TopView SG_ 2600468586 NM_STH_CAB 2000;
BA_REL_ "GenSigTimeoutTime" BU_SG_REL_ TopView SG_ 2600468558 NM_SWA_SNI 2000;
BA_REL_ "GenSigTimeoutTime" BU_SG_REL_ TopView SG_ 2600468558 NM_SWA_CBV_CRI 2000;
BA_REL_ "GenSigTimeoutTime" BU_SG_REL_ TopView SG_ 2600468558 NM_SWA_CAB 2000;
BA_REL_ "GenSigTimeoutTime" BU_SG_REL_ TopView SG_ 2600468618 NM_SWA_Slave_SNI 2000;
BA_REL_ "GenSigTimeoutTime" BU_SG_REL_ TopView SG_ 2600468618 NM_SWA_Slave_CBV_CRI 2000;
BA_REL_ "GenSigTimeoutTime" BU_SG_REL_ TopView SG_ 2600468618 NM_SWA_Slave_CAB 2000;
BA_REL_ "GenSigTimeoutTime" BU_SG_REL_ TopView SG_ 1175 PH_Visualisierung 1000;
BA_REL_ "GenSigTimeoutTime" BU_SG_REL_ TopView SG_ 1175 PLA_Anf_Aufschaltung_RVC 1000;
BA_REL_ "GenSigTimeoutTime" BU_SG_REL_ TopView SG_ 1175 PH_Taster 1000;
BA_REL_ "GenSigTimeoutTime" BU_SG_REL_ TopView SG_ 1175 PH_Systemzustand 1000;
BA_REL_ "GenSigTimeoutTime" BU_SG_REL_ TopView SG_ 1353 PL_Luecke_P0_x 1000;
BA_REL_ "GenSigTimeoutTime" BU_SG_REL_ TopView SG_ 1353 PL_Luecke_P0_y 1000;
BA_REL_ "GenSigTimeoutTime" BU_SG_REL_ TopView SG_ 1353 PL_Luecke_P2_x 1000;
BA_REL_ "GenSigTimeoutTime" BU_SG_REL_ TopView SG_ 1353 PL_Luecke_P2_y 1000;
BA_REL_ "GenSigTimeoutTime" BU_SG_REL_ TopView SG_ 1354 PL_Luecke_P1_x 1000;
BA_REL_ "GenSigTimeoutTime" BU_SG_REL_ TopView SG_ 1354 PL_Luecke_P1_y 1000;
BA_REL_ "GenSigTimeoutTime" BU_SG_REL_ TopView SG_ 1354 PL_Luecke_P3_x 1000;
BA_REL_ "GenSigTimeoutTime" BU_SG_REL_ TopView SG_ 1354 PL_Luecke_P3_y 1000;
VAL_ 289 MO_Fahrpedalrohwert_01 255 "Fehler" ;
VAL_ 289 MO_QBit_Fahrpedalwerte_01 0 "gueltiger_Wert" 1 "Ersatz_Init_oder_Fehlerwert" ;
VAL_ 289 MO_Fahrpedalgradient 255 "Fehler" ;
VAL_ 289 MO_Sig_Fahrpedalgradient 0 "Fahrpedalgradient positiv" 1 "Fahrpedalgradient negativ" ;
VAL_ 289 MO_rel_Saugrohrdruck 0 "Init_Ueberdruck" 63 "Fehler" ;
VAL_ 289 MO_rel_Saugrohrdruck_gem_err 0 "errechnet" 1 "gemessen" ;
VAL_ 289 MO_Moment_im_Leerlauf 0 "kein_Leergas" 1 "Leergas" ;
VAL_ 289 MO_Schubabschaltung 0 "keine_Schubabschaltung" 1 "Schubabschaltung_aktiv" ;
VAL_ 289 MO_StartStopp_StoppVorbereitung 0 "Motorstopp_nicht_in_Vorbereitung" 1 "Motorstopp_in_Vorbereitung" ;
VAL_ 289 MO_Entkopplung_Sollschlupf 125 "Notoeffnen_Anfahrelement" 126 "Init" ;
VAL_ 289 MO_temporaere_Fahrerabwesenheit 0 "nicht_erkannt" 1 "erkannt" ;
VAL_ 289 TSK_a_Soll_gradientenbegrenzt 127 "Init_oder_nicht_aktiv" ;
VAL_ 1423 MO_ITM_Status 0 "stehendes_Wasser" 1 "kein_stehendes_Wasser" 2 "Entnahmegrenze_20_Grad_Celsius" 3 "Entnahmegrenze_30_Grad_Celsius" 4 "Entnahmegrenze_40_Grad_Celsius" 5 "Entnahmegrenze_50_Grad_Celsius" 6 "Entnahmegrenze_60_Grad_Celsius" 7 "keine_Entahme_erlaubt" 14 "Init" 15 "Fehler" ;
VAL_ 1423 MO_Tankdruck 254 "Init" 255 "Fehler" ;
VAL_ 1423 MO_Kuehlmittel_Temp_Rohwert 254 "Init" 255 "Fehler" ;
VAL_ 1423 MO_Oel_Temp_Radsatz 254 "Initialwert" 255 "Fehler" ;
VAL_ 1423 MO_KJS_LLK_Pos_Summe 14 "Init" 15 "Pos_Frontendverschl_ungenau" ;
VAL_ 1423 MO_FSA_Sensorheizung 0 "inaktiv" 1 "aktiv" ;
VAL_ 1423 FSA_Fehlerpfade_Initialisieren 0 "inaktiv" 1 "aktiv" ;
VAL_ 340 MO_IstMoment_VKM 1022 "Init" ;
VAL_ 340 MO_Mom_Begr_Schalt 1022 "Init" ;
VAL_ 340 MO_Mom_Begr_Schalt_Min 1022 "Init" ;
VAL_ 340 MO_Fehlerstatus_Antrieb_FDR 0 "FDR_Normalbetrieb" 1 "FDR_abschalten" 2 "FDR_Regelung_beenden" 3 "FDR_abschalten_temporaer" 4 "FDR_Regelung_temporaer_beenden" ;
VAL_ 340 MO_Primaerachse_Anforderung 0 "Init_Freilaufsteuerung_MSG" 1 "Anforderung_Abkoppeln" 2 "Anforderung_Ankoppeln" ;
VAL_ 1601 MO_Faktor_Momente_02 0 "nicht_belegt" ;
VAL_ 1601 MO_Hybridfahrzeug 0 "kein_Hybridfahrzeug" 1 "Mild_Hybrid" 2 "Full_Hybrid" 3 "PlugIn_Hybrid" ;
VAL_ 1601 MO_Getriebe_Code 0 "Init" 2 "DL501" 3 "DL800" 4 "VL381" 5 "DL382_Front" 6 "DL382_Allrad" 7 "DL702" 8 "AL552_Allrad" 9 "AL552_Front" 10 "AL651" 11 "AL551__AL951__AL1000_8A" 12 "PDK_PAG" 13 "AL551_Hybrid" 15 "Handschalter_konventionell" 16 "AQ250_160" 17 "AQ450" 18 "DQ200" 19 "DQ250" 20 "DQ500" 21 "SQ100" 22 "SQ200" 23 "DQ400E" 24 "DQ381" 25 "AL550" 26 "AQ300" 31 "DL800E" 32 "Single_Gear__ohne_GSG_WH_am_MSG" 33 "EQ550_2P" ;
VAL_ 1601 MO_StartStopp_Codiert 0 "Start_Stopp_nicht_verbaut" 1 "Start_Stopp_verbaut" ;
VAL_ 1601 MO_Anzeige_StSt_gueltig 0 "MO_Text_Motorstart_gueltig" 1 "Signale_MO_Anzeige_StSt_gueltig" ;
VAL_ 1601 MO_Anzahl_Zyl 0 "kein_Zylinder" 1 "1_Zylinder" 2 "2_Zylinder" 3 "3_Zylinder" 4 "4_Zylinder" 5 "5_Zylinder" 6 "6_Zylinder" 7 "7_Zylinder" 8 "8_Zylinder" 9 "9_Zylinder" 10 "10_Zylinder" 11 "11_Zylinder" 12 "12_Zylinder" 13 "15_Zylinder" 14 "16_Zylinder" 15 "18_Zylinder" ;
VAL_ 1601 MO_Kraftstoffart 0 "Diesel" 1 "Benzin_inkl_E25_E85" 2 "CNG" 3 "LPG" 4 "Wasserstoff" 5 "E100_Ethanol" 15 "kein_Verbrennungskraftstoff" ;
VAL_ 1601 MO_Ansaugsystem 0 "Turbo" 1 "Sauger" ;
VAL_ 1601 MO_OBD_Typ 0 "NoOBD_RdW" 1 "EOBD" 2 "US_OBD" 3 "reserviert" ;
VAL_ 1601 MO_DPF_verbaut 0 "kein_DPF_verbaut" 1 "DPF_verbaut" ;
VAL_ 1601 TSK_Codierung 0 "kein_Fahrgeschwindigkeitsregler" 1 "GRA" 2 "GRA_Plus" 3 "Basis_ACC" 4 "ACC_Follow_to_Stop" 5 "ACC_Stop_and_Go" 7 "Codierung_in_Plausibilisierungsphase" ;
VAL_ 305 MO_ePowermeter 0 "Init_keine_Anzeige" 254 "Funktion_deaktiv_Anzeige_ausgegraut" 255 "Fehler_keine_Anzeige" ;
VAL_ 305 MO_ePerformance 0 "Init" 254 "Funktion_deaktiv_Anz_ausgegraut" 255 "Fehler" ;
VAL_ 305 MO_Zust_Antrieb 0 "VKM aktiv" 1 "EM aktiv" 2 "VKM und EM aktiv" 3 "Segeln oder Reku aktiv" ;
VAL_ 305 MO_Zust_Betriebsstrategie 0 "Kein Hybrid" 1 "Depleting" 2 "Soft-Depleting " 3 "Sustaining" 4 "Increasing" 5 "Fremdgesteuert" ;
VAL_ 305 Ladezustand_02 254 "Init" 255 "Fehler" ;
VAL_ 305 MO_Powermeter_Elm_02 0 "nicht_verbaut" 4094 "Init" ;
VAL_ 305 MO_Powermeter 4093 "Off" ;
VAL_ 394 MO_Ablaufstatus 0 "keine_Aktion" 1 "Aktion_regulaerer_Uebergang" 2 "Aktion_regulaerer_Uebergang" 3 "Aktion_regulaerer_Uebergang" 4 "Aktion_regulaerer_Uebergang" 5 "Aktion_regulaerer_Uebergang" 6 "Aktion_regulaerer_Uebergang" 7 "Aktion_regulaerer_Uebergang" 8 "regulaerer_Uebergang_fertig" 9 "Aktion_Abbruch_Uebergang" 10 "Aktion_Abbruch_Uebergang" 11 "Aktion_Abbruch_Uebergang" 12 "Aktion_Abbruch_Uebergang" 13 "Aktion_Abbruch_Uebergang" 14 "Abbruch_Uebergang_fertig" 15 "Fehler" ;
VAL_ 394 MO_Ablaufstrg_Betriebszustand 0 "Init_Nicht_Betriebsbereit" 1 "Betriebsbereitschaft" 2 "Fahrbetrieb" 7 "Fehler" ;
VAL_ 394 MO_Ablaufstrg_Zustand_VKM_Ist 0 "VKM_aus" 1 "VKM_ein" ;
VAL_ 394 MO_Ablaufstrg_Kraftschluss_Ist 0 "kein_Kraftschluss" 1 "Kraftschluss" ;
VAL_ 394 MO_Ablaufstrg_Zustand_K0_Ist 0 "K0_Kupplung_auf" 1 "K0_Kupplung_zu" ;
VAL_ 394 MO_Ablaufstrg_Kraftschluss2_Ist 0 "Sekundärachse abgekoppelt" 1 "Sekundärachse angekoppelt" ;
VAL_ 394 MO_HYB_LowSpeedModus 0 "LowSpeed_mit_LLDZ" 1 "LowSpeed_ohne_LLDZ" ;
VAL_ 394 MO_Ablaufstrg_Zustand_VKM_Ziel 0 "VKM_aus" 1 "VKM_ein" ;
VAL_ 394 MO_Ablaufstrg_Kraftschluss_Ziel 0 "kein_Kraftschluss" 1 "Kraftschluss" ;
VAL_ 394 MO_Ablaufstrg_Zustand_K0_Ziel 0 "K0_Kupplung_auf" 1 "K0_Kupplung_zu" ;
VAL_ 394 MO_Ablaufstrg_Kraftschluss2_Ziel 0 "Anforderung Sekundaerachse abkoppeln" 1 "Anforderung Sekundaerachse ankoppeln" ;
VAL_ 394 MO_HYB_Stoppmodus 0 "Softstopp" 1 "Dynamikstopp" ;
VAL_ 394 MO_Auth_Aufforderung_WFS 0 "Aus" 1 "Ein" ;
VAL_ 394 MO_Start_Dynamik 0 "Kein_Start" 1 "VKM_IDLE_Start" 2 "Softstart_Schubankoppeln_unbefeu" 3 "Komfortstart_befeuert" 4 "Dynamikstart_befeuert" 5 "Sportstart_befeuert" 6 "plausibilisierter_Schleppstart" 7 "Notstart" ;
VAL_ 394 MO_Start_Art 0 "Init" 1 "Zustarteinrichtung" 2 "Schlupfstart" 3 "Schleppstart" ;
VAL_ 394 MO_Abstellposition_02 255 "Abstellposition_ungenau" ;
VAL_ 394 MO_Mom_Freiheit_Sekundaerachse 0 "Sekundaerachse ist nicht momentenfrei" 1 "Sekundaerachse ist momentenfrei" ;
VAL_ 394 MO_Tankklappensteuerung 0 "Init_nicht_verbaut" 1 "Tankklappe_soll_entriegeln" 2 "Tankklappe_soll_verriegeln" 3 "keine_Aktion" ;
VAL_ 394 MO_HYB_E_Faktor 0 "null" 1 "plus_1" 2 "plus_2" 3 "plus_3" 4 "plus_4" 5 "plus_5" 6 "plus_6" 7 "plus_7" 8 "minus_8" 9 "minus_7" 10 "minus_6" 11 "minus_5" 12 "minus_4" 13 "minus_3" 14 "minus_2" 15 "minus_1" ;
VAL_ 394 MO_HYB_EMode_Info 0 "Normal_Mode" 1 "Depleting_Mode" 2 "Charge_Mode" 3 "Sonder_Schaltprogramm" ;
VAL_ 394 MO_HYB_Adaption_aktiv 0 "Keine_Adaption_aktiv" 1 "Adaption_aktiv" ;
VAL_ 234 TS_Status_MomRad_Ist 0 "FuSi_hohe_Genauigkeit" 1 "FuSi_niedrige_Genauigkeit" 2 "QM_fehlerfrei" 3 "QM_mit_Fehlern" ;
VAL_ 234 TS_Allrad_Anteil_sek 510 "Init" 511 "Fehler" ;
VAL_ 234 TS_MomRad_verfuegb_maxReku_Summe 4094 "Init" 4095 "Fehler" ;
VAL_ 234 TS_MomRad_Ist 8190 "Init" ;
VAL_ 234 TS_MomRad_Ist_sek 8190 "Init" 8191 "Fehler" ;
VAL_ 849 MRR_HL_ASW_System_aktiv 0 "nicht_aktiv_Init" 1 "aktiv" ;
VAL_ 849 ASW_Warnung_HL 0 "keine_Warnung" 1 "Warnung" ;
VAL_ 849 MRR_HL_QualFaktorAutoKalib 0 "unbekannt" 1 "genau" 2 "ungenau" 3 "fehlerhaft" ;
VAL_ 849 MRR_HL_ASW_Modus 0 "kein_Fehler_KL15" 1 "kein_Fehler_KL30" 2 "reserve" 3 "Anhaengerbetrieb" 4 "init_nicht_codiert" 5 "keine_Sensorsicht_Blindheit" 6 "zur_Zeit_nicht_verfuegbar_temp_F" 7 "Systemstoerung_dauer_Fehler" ;
VAL_ 849 MRR_HL_Performance_Status 0 "kein_Fehler" 1 "volle_Funktion" 2 "Reichweite_eingeschraenkt" ;
VAL_ 849 MRR_HL_Kalibriermodus 0 "aus" 1 "auto" 2 "kurzer_track" 3 "service" 4 "spc_wiederaufnehmen" 5 "stationaer" 6 "ueberschreiben" 7 "Init" ;
VAL_ 849 MRR_HL_ASW_Status 0 "Passiv" 1 "Aktiv" 2 "Fehler" 3 "Aus" ;
VAL_ 849 MRR_HL_Sensor_Kl_Status 0 "Aus" 1 "Kl_30" 2 "Kl_15" ;
VAL_ 849 MRR_HL_Sensor_Fehler 0 "Fehlerfrei" 1 "Systemstoerung" 2 "Systemfehler" 3 "Systemfehler_und_Systemstoerung" ;
VAL_ 2463978596 MRR_HL_Info1 0 "Init" ;
VAL_ 848 MRR_HR_ASW_System_aktiv 0 "nicht_aktiv_Init" 1 "aktiv" ;
VAL_ 848 MRR_HR_QualFaktorAutoKalib 0 "unbekannt" 1 "genau" 2 "ungenau" 3 "fehlerhaft" ;
VAL_ 848 MRR_HR_Kalibriermodus 0 "aus" 1 "auto" 2 "kurzer_track" 3 "service" 4 "spc_wiederaufnehmen" 5 "stationaer" 6 "ueberschreiben" 7 "Init" ;
VAL_ 848 MRR_HR_Performance_Status 0 "kein_Fehler" 1 "volle_Funktion" 2 "Reichweite_eingeschraenkt" ;
VAL_ 848 MRR_HR_Info_Anf 0 "kein_Request" 1 "SW_Version" 2 "DS_Strukturversion1" 3 "DS_Strukturversion2" 4 "DS_Strukturversion3" 5 "Codierung" 6 "Teilenummer" ;
VAL_ 848 MRR_HR_Blindness_Anf 0 "nicht_angefordert" 1 "angefordert" ;
VAL_ 1696 NV_aktiv 0 "NV nicht aktiv" 1 "NV aktiv" ;
VAL_ 1696 NV_Texte 0 "Init" 1 "Abblendlicht_einschalten" 2 "Fussgaengermarkierung_n_v" 3 "zur_Zeit_nicht_verfuegbar" 4 "Systemfehler" 5 "Fussgaengermarkierung_deakt" 6 "Blindheit_erkannt" 7 "kein_Text" ;
VAL_ 1696 NV_Gong 0 "kein_Gong" 1 "Gong_leise" 2 "Gong_mittel" 3 "Gong_laut" ;
VAL_ 1696 NV_Symbol 0 "kein_Symbol_anzeigen" 1 "Symbol_fuer_erkanntes_Objekt_anzeigen" ;
VAL_ 1696 NV_Hinweise 0 "keine_Anzeige" 1 "Disclaimer" 2 "Fussgaenger_Markierung_nicht_verfuegbar" 3 "Nachtsichtsystem_wird_initialisiert" ;
VAL_ 1696 NV_Piktogramm_aktiv 0 "keine_Anzeigenprioritaet" 1 "Anzeigenprioritaet" ;
VAL_ 1696 NV_Akustik_deaktiviert_Icon 0 "aus" 1 "ein" ;
VAL_ 1696 NV_FGM_deaktiviert_Icon 0 "aus" 1 "ein" ;
VAL_ 1696 NV_Markierungslicht_links 0 "Aus" 1 "Ein" ;
VAL_ 1696 NV_Markierungslicht_rechts 0 "Aus" 1 "Ein" ;
VAL_ 1696 NV_Symbol_Tierwarnung 0 "Aus" 1 "Ein" ;
VAL_ 1696 NV_Anf_Prefill 0 "nicht_angefordert" 1 "angefordert" ;
VAL_ 1696 NV_HBA_Parameter 0 "Defaultparametersatz" 1 "Parametersatz_mit_leicht_erhoehter_Empfindlichkeit" 2 "Parametersatz_mit_erhoehter_Empfindlichkeit" 3 "Parametersatz_mit_hoechster_Empfindlichkeit" ;
VAL_ 1696 NV_LED_Leiste 0 "AUS_keine_Anzeige" 1 "Stufe_1_glimmen" 2 "Stufe_2_leuchten" 3 "Stufe_3_blinken" ;
VAL_ 1696 NV_PreSense_Status 0 "Init" 1 "verfuegbar" 2 "nicht_verfuegbar" ;
VAL_ 1696 NV_PreSense_Modus_System 0 "deaktiviert" 1 "aktiviert" ;
VAL_ 1696 NV_PreSense_Modus_Warnung 0 "Aus" 1 "Setting_2" 2 "Setting_3" 3 "Setting_4" 4 "Setting_5" 5 "Ein" ;
VAL_ 1696 NV_FAS_Fkt_Status 0 "Init" 1 "Funktion_Ist_Ein" 2 "Funktion_Ist_Aus" 3 "Fehler" ;
VAL_ 1696 NV_Akt_Status_MMI 0 "deaktiviert" 1 "aktiviert" 3 "Init" ;
VAL_ 1696 NV_AnforderungBildaufschaltung 0 "KeineBildaufschaltung" 1 "Bildaufschaltung" ;
VAL_ 2600468496 NM_Gateway_SNI 16 "Gateway" ;
VAL_ 2600468496 NM_Gateway_CBV_AWB 0 "Passiver_WakeUp" 1 "Aktiver_WakeUp" ;
VAL_ 2600468496 NM_Gateway_CBV_CRI 0 "Standard_Layout" 1 "TNB_Layout" ;
VAL_ 2600468496 NM_Gateway_NM_State 1 "NM_RM_aus_BSM" 2 "NM_RM_aus_PBSM" 4 "NM_NO_aus_RM" 8 "NM_NO_aus_RS" 16 "NM_RM_aus_RS" 32 "NM_RM_aus_NO" ;
VAL_ 2600468496 NM_Gateway_Car_Wakeup 0 "Inaktiv" 1 "Car_Wakeup" ;
VAL_ 2600468496 NM_Gateway_UDS_CC 0 "Init" 1 "CC_aktiv" ;
VAL_ 2600468496 NM_Gateway_NM_aktiv_KL15 0 "Inaktiv" 1 "KL15_EIN" ;
VAL_ 2600468496 NM_Gateway_NM_aktiv_Diagnose 0 "Init" 1 "Diagnose_aktiv" ;
VAL_ 2600468496 NM_Gateway_NM_aktiv_Tmin 0 "Inaktiv" 1 "Mindestaktivzeit" ;
VAL_ 2600468496 NM_Gateway_NM_aktiv_CWU 0 "kein_CWU_gesetzt" 1 "CWU_gesetzt" ;
VAL_ 2600468496 NM_Gateway_NM_aktiv_FC 0 "kein_FC_gesetzt" 1 "FC_gesetzt" ;
VAL_ 2600468496 NM_Gateway_NM_aktiv_Connect 0 "inaktiv" 1 "Nachlauf_aufgrund_Connect" ;
VAL_ 2600468496 NM_Gateway_NM_aktiv_EM 0 "inaktiv" 1 "Nachlauf_aufgrund_Energiemanagement" ;
VAL_ 2600468496 NM_Gateway_NM_aktiv_OBDC 0 "kein_Nachlauf" 1 "Nachlauf_aufgrund_OBDC" ;
VAL_ 2600468496 NM_Gateway_NM_aktiv_Buskopplung 0 "inaktiv" 1 "Nachlauf_aufgrund_Buskopplung" ;
VAL_ 2600468496 NM_Gateway_CAB 0 "inaktiv" 1 "CAB_01__Tueren" 2 "CAB_02__Anhaenger" 4 "CAB_03__Nightvision" 8 "CAB_04__Sitzverstellung" 16 "CAB_05__Klappen" 32 "CAB_06__Infotainment" 64 "CAB_07__Sub_Infotainment" 128 "CAB_08__Anzeige" 256 "CAB_09__Laden" 512 "CAB_10__Klima" 1024 "CAB_11__FlexRay" 262144 "CAB_19_VLAN_Remote_FC" 524288 "CAB_20_VLAN_Komfort" 1048576 "CAB_21_VLAN_Internet" 2097152 "CAB_22_VLAN_Connect" 4194304 "CAB_23_VLAN_Infotainment" 8388608 "CAB_24_VLAN_FAS" ;
VAL_ 2600468519 NM_Nightvision_SNI 39 "Nightvision" ;
VAL_ 2600468519 NM_Nightvision_CBV_AWB 0 "Passiver_WakeUp" 1 "Aktiver_WakeUp" ;
VAL_ 2600468519 NM_Nightvision_CBV_CRI 0 "Standard_Layout" 1 "TNB_Layout" ;
VAL_ 2600468519 NM_Nightvision_NM_State 1 "NM_RM_aus_BSM" 2 "NM_RM_aus_PBSM" 4 "NM_NO_aus_RM" 8 "NM_NO_aus_RS" 16 "NM_RM_aus_RS" 32 "NM_RM_aus_NO" ;
VAL_ 2600468519 NM_Nightvision_Car_Wakeup 0 "Inaktiv" 1 "Car_Wakeup" ;
VAL_ 2600468519 NM_Nightvision_UDS_CC 0 "Init" 1 "CC_aktiv" ;
VAL_ 2600468519 NM_Nightvision_NM_aktiv_KL15 0 "Inaktiv" 1 "KL15_EIN" ;
VAL_ 2600468519 NM_Nightvision_NM_aktiv_Diagnose 0 "Init" 1 "Diagnose_aktiv" ;
VAL_ 2600468519 NM_Nightvision_NM_aktiv_Tmin 0 "Inaktiv" 1 "Mindestaktivzeit" ;
VAL_ 2600468519 NM_Nightvision_NM_aktiv_ON 0 "NV_nicht_aktiviert" 1 "NV_aktiviert" ;
VAL_ 2600468519 NM_Nightvision_NM_aktiv_defekt 0 "inaktiv" 1 "NV_defekt" ;
VAL_ 2600468519 NM_Nightvision_CAB 0 "inaktiv" 1 "CAB_01__Tueren" 2 "CAB_02__Anhaenger" 4 "CAB_03__Nightvision" 8 "CAB_04__Sitzverstellung" 16 "CAB_05__Klappen" 32 "CAB_06__Infotainment" 64 "CAB_07__Sub_Infotainment" 128 "CAB_08__Anzeige" 256 "CAB_09__Laden" 512 "CAB_10__Klima" 1024 "CAB_11__FlexRay" 262144 "CAB_19_VLAN_Remote_FC" 524288 "CAB_20_VLAN_Komfort" 1048576 "CAB_21_VLAN_Internet" 2097152 "CAB_22_VLAN_Connect" 4194304 "CAB_23_VLAN_Infotainment" 8388608 "CAB_24_VLAN_FAS" ;
VAL_ 2600468491 NM_RDK_SNI 11 "RDK" ;
VAL_ 2600468491 NM_RDK_CBV_AWB 0 "Passiver_WakeUp" 1 "Aktiver_WakeUp" ;
VAL_ 2600468491 NM_RDK_CBV_CRI 0 "Standard_Layout" 1 "TNB_Layout" ;
VAL_ 2600468491 NM_RDK_NM_State 0 "Init" 1 "NM_RM_aus_BSM" 2 "NM_RM_aus_PBSM" 4 "NM_NO_aus_RM" 8 "NM_NO_aus_RS" 16 "NM_RM_aus_RS" 32 "NM_RM_aus_NO" ;
VAL_ 2600468491 NM_RDK_Car_Wakeup 0 "Inaktiv" 1 "Car_Wakeup" ;
VAL_ 2600468491 NM_RDK_UDS_CC 0 "Init" 1 "CC_aktiv" ;
VAL_ 2600468491 NM_RDK_NM_aktiv_KL15 0 "Inaktiv" 1 "KL15_EIN" ;
VAL_ 2600468491 NM_RDK_NM_aktiv_Diagnose 0 "Init" 1 "Diagnose_aktiv" ;
VAL_ 2600468491 NM_RDK_NM_aktiv_Tmin 0 "Inaktiv" 1 "Mindestaktivzeit" ;
VAL_ 2600468491 NM_RDK_CAB 0 "inaktiv" 1 "CAB_01__Tueren" 2 "CAB_02__Anhaenger" 4 "CAB_03__Nightvision" 8 "CAB_04__Sitzverstellung" 16 "CAB_05__Klappen" 32 "CAB_06__Infotainment" 64 "CAB_07__Sub_Infotainment" 128 "CAB_08__Anzeige" 256 "CAB_09__Laden" 512 "CAB_10__Klima" 1024 "CAB_11__FlexRay" 262144 "CAB_19_VLAN_Remote_FC" 524288 "CAB_20_VLAN_Komfort" 1048576 "CAB_21_VLAN_Internet" 2097152 "CAB_22_VLAN_Connect" 4194304 "CAB_23_VLAN_Infotainment" 8388608 "CAB_24_VLAN_FAS" ;
VAL_ 2600468585 NM_Rearview_SNI 105 "Rearview" ;
VAL_ 2600468585 NM_RearView_CBV_AWB 0 "Passiver_WakeUp" 1 "Aktiver_WakeUp" ;
VAL_ 2600468585 NM_RearView_CBV_CRI 0 "Standard_Layout" 1 "TNB_Layout" ;
VAL_ 2600468585 NM_Rearview_NM_State 0 "Init" 1 "NM_RM_aus_BSM" 2 "NM_RM_aus_PBSM" 4 "NM_NO_aus_RM" 8 "NM_NO_aus_RS" 16 "NM_RM_aus_RS" 32 "NM_RM_aus_NO" ;
VAL_ 2600468585 NM_Rearview_Car_Wakeup 0 "Inaktiv" 1 "Car_Wakeup" ;
VAL_ 2600468585 NM_Rearview_UDS_CC 0 "Init" 1 "CC_aktiv" ;
VAL_ 2600468585 NM_Rearview_NM_aktiv_KL15 0 "Inaktiv" 1 "KL15_EIN" ;
VAL_ 2600468585 NM_Rearview_NM_aktiv_Diagnose 0 "Init" 1 "Diagnose_aktiv" ;
VAL_ 2600468585 NM_Rearview_NM_aktiv_Tmin 0 "Inaktiv" 1 "Mindestaktivzeit" ;
VAL_ 2600468585 NM_RearView_CAB 0 "inaktiv" 1 "CAB_01__Tueren" 2 "CAB_02__Anhaenger" 4 "CAB_03__Nightvision" 8 "CAB_04__Sitzverstellung" 16 "CAB_05__Klappen" 32 "CAB_06__Infotainment" 64 "CAB_07__Sub_Infotainment" 128 "CAB_08__Anzeige" 256 "CAB_09__Laden" 512 "CAB_10__Klima" 1024 "CAB_11__FlexRay" 262144 "CAB_19_VLAN_Remote_FC" 524288 "CAB_20_VLAN_Komfort" 1048576 "CAB_21_VLAN_Internet" 2097152 "CAB_22_VLAN_Connect" 4194304 "CAB_23_VLAN_Infotainment" 8388608 "CAB_24_VLAN_FAS" ;
VAL_ 2600468522 NM_SCR_SNI 42 "SCR" ;
VAL_ 2600468522 NM_SCR_CBV_AWB 0 "Passiver_WakeUp" 1 "Aktiver_WakeUp" ;
VAL_ 2600468522 NM_SCR_CBV_CRI 0 "Standard_Layout" 1 "TNB_Layout" ;
VAL_ 2600468522 NM_SCR_NM_State 1 "NM_RM_aus_BSM" 2 "NM_RM_aus_PBSM" 4 "NM_NO_aus_RM" 8 "NM_NO_aus_RS" 16 "NM_RM_aus_RS" 32 "NM_RM_aus_NO" ;
VAL_ 2600468522 NM_SCR_Car_Wakeup 0 "Inaktiv" 1 "Car_Wakeup" ;
VAL_ 2600468522 NM_SCR_UDS_CC 0 "Init" 1 "CC_aktiv" ;
VAL_ 2600468522 NM_SCR_NM_aktiv_KL15 0 "Inaktiv" 1 "KL15_EIN" ;
VAL_ 2600468522 NM_SCR_NM_aktiv_Diagnose 0 "Init" 1 "Diagnose_aktiv" ;
VAL_ 2600468522 NM_SCR_NM_aktiv_Tmin 0 "Inaktiv" 1 "Mindestaktivzeit" ;
VAL_ 2600468522 NM_SCR_NM_aktiv_Evakuierung_Sys 1 "Evakuierung_System_aktiv" ;
VAL_ 2600468522 NM_SCR_CAB 0 "inaktiv" 1 "CAB_01__Tueren" 2 "CAB_02__Anhaenger" 4 "CAB_03__Nightvision" 8 "CAB_04__Sitzverstellung" 16 "CAB_05__Klappen" 32 "CAB_06__Infotainment" 64 "CAB_07__Sub_Infotainment" 128 "CAB_08__Anzeige" 256 "CAB_09__Laden" 512 "CAB_10__Klima" 1024 "CAB_11__FlexRay" 262144 "CAB_19_VLAN_Remote_FC" 524288 "CAB_20_VLAN_Komfort" 1048576 "CAB_21_VLAN_Internet" 2097152 "CAB_22_VLAN_Connect" 4194304 "CAB_23_VLAN_Infotainment" 8388608 "CAB_24_VLAN_FAS" ;
VAL_ 2600468586 NM_STH_SNI 106 "STH" ;
VAL_ 2600468586 NM_STH_CBV_AWB 0 "Passiver_WakeUp" 1 "Aktiver_WakeUp" ;
VAL_ 2600468586 NM_STH_CBV_CRI 0 "Standard_Layout" 1 "TNB_Layout" ;
VAL_ 2600468586 NM_STH_NM_State 0 "Init" 1 "NM_RM_aus_BSM" 2 "NM_RM_aus_PBSM" 4 "NM_NO_aus_RM" 8 "NM_NO_aus_RS" 16 "NM_RM_aus_RS" 32 "NM_RM_aus_NO" ;
VAL_ 2600468586 NM_STH_Car_Wakeup 0 "Inaktiv" 1 "Car_Wakeup" ;
VAL_ 2600468586 NM_STH_UDS_CC 0 "Init" 1 "CC_aktiv" ;
VAL_ 2600468586 NM_STH_NM_aktiv_KL15 0 "Inaktiv" 1 "KL15_EIN" ;
VAL_ 2600468586 NM_STH_NM_aktiv_Diagnose 0 "Init" 1 "Diagnose_aktiv" ;
VAL_ 2600468586 NM_STH_NM_aktiv_Tmin 0 "Inaktiv" 1 "Mindestaktivzeit" ;
VAL_ 2600468586 NM_STH_NM_aktiv_EKP_Anf 1 "EKP_Anf_aktiv" ;
VAL_ 2600468586 NM_STH_NM_aktiv_WaPu_Anf 1 "WaPu_Anf_aktiv" ;
VAL_ 2600468586 NM_STH_NM_aktiv_EIN_AUS_Funk 1 "EIN_AUS_Funk_aktiv" ;
VAL_ 2600468586 NM_STH_CAB 0 "inaktiv" 1 "CAB_01__Tueren" 2 "CAB_02__Anhaenger" 4 "CAB_03__Nightvision" 8 "CAB_04__Sitzverstellung" 16 "CAB_05__Klappen" 32 "CAB_06__Infotainment" 64 "CAB_07__Sub_Infotainment" 128 "CAB_08__Anzeige" 256 "CAB_09__Laden" 512 "CAB_10__Klima" 1024 "CAB_11__FlexRay" 262144 "CAB_19_VLAN_Remote_FC" 524288 "CAB_20_VLAN_Komfort" 1048576 "CAB_21_VLAN_Internet" 2097152 "CAB_22_VLAN_Connect" 4194304 "CAB_23_VLAN_Infotainment" 8388608 "CAB_24_VLAN_FAS" ;
VAL_ 2600468558 NM_SWA_SNI 78 "SWA" ;
VAL_ 2600468558 NM_SWA_CBV_AWB 0 "Passiver_WakeUp" 1 "Aktiver_WakeUp" ;
VAL_ 2600468558 NM_SWA_CBV_CRI 0 "Standard_Layout" 1 "TNB_Layout" ;
VAL_ 2600468558 NM_SWA_NM_State 1 "NM_RM_aus_BSM" 2 "NM_RM_aus_PBSM" 4 "NM_NO_aus_RM" 8 "NM_NO_aus_RS" 16 "NM_RM_aus_RS" 32 "NM_RM_aus_NO" ;
VAL_ 2600468558 NM_SWA_Car_Wakeup 0 "Inaktiv" 1 "Car_Wakeup" ;
VAL_ 2600468558 NM_SWA_UDS_CC 0 "Init" 1 "CC_aktiv" ;
VAL_ 2600468558 NM_SWA_NM_aktiv_KL15 0 "Inaktiv" 1 "KL15_EIN" ;
VAL_ 2600468558 NM_SWA_NM_aktiv_Diagnose 0 "Init" 1 "Diagnose_aktiv" ;
VAL_ 2600468558 NM_SWA_NM_aktiv_Tmin 0 "Inaktiv" 1 "Mindestaktivzeit" ;
VAL_ 2600468558 NM_SWA_NM_aktiv_ASW_aktiv 0 "ASW_nicht_aktiv" 1 "ASW_aktiv" ;
VAL_ 2600468558 NM_SWA_CAB 0 "inaktiv" 1 "CAB_01__Tueren" 2 "CAB_02__Anhaenger" 4 "CAB_03__Nightvision" 8 "CAB_04__Sitzverstellung" 16 "CAB_05__Klappen" 32 "CAB_06__Infotainment" 64 "CAB_07__Sub_Infotainment" 128 "CAB_08__Anzeige" 256 "CAB_09__Laden" 512 "CAB_10__Klima" 1024 "CAB_11__FlexRay" 262144 "CAB_19_VLAN_Remote_FC" 524288 "CAB_20_VLAN_Komfort" 1048576 "CAB_21_VLAN_Internet" 2097152 "CAB_22_VLAN_Connect" 4194304 "CAB_23_VLAN_Infotainment" 8388608 "CAB_24_VLAN_FAS" ;
VAL_ 2600468618 NM_SWA_Slave_SNI 138 "SWA_Slave" ;
VAL_ 2600468618 NM_SWA_Slave_CBV_AWB 0 "Passiver_WakeUp" 1 "Aktiver_WakeUp" ;
VAL_ 2600468618 NM_SWA_Slave_CBV_CRI 0 "Standard_Layout" 1 "TNB_Layout" ;
VAL_ 2600468618 NM_SWA_Slave_NM_State 1 "NM_RM_aus_BSM" 2 "NM_RM_aus_PBSM" 4 "NM_NO_aus_RM" 8 "NM_NO_aus_RS" 16 "NM_RM_aus_RS" 32 "NM_RM_aus_NO" ;
VAL_ 2600468618 NM_SWA_Slave_Car_Wakeup 0 "Inaktiv" 1 "Car_Wakeup" ;
VAL_ 2600468618 NM_SWA_Slave_UDS_CC 0 "Init" 1 "CC_aktiv" ;
VAL_ 2600468618 NM_SWA_Slave_NM_aktiv_KL15 0 "Inaktiv" 1 "KL15_EIN" ;
VAL_ 2600468618 NM_SWA_Slave_NM_aktiv_Diagnose 0 "Init" 1 "Diagnose_aktiv" ;
VAL_ 2600468618 NM_SWA_Slave_NM_aktiv_Tmin 0 "Inaktiv" 1 "Mindestaktivzeit" ;
VAL_ 2600468618 NM_SWA_Slave_NM_aktiv_ASW_aktiv 0 "ASW_nicht_aktiv" 1 "ASW_aktiv" ;
VAL_ 2600468618 NM_SWA_Slave_CAB 0 "inaktiv" 1 "CAB_01__Tueren" 2 "CAB_02__Anhaenger" 4 "CAB_03__Nightvision" 8 "CAB_04__Sitzverstellung" 16 "CAB_05__Klappen" 32 "CAB_06__Infotainment" 64 "CAB_07__Sub_Infotainment" 128 "CAB_08__Anzeige" 256 "CAB_09__Laden" 512 "CAB_10__Klima" 1024 "CAB_11__FlexRay" 262144 "CAB_19_VLAN_Remote_FC" 524288 "CAB_20_VLAN_Komfort" 1048576 "CAB_21_VLAN_Internet" 2097152 "CAB_22_VLAN_Connect" 4194304 "CAB_23_VLAN_Infotainment" 8388608 "CAB_24_VLAN_FAS" ;
VAL_ 1377 NV_Obj_01_InvTTCBildebStdA 127 "Init" ;
VAL_ 1377 NV_Obj_Warnung_Fussgaenger 0 "inaktiv" 1 "aktiv" ;
VAL_ 1377 NV_Obj_Rechts 0 "nicht_erkannt" 1 "erkannt" ;
VAL_ 1377 NV_Obj_Links 0 "nicht_erkannt" 1 "erkannt" ;
VAL_ 1377 NV_Obj_01_Klasse 0 "unbekannt" 1 "ueberfahrbar" 2 "unterfahrbar" 3 "Fussgaenger" 4 "Fussgaengergruppe" 5 "Fahrrad" 6 "Motorrad" 7 "PKW" 8 "Van" 9 "LKW" 10 "Randbebauung" 11 "Tier" 12 "Retroreflektor" 15 "Init" ;
VAL_ 1377 NV_MessZeitpunkt 8191 "Init" ;
VAL_ 1377 NV_Sensor_PositionY 2047 "Init" ;
VAL_ 1377 NV_Sensor_PositionX 4095 "Init" ;
VAL_ 1377 NV_Sensor_PositionZ 2047 "Init" ;
VAL_ 1377 NV_NichtVerfuegbar 0 "NV_verfuegbar" 1 "NV_nicht_verfuegbar" ;
VAL_ 597 NV_Obj_01_RadialDistanz 4095 "Init" ;
VAL_ 597 NV_Obj_01_WnklHoehe 15 "Init" ;
VAL_ 597 NV_Obj_01_InvTTCBildeb 1023 "Init" ;
VAL_ 597 NV_Obj_01_WnklBreite 63 "Init" ;
VAL_ 597 NV_Obj_01_RadialDistanzStdA 127 "Init" ;
VAL_ 597 NV_Obj_01_WnklBreiteStdA 7 "Init" ;
VAL_ 597 NV_Obj_01_WnklHorMitte 63 "Init" ;
VAL_ 597 NV_Obj_01_ID 0 "kein_Objekt_enthalten" 1 "ObjektID_1" 2 "ObjektID_2" 3 "ObjektID_3" 4 "ObjektID_4" 5 "ObjektID_5" 6 "ObjektID_6" 7 "ObjektID_7" 8 "ObjektID_8" 9 "ObjektID_9" 10 "ObjektID_10" 11 "ObjektID_11" 12 "ObjektID_12" 13 "ObjektID_13" 14 "ObjektID_14" 15 "Init" ;
VAL_ 597 NV_Obj_01_Gemessen 0 "Objekt_praediziert" 1 "Objekt_gemessen" 2 "Objekt_per_Feature_Tracking" 3 "Naheinscherer_oder_Ueberholer" ;
VAL_ 597 NV_Obj_01_WnklHorMitteStdA 7 "Init" ;
VAL_ 597 NV_Obj_01_WnklVertMitte 15 "Init" ;
VAL_ 598 NV_Obj_02_RadialDistanzRed 255 "Init" ;
VAL_ 598 NV_Obj_02_RadialDistanzRedStdA 15 "Init" ;
VAL_ 598 NV_Obj_02_WnklHoehe 15 "Init" ;
VAL_ 598 NV_Obj_02_WnklBreite 63 "Init" ;
VAL_ 598 NV_Obj_02_WnklHorMitte 63 "Init" ;
VAL_ 598 NV_Obj_02_Klasse 0 "unbekannt" 1 "ueberfahrbar" 2 "unterfahrbar" 3 "Fussgaenger" 4 "Fussgaengergruppe" 5 "Fahrrad" 6 "Motorrad" 7 "PKW" 8 "Van" 9 "LKW" 10 "Randbebauung" 11 "Tier" 12 "Retroreflektor" 15 "Init" ;
VAL_ 598 NV_Obj_02_WnklVertMitte 15 "Init" ;
VAL_ 598 NV_Obj_02_ID 0 "kein_Objekt_enthalten" 1 "ObjektID_1" 2 "ObjektID_2" 3 "ObjektID_3" 4 "ObjektID_4" 5 "ObjektID_5" 6 "ObjektID_6" 7 "ObjektID_7" 8 "ObjektID_8" 9 "ObjektID_9" 10 "ObjektID_10" 11 "ObjektID_11" 12 "ObjektID_12" 13 "ObjektID_13" 14 "ObjektID_14" 15 "Init" ;
VAL_ 598 NV_Obj_02_Gemessen 0 "Objekt_praediziert" 1 "Objekt_gemessen" 2 "Objekt_per_Feature_Tracking" 3 "Naheinscherer_oder_Ueberholer" ;
VAL_ 598 NV_Obj_03_WnklVertMitte 15 "Init" ;
VAL_ 598 NV_Obj_03_WnklHoehe 15 "Init" ;
VAL_ 598 NV_Obj_03_RadialDistanzRedStdA 15 "Init" ;
VAL_ 598 NV_Obj_03_RadialDistanzRed 255 "Init" ;
VAL_ 601 NV_Obj_03_WnklHorMitte 63 "Init" ;
VAL_ 601 NV_Obj_03_Gemessen 0 "Objekt_praediziert" 1 "Objekt_gemessen" 2 "Objekt_per_Feature_Tracking" 3 "Naheinscherer_oder_Ueberholer" ;
VAL_ 601 NV_Obj_03_ID 0 "kein_Objekt_enthalten" 1 "ObjektID_1" 2 "ObjektID_2" 3 "ObjektID_3" 4 "ObjektID_4" 5 "ObjektID_5" 6 "ObjektID_6" 7 "ObjektID_7" 8 "ObjektID_8" 9 "ObjektID_9" 10 "ObjektID_10" 11 "ObjektID_11" 12 "ObjektID_12" 13 "ObjektID_13" 14 "ObjektID_14" 15 "Init" ;
VAL_ 601 NV_Obj_03_Klasse 0 "unbekannt" 1 "ueberfahrbar" 2 "unterfahrbar" 3 "Fussgaenger" 4 "Fussgaengergruppe" 5 "Fahrrad" 6 "Motorrad" 7 "PKW" 8 "Van" 9 "LKW" 10 "Randbebauung" 11 "Tier" 12 "Retroreflektor" 15 "Init" ;
VAL_ 601 NV_Obj_03_WnklBreite 63 "Init" ;
VAL_ 601 NV_Obj_04_Gemessen 0 "Objekt_praediziert" 1 "Objekt_gemessen" 2 "Objekt_per_Feature_Tracking" 3 "Naheinscherer_oder_Ueberholer" ;
VAL_ 601 NV_Obj_04_ID 0 "kein_Objekt_enthalten" 1 "ObjektID_1" 2 "ObjektID_2" 3 "ObjektID_3" 4 "ObjektID_4" 5 "ObjektID_5" 6 "ObjektID_6" 7 "ObjektID_7" 8 "ObjektID_8" 9 "ObjektID_9" 10 "ObjektID_10" 11 "ObjektID_11" 12 "ObjektID_12" 13 "ObjektID_13" 14 "ObjektID_14" 15 "Init" ;
VAL_ 601 NV_Obj_04_Klasse 0 "unbekannt" 1 "ueberfahrbar" 2 "unterfahrbar" 3 "Fussgaenger" 4 "Fussgaengergruppe" 5 "Fahrrad" 6 "Motorrad" 7 "PKW" 8 "Van" 9 "LKW" 10 "Randbebauung" 11 "Tier" 12 "Retroreflektor" 15 "Init" ;
VAL_ 601 NV_Obj_04_RadialDistanzRed 255 "Init" ;
VAL_ 601 NV_Obj_04_WnklHoehe 15 "Init" ;
VAL_ 601 NV_Obj_04_WnklVertMitte 15 "Init" ;
VAL_ 601 NV_Obj_04_WnklBreite 63 "Init" ;
VAL_ 601 NV_Obj_04_RadialDistanzRedStdA 15 "Init" ;
VAL_ 601 NV_Obj_04_WnklHorMitte 63 "Init" ;
VAL_ 1635 BEM_02_Abschaltstufen 0 "Stufe 0 (keine Einschraenkungen)" 1 "Stufe 1" 2 "Stufe 2" 3 "Stufe 3" 4 "Transportmodus" 7 "Ruhestrommessmodus" ;
VAL_ 1635 BEM_STH_Zielzeit 14 "Init" 15 "Fehler" ;
VAL_ 1635 BEM_MMI_Vorwarnung 0 "keine Anzeige" 1 "Anzeige MMI-Vorwarnung" ;
VAL_ 1635 NVEM_Anf_SD_schalten 0 "Anf_SD_Nachlauf_nicht_aktiv" 1 "Anf_SD_Nachlauf_aktiv" ;
VAL_ 1635 BEM_Generatordiagnose 0 "keine Anzeige" 1 "Ladekontrollanzeige ein (Vorhalt)" 2 "rotes Batteriesymbol und Text (Generator defekt)" 3 "Hybrid_DCDC_Wandler_defekt" ;
VAL_ 1635 BEM_Red_Innengeblaese 0 "keine Reduzierung" 1 "Reduzierung Stufe 1" 2 "Reduzierung Stufe 2" 3 "Reduzierung Stufe 2 und Abschaltung Kompressor" ;
VAL_ 1635 BEM_STH_Einschaltverbot 0 "volle Verfuegbarkeit Standheizung/-lueftung" 1 "Standheizung/-lueftung nicht aktivierbar" ;
VAL_ 1635 BEM_HL_Regelung_Status 0 "HL_Regelung_inaktiv_(vor_und_waehrend_Motorstart)" 1 "HL_Regelung_Stufe_1" 2 "HL_Regelung_Stufe_2" 3 "HL_Regelung_Stufe_3" 4 "Verbrauchernotabschaltung_(VNA)" 5 "HL_Regelung_Stufe_5" 7 "Default" ;
VAL_ 1635 BEM_Ladezustand 14 "Init" 15 "Fehler" ;
VAL_ 1635 BEM_Batteriediagnose 0 "keine_Anzeige" 1 "nicht_belegt" 2 "Anzeige_aberkannte_Batterie" 3 "Anzeige_schwache_Batterie" 4 "Anzeige_Batterie_OK" 5 "Anzeige_Batterie_Laden" 6 "Anzeige_Batterie_Pruefen" 7 "Fehler" ;
VAL_ 1635 MIB_Stromsparmodus 0 "inaktiv" 1 "aktiv" ;
VAL_ 1635 BEM_REK_aktiv 0 "keine_Rekuperationsfreigabe" 1 "Rekuperationsfreigabe" ;
VAL_ 1635 NVEM_Last_Anf 0 "keine Anforderung" 1 "Verbraucher_Anforderung_Stufe_1" 2 "Verbraucher_Anforderung_Stufe_2" 3 "Verbraucher_Anforderung_Stufe_3" ;
VAL_ 1635 BEM_UBDM 0 "Init" 255 "Fehler" ;
VAL_ 1635 BEM_Anf_KL15_schalten 0 "Keine_Einschraenkung_Kl15" 1 "Empfehlung_auto_Abschaltung_Kl15" 2 "Veto_auto_Abschaltung_Kl15" 3 "Veto_auto_Abschaltung_Fahrtbetrieb" ;
VAL_ 1635 NVEM_Batterie_Service 0 "kein_Service" 1 "Service_Information1" 2 "Service_Information2" 3 "Service_Information3" ;
VAL_ 1635 NVEM_Freigabe_OnlineUpdate 0 "keine_Freigabe" 1 "Freigabe" ;
VAL_ 1635 NVEM_Freigabe_ORU4 0 "Init" 1 "keine_Freigabe" 2 "Freigabe_erteilt" 3 "Veto_Freigabe" ;
VAL_ 913 MO_Servicemodus 0 "nicht_aktiv" 1 "Service_Mode_1" 2 "Service_Mode_2" 3 "Service_Mode_3" 4 "Service_Mode_4" 5 "Service_Mode_5" 6 "Service_Mode_6" 7 "Service_Mode_7" 8 "Service_Mode_8" 9 "Service_Mode_9" 10 "Service_Mode_10" 11 "Service_Mode_11" 12 "Service_Mode_12" 13 "Service_Mode_13" 14 "Service_Mode_14" 15 "Service_Mode_15" ;
VAL_ 913 OBD_ClearMem_Inhibit 0 "FSP_Loeschen_zulaessig" 1 "FSP_Loeschen_nicht_zulaessig" ;
VAL_ 913 OBD_Sperrung_Kaltstart_Denom 0 "EVAP_Berechnung_freigegeben" 1 "EVAP_Berechnung_gesperrt" ;
VAL_ 913 MO_QBit_Aussen_Temp 0 "gueltiger_Wert" 1 "Ersatz_Init_oder_Fehlerwert" ;
VAL_ 913 OBD_Sperrung_IUMPR 0 "IUMPR_Berechnung_freigegeben" 1 "IUMPR_Berechnung_gesperrt" ;
VAL_ 913 OBD_Kaltstart_Denominator 0 "Denominator_nicht_hochzaehlen" 1 "Bedingungen_zum_Inkr_des_Kaltstart_Denom_erf" ;
VAL_ 913 OBD_Minimum_Trip 0 "kein_Min_Normed_Trip" 1 "Min_Normed_Trip" ;
VAL_ 913 OBD_Driving_Cycle 0 "kein Driving Cycle erkannt" 1 "DC erkannt" ;
VAL_ 913 OBD_Warm_Up_Cycle 0 "kein Warm Up Cycle erkannt" 1 "Warm Up Cycle erkannt" ;
VAL_ 913 OBD_Normed_Trip 0 "kein Normed Trip" 1 "Normed Trip erfüllt" ;
VAL_ 2589283478 OBD_Aussen_Temp_gef 254 "Init" 255 "Fehler" ;
VAL_ 2589283656 ORU_Warnung 0 "keine_Anzeige" 1 "Update_unvollstaendig_Prio1" 2 "reserviert" 3 "reserviert" ;
VAL_ 2589283656 ORU_Status 0 "IDLE" 1 "PENDING" 2 "PREPARATION" 3 "PREPARATION_HV" 4 "RUNNING" 5 "RUNNING_HV" 6 "PENDING_NOTREADY" ;
VAL_ 1175 PH_Visualisierung 0 "Aus" 1 "Angefragt" 2 "InAnzeige" 3 "Abgefordert" 6 "Init" 7 "Fehler" ;
VAL_ 1175 PDC_Tonausgabe_Front 0 "kein_Ton" 1 "Intervallton_1" 2 "Intervallton_2" 3 "Intervallton_3" 4 "Intervallton_4" 5 "Intervallton_5" 6 "Dauerton" 7 "Fehlerton" 8 "RCTATon" ;
VAL_ 1175 PDC_Tonausgabe_Heck 0 "kein_Ton" 1 "Intervallton_1" 2 "Intervallton_2" 3 "Intervallton_3" 4 "Intervallton_4" 5 "Intervallton_5" 6 "Dauerton" 7 "Fehlerton" 8 "Erstwarnton_hinten" 9 "RCTATon" ;
VAL_ 1175 PH_nachtr_Stopp_Anf 0 "nicht_angefordert" 1 "angefordert" ;
VAL_ 1175 PH_Abschaltursache 0 "keine, bzw. System aktiv" 1 "Abschaltung durch Herausnahme R-Gang" 2 "Abschaltung ueber Geschwindigkeit" 3 "Abschaltung ueber PDC-Taster" 4 "Abschaltung wegen PLA" 5 "Abschaltung durch KL 15 Bit = 0" 6 "tbd." 7 "Fehler-/gestört Zustand, System noch aktiv" ;
VAL_ 1175 PH_Opt_Anzeige_V_ein 0 "optische Anzeige vorne nicht aktiv" 1 "optische Anzeige vorne aktiviert" ;
VAL_ 1175 PH_Opt_Anzeige_H_ein 0 "Optische Anzeige aus" 1 "optische Anzeige hinten aktiviert" ;
VAL_ 1175 PH_Opt_Anz_V_Hindernis 0 "optische Anzeige vorne meldet kein Hindernis" 1 "optische Anzeige vorne meldet Hindernis im Warnbereich" ;
VAL_ 1175 PH_Opt_Anz_H_Hindernis 0 "optische Anzeige hinten meldet kein Hindernis" 1 "optische Anzeige hinten meldet Hindernis im Warnbereich" ;
VAL_ 1175 PH_Tongeber_V_aktiv 0 "Tongeber vorne nicht aktiv" 1 "Tongeber vorne  aktiv" ;
VAL_ 1175 PH_Tongeber_H_aktiv 0 "Tongeber hinten nicht aktiv" 1 "Tongeber hinten aktiv" ;
VAL_ 1175 PH_Tongeber_mute 0 "Tongeber nicht stummgeschaltet" 1 "Tongeber stummgeschaltet" ;
VAL_ 1175 PH_Anf_Audioabsenkung 0 "keine Absenkung der Lautstärke" 1 "Anforderung an das Audiosystem für Absenkung der Lautstärke" ;
VAL_ 1175 PH_Tongeber_H_verfuegbar 0 "nicht verfügbar" 1 "verfügbar" ;
VAL_ 1175 PLA_Anf_Aufschaltung_RVC 0 "Keine_RVC_Aufschalteanf" 1 "RVC_Aufschalteanforderung" ;
VAL_ 1175 PH_Taster 0 "Taster_nicht_gedrueckt" 1 "Taster_gedrueckt" 2 "reserviert" 3 "Fehler" ;
VAL_ 1175 PH_Anf_Verdeck 0 "Verdeckbetrieb_freigegeben" 1 "Verdeckbetrieb_sperren" 2 "reserviert" 3 "reserviert" ;
VAL_ 1175 PH_StartStopp_Info 0 "Motorlauf_nicht_notwendig_(Stoppfreigabe)" 1 "Motoranlauf_nicht_zwingend_notwendig_(Stoppverbot,keine_Startanforderung)" 2 "Motoranlauf_zwingend_notwendig_(Startanforderung)" 3 "Systemfehler" ;
VAL_ 1175 PH_Stoermeldung 0 "keine_Anzeige_kein_Gong" 1 "Textmeldung_PDC_hinten_gestoert_mit_Gong" 2 "Textmeldung_PDC_hinten_gestoert_ohne_Gong" 3 "Textmeldung_PDC_vorn_gestoert_mit_Gong" 4 "Textmeldung_PDC_vorn_gestoert_ohne_Gong" 5 "Textmeldung_PDC_gestoert_mit_Gong" 6 "Textmeldung_PDC_gestoert_ohne_Gong" 7 "Textmeldung_PDC_seitlich_gestoert_mit_Gong" 8 "Textmeldung_PDC_seitlich_gestoert_ohne_Gong" ;
VAL_ 1175 PH_defekt 0 "PH aktiv" 1 "PH wurde aufgrund eines Defektes deaktiviert" ;
VAL_ 1175 PH_gestoert 0 "PH aktiv" 1 "PH wurde auf Grund einer Stoerung tempraer deaktiviert" ;
VAL_ 1175 PH_Systemzustand 0 "Anlage aus" 1 "Anlage durch einlegen R-Gang aktiviert" 2 "Anlage manuell durch Taster aktiviert" 3 "Anlage automatisch aktiviert" 4 "Anlage durch ARA aktiviert" 6 "Init - Initialisierungsphase nach Kl. 15 ein / Reset" 7 "Fehler-/gestört Zustand, System noch aktiv" ;
VAL_ 1175 PH_Display_Kundenwunsch 0 "Anzeige aus" 1 "Grafik" 2 "Rear View" 3 "automatisch" ;
